VERSION "dbc-export 1 2026.26.6.5"

NS_ :

BS_:

BU_: APP BMS CC CMP CMPD CP DAS DI DIF DIR EPBL EPBR EVSE FC GTW HCML HCMR HVP ICR PCS PCS2 PLG PM PMF PMR PTC SCCM SCM SCS SDCR TAS UMC V2G VC VCBATT VCBATT0 VCBATT1 VCBATT2 VCFRONT VCFRONT1 VCFRONT2 VCLEFT VCRIGHT VCSEC

BO_ 611 VCRIGHT_logging10Hz: 8 VCRIGHT
 SG_ VCRIGHT_logging10HzIndex M : 0|3@1+ (1,0) [0|7] "" Vector__XXX
 SG_ VCRIGHT_hvacLHBleedTarget m0 : 3|8@1+ (0.4,0) [0|100] "%" Vector__XXX
 SG_ VCRIGHT_hvacRHBleedTarget m0 : 11|8@1+ (0.4,0) [0|100] "%" Vector__XXX
 SG_ VCRIGHT_hvacLHVaneTarget m0 : 19|8@1+ (0.4,0) [0|100] "%" Vector__XXX
 SG_ VCRIGHT_hvacRHVaneTarget m0 : 27|8@1+ (0.4,0) [0|100] "%" Vector__XXX
 SG_ VCRIGHT_hvacUpperModeTarget m0 : 35|10@1+ (0.1,0) [0|100] "%" Vector__XXX
 SG_ VCRIGHT_hvacLowerModeTarget m0 : 45|8@1+ (0.4,0) [0|100] "%" Vector__XXX
 SG_ VCRIGHT_hvacIntakeTarget m0 : 53|8@1+ (0.4,0) [0|100] "%" Vector__XXX
 SG_ VCRIGHT_hvacLHBleedPosition m1 : 3|8@1+ (0.4,0) [0|100] "%" Vector__XXX
 SG_ VCRIGHT_hvacRHBleedPosition m1 : 11|8@1+ (0.4,0) [0|100] "%" Vector__XXX
 SG_ VCRIGHT_hvacLHVanePosition m1 : 19|8@1+ (0.4,0) [0|100] "%" Vector__XXX
 SG_ VCRIGHT_hvacRHVanePosition m1 : 27|8@1+ (0.4,0) [0|100] "%" Vector__XXX
 SG_ VCRIGHT_hvacUpperModePosition m1 : 35|10@1+ (0.1,0) [0|100] "%" Vector__XXX
 SG_ VCRIGHT_hvacLowerModePosition m1 : 45|8@1+ (0.4,0) [0|100] "%" Vector__XXX
 SG_ VCRIGHT_hvacIntakePosition m1 : 53|8@1+ (0.4,0) [0|100] "%" Vector__XXX
 SG_ VCRIGHT_hvacLHBleedActuatorState m2 : 3|2@1+ (1,0) [0|3] "" Vector__XXX
 SG_ VCRIGHT_hvacRHBleedActuatorState m2 : 5|2@1+ (1,0) [0|3] "" Vector__XXX
 SG_ VCRIGHT_hvacLHVaneActuatorState m2 : 8|2@1+ (1,0) [0|3] "" Vector__XXX
 SG_ VCRIGHT_hvacRHVaneActuatorState m2 : 10|2@1+ (1,0) [0|3] "" Vector__XXX
 SG_ VCRIGHT_hvacUpperModeActState m2 : 12|2@1+ (1,0) [0|3] "" Vector__XXX
 SG_ VCRIGHT_hvacLowerModeActState m2 : 14|2@1+ (1,0) [0|3] "" Vector__XXX
 SG_ VCRIGHT_hvacIntakeActuatorState m2 : 16|2@1+ (1,0) [0|3] "" Vector__XXX
 SG_ VCRIGHT_hvacRearActuatorState m2 : 18|2@1+ (1,0) [0|3] "" Vector__XXX
 SG_ VCRIGHT_EvapPulldownBiasActive m2 : 20|1@1+ (1,0) [0|1] "" Vector__XXX
 SG_ VCRIGHT_tempDatLeftEst m2 : 21|9@1+ (0.5,-22) [-22|200] "degC" Vector__XXX
 SG_ VCRIGHT_tempDatRightEst m2 : 30|9@1+ (0.5,-22) [-22|200] "degC" Vector__XXX
 SG_ VCRIGHT_tempDuctLeftEst m2 : 40|8@1+ (0.5,-22) [-22|105] "degC" Vector__XXX
 SG_ VCRIGHT_tempDuctRightEst m2 : 48|8@1+ (0.5,-22) [-22|105] "degC" Vector__XXX
 SG_ VCRIGHT_ptcHeaterBadRodDetection m2 : 56|4@1+ (1,0) [0|15] "" Vector__XXX
 SG_ VCRIGHT_upperModeDrvActuatorStat m2 : 60|4@1+ (1,0) [0|15] "" Vector__XXX
 SG_ VCRIGHT_leftVerticalActuato_0001 m3 : 8|8@1+ (1,0) [0|255] "" Vector__XXX
 SG_ VCRIGHT_leftLateralActuatorStatu m3 : 16|8@1+ (1,0) [0|255] "" Vector__XXX
 SG_ VCRIGHT_rightVerticalActuat_0001 m3 : 24|8@1+ (1,0) [0|255] "" Vector__XXX
 SG_ VCRIGHT_rightLateralActuato_0001 m3 : 32|8@1+ (1,0) [0|255] "" Vector__XXX
 SG_ VCRIGHT_leftVerticalActuatorStat m3 : 40|4@1+ (1,0) [0|15] "" Vector__XXX
 SG_ VCRIGHT_leftLateralActuatorState m3 : 44|4@1+ (1,0) [0|15] "" Vector__XXX
 SG_ VCRIGHT_rightVerticalActuatorSta m3 : 48|4@1+ (1,0) [0|15] "" Vector__XXX
 SG_ VCRIGHT_rightLateralActuatorStat m3 : 52|4@1+ (1,0) [0|15] "" Vector__XXX
 SG_ VCRIGHT_windshieldRHExteriorSurf m3 : 56|8@1+ (1,0) [0|150] "%" Vector__XXX
 SG_ VCRIGHT_leftVerticalActuatorDuty m4 : 8|6@1- (4,0) [-100|100] "%" Vector__XXX
 SG_ VCRIGHT_leftLateralActuatorDuty m4 : 16|6@1- (4,0) [-100|100] "%" Vector__XXX
 SG_ VCRIGHT_rightVerticalActuatorDut m4 : 24|6@1- (4,0) [-100|100] "%" Vector__XXX
 SG_ VCRIGHT_rightLateralActuatorDuty m4 : 30|6@1- (4,0) [-100|100] "%" Vector__XXX
 SG_ VCRIGHT_frontLeftSeatTempTargetQ m4 : 36|6@1+ (0.75,20) [20|60] "degC" Vector__XXX
 SG_ VCRIGHT_frontRightSeatTempTarget m4 : 42|6@1+ (1,20) [20|60] "degC" Vector__XXX
 SG_ VCRIGHT_hvacRearPosition m4 : 48|8@1+ (0.4,0) [0|100] "%" Vector__XXX
 SG_ VCRIGHT_hvacRearTarget m4 : 56|8@1+ (0.4,0) [0|100] "%" Vector__XXX

BO_ 691 VCRIGHT_logging1Hz: 8 VCRIGHT
 SG_ VCRIGHT_logging1HzIndex M : 0|5@1+ (1,0) [0|31] "" Vector__XXX
 SG_ VCRIGHT_glareShieldHeaterState m0 : 5|3@1+ (1,0) [0|7] "" Vector__XXX
 SG_ VCRIGHT_tempIncarCabinProbe m0 : 8|8@1+ (0.5,-40) [-40|85] "degC" Vector__XXX
 SG_ VCRIGHT_cabinTempInteriorL2 m0 : 16|8@1+ (0.5,-40) [-40|80] "degC" Vector__XXX
 SG_ VCRIGHT_cabinTempInteriorSunnyL2 m0 : 24|8@1+ (0.6,-40) [-40|100] "degC" Vector__XXX
 SG_ VCRIGHT_tempIncarCabinMid m0 : 32|8@1+ (0.5,-40) [-40|85] "degC" Vector__XXX
 SG_ VCRIGHT_cabinTempInteriorL3 m0 : 40|8@1+ (0.5,-40) [-40|80] "degC" Vector__XXX
 SG_ VCRIGHT_cabinTempInteriorSunnyL3 m0 : 48|8@1+ (0.6,-40) [-40|100] "degC" Vector__XXX
 SG_ VCRIGHT_tempWetBulb m0 : 56|8@1+ (0.5,-40) [-40|80] "degC" Vector__XXX
 SG_ VCRIGHT_isRainingOrSnowing m1 : 5|1@1+ (1,0) [0|1] "" Vector__XXX
 SG_ VCRIGHT_cabinTempGlassRoof m1 : 8|8@1+ (0.5,-40) [-40|80] "degC" Vector__XXX
 SG_ VCRIGHT_cabinTempWindshield m1 : 16|8@1+ (0.5,-40) [-40|80] "degC" Vector__XXX
 SG_ VCRIGHT_cabinTempInterior m1 : 24|8@1+ (0.5,-40) [-40|80] "degC" Vector__XXX
 SG_ VCRIGHT_cabinTempInteriorSunny m1 : 32|8@1+ (0.6,-40) [-40|100] "degC" Vector__XXX
 SG_ VCRIGHT_cabinTempSideGlassLeft m1 : 40|8@1+ (0.5,-40) [-40|80] "degC" Vector__XXX
 SG_ VCRIGHT_cabinTempSideGlassRight m1 : 48|8@1+ (0.5,-40) [-40|80] "degC" Vector__XXX
 SG_ VCRIGHT_cabinTempBreathLevel m1 : 56|8@1+ (0.5,-40) [-40|80] "degC" Vector__XXX
 SG_ VCRIGHT_pcbaTemperature m2 : 5|11@1+ (0.125,-40) [-40|150] "degC" Vector__XXX
 SG_ VCRIGHT_wattsHeaterLeftTotal m2 : 16|10@1+ (5,0) [0|4000] "W" Vector__XXX
 SG_ VCRIGHT_wattsHeaterRightTotal m2 : 26|10@1+ (5,0) [0|4000] "W" Vector__XXX
 SG_ VCRIGHT_qdotLeftFFUnsat m2 : 36|9@1- (10,0) [-1500|1500] "W" Vector__XXX
 SG_ VCRIGHT_qdotRightFFUnsat m2 : 45|9@1- (10,0) [-1500|1500] "W" Vector__XXX
 SG_ VCRIGHT_nvhLevelDb m2 : 54|9@1+ (0.1,30) [30|80] "dB" Vector__XXX
 SG_ VCRIGHT_hvacSetTempActualLeft m3 : 8|8@1+ (0.1,15) [15|28] "degC" Vector__XXX
 SG_ VCRIGHT_hvacSetTempActualRight m3 : 16|8@1+ (0.1,15) [15|28] "degC" Vector__XXX
 SG_ VCRIGHT_hvacAutoTransitionReason m3 : 24|5@1+ (1,0) [0|31] "" Vector__XXX
 SG_ VCRIGHT_hvacMassflowTarget m3 : 29|8@1+ (1,0) [0|200] "g/s" Vector__XXX
 SG_ VCRIGHT_hvacQdotLimitedLeft m3 : 37|1@1+ (1,0) [0|1] "" Vector__XXX
 SG_ VCRIGHT_hvacQdotLimitedRight m3 : 38|1@1+ (1,0) [0|1] "" Vector__XXX
 SG_ VCRIGHT_LHPanelAirflowBlocked m3 : 39|1@1+ (1,0) [0|1] "" Vector__XXX
 SG_ VCRIGHT_RHPanelAirflowBlocked m3 : 40|1@1+ (1,0) [0|1] "" Vector__XXX
 SG_ VCRIGHT_floorAirflowBlocked m3 : 41|1@1+ (1,0) [0|1] "" Vector__XXX
 SG_ VCRIGHT_defrostAirflowBlocked m3 : 42|1@1+ (1,0) [0|1] "" Vector__XXX
 SG_ VCRIGHT_hvacFilterLifeDetectActi m3 : 43|1@1+ (1,0) [0|1] "" Vector__XXX
 SG_ VCRIGHT_hvacLHBleedOperationMode m3 : 44|1@1+ (1,0) [0|1] "" Vector__XXX
 SG_ VCRIGHT_hvacRHBleedOperationMode m3 : 45|1@1+ (1,0) [0|1] "" Vector__XXX
 SG_ VCRIGHT_hvacLHVaneOperationMode m3 : 46|1@1+ (1,0) [0|1] "" Vector__XXX
 SG_ VCRIGHT_hvacRHVaneOperationMode m3 : 47|1@1+ (1,0) [0|1] "" Vector__XXX
 SG_ VCRIGHT_hvacUpperModeOpMode m3 : 48|1@1+ (1,0) [0|1] "" Vector__XXX
 SG_ VCRIGHT_hvacLowerModeOpMode m3 : 49|1@1+ (1,0) [0|1] "" Vector__XXX
 SG_ VCRIGHT_hvacIntakeOperationMode m3 : 50|1@1+ (1,0) [0|1] "" Vector__XXX
 SG_ VCRIGHT_hvacRearOperationMode m3 : 51|1@1+ (1,0) [0|1] "" Vector__XXX
 SG_ VCRIGHT_isProbeFeedbackApplied m3 : 52|3@1+ (1,0) [0|7] "" Vector__XXX
 SG_ VCRIGHT_feedbackPullDownScalar m3 : 55|2@1+ (30,70) [70|130] "-" Vector__XXX
 SG_ VCRIGHT_feedForwardPullDownScala m3 : 57|6@1+ (1,70) [70|130] "-" Vector__XXX
 SG_ VCRIGHT_convectionTargetLeft m4 : 5|9@1+ (4,-1000) [-1000|1000] "W/m2" Vector__XXX
 SG_ VCRIGHT_convectionTargetRight m4 : 14|9@1+ (4,-1000) [-1000|1000] "W/m2" Vector__XXX
 SG_ VCRIGHT_convectionDeliveredLeft m4 : 23|9@1+ (4,-1000) [-1000|1000] "W/m2" Vector__XXX
 SG_ VCRIGHT_convectionDeliveredRight m4 : 32|9@1+ (4,-1000) [-1000|1000] "W/m2" Vector__XXX
 SG_ VCRIGHT_solarLoadRightOccupant m4 : 41|7@1+ (2,0) [0|252] "W/m2" Vector__XXX
 SG_ VCRIGHT_solarLoadLeftOccupant m4 : 48|7@1+ (2,0) [0|252] "W/m2" Vector__XXX
 SG_ VCRIGHT_ptcShutOutletMitigationA m4 : 55|1@1+ (1,0) [0|1] "" Vector__XXX
 SG_ VCRIGHT_solarLoadFromThsTemp m4 : 56|8@1+ (8,-1020) [-1020|1012] "W/m2" Vector__XXX
 SG_ VCRIGHT_hvacFoggingRiskLeve_0003 m5 : 5|6@1+ (1.6,0) [0|100] "%" Vector__XXX
 SG_ VCRIGHT_hvacFoggingRiskLeve_0004 m5 : 11|6@1+ (1.6,0) [0|100] "%" Vector__XXX
 SG_ VCRIGHT_hvacFoggingRiskLeve_0001 m5 : 17|6@1+ (1.6,0) [0|100] "%" Vector__XXX
 SG_ VCRIGHT_ptcHeaterTempDuctHigh m5 : 23|1@1+ (1,0) [0|1] "" Vector__XXX
 SG_ VCRIGHT_ptcHeaterTempDuctFault m5 : 24|1@1+ (1,0) [0|1] "" Vector__XXX
 SG_ VCRIGHT_ptcHeaterNoAirflow m5 : 25|1@1+ (1,0) [0|1] "" Vector__XXX
 SG_ VCRIGHT_ptcHeaterHvacActNotReady m5 : 26|1@1+ (1,0) [0|1] "" Vector__XXX
 SG_ VCRIGHT_ptcHeaterNoUiRequest m5 : 27|1@1+ (1,0) [0|1] "" Vector__XXX
 SG_ VCRIGHT_ptcHeaterNoHighVoltage m5 : 28|1@1+ (1,0) [0|1] "" Vector__XXX
 SG_ VCRIGHT_ptcHeaterLAirPathBlocked m5 : 29|1@1+ (1,0) [0|1] "" Vector__XXX
 SG_ VCRIGHT_ptcHeaterRAirPathBlocked m5 : 30|1@1+ (1,0) [0|1] "" Vector__XXX
 SG_ VCRIGHT_ptcHeaterReqAirpathBlock m5 : 31|1@1+ (1,0) [0|1] "" Vector__XXX
 SG_ VCRIGHT_hvacQdotFeedforward m5 : 32|16@1+ (1,-32767) [-32767|32767] "W" Vector__XXX
 SG_ VCRIGHT_cabinTempWshldDefog m5 : 48|8@1+ (0.5,-40) [-40|80] "degC" Vector__XXX
 SG_ VCRIGHT_cabinTempWshldDefogTop m5 : 56|8@1+ (0.5,-40) [-40|80] "degC" Vector__XXX
 SG_ VCRIGHT_hvacLHBleedVoltage m6 : 8|8@1+ (0.02,0) [0|5] "V" Vector__XXX
 SG_ VCRIGHT_hvacRHBleedVoltage m6 : 16|8@1+ (0.02,0) [0|5] "V" Vector__XXX
 SG_ VCRIGHT_hvacLHVaneVoltage m6 : 24|8@1+ (0.02,0) [0|5] "V" Vector__XXX
 SG_ VCRIGHT_hvacRHVaneVoltage m6 : 32|8@1+ (0.02,0) [0|5] "V" Vector__XXX
 SG_ VCRIGHT_hvacUpperModeVoltage m6 : 40|8@1+ (0.02,0) [0|5] "V" Vector__XXX
 SG_ VCRIGHT_hvacLowerModeVoltage m6 : 48|8@1+ (0.02,0) [0|5] "V" Vector__XXX
 SG_ VCRIGHT_hvacIntakeVoltage m6 : 56|8@1+ (0.02,0) [0|5] "V" Vector__XXX
 SG_ VCRIGHT_cabinTempBreathLevelFHea m7 : 5|8@1+ (0.5,-40) [-40|80] "degC" Vector__XXX
 SG_ VCRIGHT_cabinTempBreathLevelFCoo m7 : 13|8@1+ (0.5,-40) [-40|80] "degC" Vector__XXX
 SG_ VCRIGHT_hvacTorqueMassflowLinear m7 : 21|8@1+ (1,0) [0|250] "g/s" Vector__XXX
 SG_ VCRIGHT_hvacTorqueMassflowEstima m7 : 29|3@1+ (1,0) [0|7] "" Vector__XXX
 SG_ VCRIGHT_hvacFoggingRiskLevelCons m7 : 32|6@1+ (1.6,0) [0|100] "%" Vector__XXX
 SG_ VCRIGHT_hvacWindshieldRHConserva m7 : 38|6@1+ (2,0) [0|125] "%" Vector__XXX
 SG_ VCRIGHT_hvacFoggingRiskLevelFeed m7 : 44|7@1- (1.6,0) [-100|100] "%" Vector__XXX
 SG_ VCRIGHT_hvacFoggingRiskLevelInte m7 : 51|7@1- (1.6,0) [-100|100] "%" Vector__XXX
 SG_ VCRIGHT_hvacFoggingRiskLeve_0002 m7 : 58|6@1+ (1.6,0) [0|100] "%" Vector__XXX
 SG_ VCRIGHT_hvacCabOvrheatProtActive m8 : 5|1@1+ (1,0) [0|1] "" Vector__XXX
 SG_ VCRIGHT_hvacCabinPurgeAllowed m8 : 6|1@1+ (1,0) [0|1] "" Vector__XXX
 SG_ VCRIGHT_hvacCabOvrheatProtAllowe m8 : 7|1@1+ (1,0) [0|1] "" Vector__XXX
 SG_ VCRIGHT_AP_humidityModelBasedCab m8 : 8|10@1+ (0.04,0) [0|40] "g/kg" Vector__XXX
 SG_ VCRIGHT_cabinTempFanCurrent m8 : 18|6@1+ (0.001,-0.01) [-0.01|0.05] "A" Vector__XXX
 SG_ VCRIGHT_cabinTempFanOutput m8 : 24|1@1+ (1,0) [0|1] "" Vector__XXX
 SG_ VCRIGHT_cloudinessEstimatedPct m8 : 25|7@1+ (1,0) [0|100] "%" Vector__XXX
 SG_ VCRIGHT_solarLoadOnVehFiltered m8 : 32|8@1+ (4,0) [0|1016] "W/m2" Vector__XXX
 SG_ VCRIGHT_cabinTempProbeEstimate m8 : 40|8@1+ (0.5,-40) [-40|80] "degC" Vector__XXX
 SG_ VCRIGHT_cabinTempThs m8 : 48|8@1+ (0.5,-40) [-40|80] "degC" Vector__XXX
 SG_ VCRIGHT_cabinTempThsBracket m8 : 56|8@1+ (0.5,-40) [-40|80] "degC" Vector__XXX
 SG_ VCRIGHT_leftHeatOvertempProtect m9 : 5|1@1+ (1,0) [0|1] "" Vector__XXX
 SG_ VCRIGHT_rightHeatOvertempProtect m9 : 6|1@1+ (1,0) [0|1] "" Vector__XXX
 SG_ VCRIGHT_CO2ppm m9 : 7|10@1+ (5,0) [0|4000] "-" Vector__XXX
 SG_ VCRIGHT_timeLeftToCabinModelInit m9 : 17|7@1+ (1,0) [0|127] "" Vector__XXX
 SG_ VCRIGHT_hvacEstimateWindshieldRH m9 : 24|8@1+ (1,0) [0|150] "%" Vector__XXX
 SG_ VCRIGHT_hvacFoggingRiskLevel m9 : 32|7@1+ (1,0) [0|100] "%" Vector__XXX
 SG_ VCRIGHT_hvacCabinHumidityLevel m9 : 39|7@1+ (1,0) [0|100] "%" Vector__XXX
 SG_ VCRIGHT_hvacFlashFoggingDetected m9 : 47|1@1+ (1,0) [0|1] "" Vector__XXX
 SG_ VCRIGHT_solarSensitivityInfr m9 : 48|7@1+ (1,0) [0|100] "-" Vector__XXX
 SG_ VCRIGHT_solarSensitivityInfrCorr m9 : 55|7@1+ (1,0) [0|100] "-" Vector__XXX
 SG_ VCRIGHT_lumbarCurrent m10 : 5|4@1+ (0.2,0) [0|3] "A" Vector__XXX
 SG_ VCRIGHT_ocsCurrent m10 : 9|3@1+ (0.01,0) [0|0.07] "A" Vector__XXX
 SG_ VCRIGHT_rcmCurrent m10 : 12|5@1+ (0.1,0) [0|3.1] "A" Vector__XXX
 SG_ VCRIGHT_radioTunerCurrent m10 : 17|4@1+ (0.1,0) [0|1.5] "A" Vector__XXX
 SG_ VCRIGHT_rearOilPumpCurrent m10 : 21|5@1+ (0.5,0) [0|15.5] "A" Vector__XXX
 SG_ VCRIGHT_rearDefrostCurrent m10 : 26|5@1+ (2,0) [0|62] "A" Vector__XXX
 SG_ VCRIGHT_tailLightCurrent m10 : 31|4@1+ (0.1,0) [0|1.5] "A" Vector__XXX
 SG_ VCRIGHT_turnTailStopLightCurrent m10 : 35|4@1+ (0.1,0) [0|1.5] "A" Vector__XXX
 SG_ VCRIGHT_reverseFogLightsCurrent m10 : 39|4@1+ (0.1,0) [0|1.4] "A" Vector__XXX
 SG_ VCRIGHT_stopReverseTurnLightCurr m10 : 43|4@1+ (0.1,0) [0|1.5] "A" Vector__XXX
 SG_ VCRIGHT_sideMirrorCurrent m10 : 47|5@1+ (0.2,0) [0|6.2] "A" Vector__XXX
 SG_ VCRIGHT_sideMirrorHeaterCurrent m10 : 52|5@1+ (0.2,0) [0|6] "A" Vector__XXX
 SG_ VCRIGHT_frontSeatHeatCushionPwr m10 : 57|7@1+ (1,0) [0|127] "W" Vector__XXX
 SG_ VCRIGHT_trunkInteriorLEDCurrent m11 : 8|4@1+ (5,0) [0|70] "mA" Vector__XXX
 SG_ VCRIGHT_mapPocketLEDsCurrent m11 : 12|4@1+ (5,0) [0|70] "mA" Vector__XXX
 SG_ VCRIGHT_miscEFuseCurrent m11 : 16|5@1+ (0.05,0) [0|1.5] "A" Vector__XXX
 SG_ VCRIGHT_interiorHandleLEDCurrent m11 : 21|4@1+ (2,0) [0|30] "mA" Vector__XXX
 SG_ VCRIGHT_miscInteriorLightsCurren m11 : 25|3@1+ (5,0) [0|30] "mA" Vector__XXX
 SG_ VCRIGHT_frontPuddleLEDCurrent m11 : 28|3@1+ (0.05,0) [0|0.3] "A" Vector__XXX
 SG_ VCRIGHT_rearPuddleLEDCurrent m11 : 31|3@1+ (0.05,0) [0|0.3] "A" Vector__XXX
 SG_ VCRIGHT_liftgateShutfaceLEDCurre m11 : 34|3@1+ (5,0) [0|30] "mA" Vector__XXX
 SG_ VCRIGHT_3rSeatTOSCurrent m11 : 37|4@1+ (5,0) [0|70] "mA" Vector__XXX
 SG_ VCRIGHT_vbatFusedCurrent m11 : 41|4@1+ (0.1,0) [0|1.4] "A" Vector__XXX
 SG_ VCRIGHT_cabinTempGlassGridHeater m11 : 45|8@1+ (0.5,-40) [-40|80] "degC" Vector__XXX
 SG_ VCRIGHT_hvacAirflowReasonRight m11 : 53|5@1+ (1,0) [0|31] "" Vector__XXX
 SG_ VCRIGHT_hvacAirflowReasonLeft m11 : 58|5@1+ (1,0) [0|31] "" Vector__XXX
 SG_ VCRIGHT_hvacMassflowTargetLeft m12 : 5|8@1+ (1,0) [0|200] "g/s" Vector__XXX
 SG_ VCRIGHT_hvacMassflowTargetRight m12 : 13|8@1+ (1,0) [0|200] "g/s" Vector__XXX
 SG_ VCRIGHT_solarLoadLeftOccupantFil m12 : 21|7@1+ (2,0) [0|252] "W/m2" Vector__XXX
 SG_ VCRIGHT_solarLoadRightOccupantFi m12 : 28|7@1+ (2,0) [0|252] "W/m2" Vector__XXX
 SG_ VCRIGHT_windshieldRHCapped m12 : 35|8@1+ (1,0) [0|150] "%" Vector__XXX
 SG_ VCRIGHT_feedbackWarmUpScalar m12 : 43|2@1+ (16,84) [84|116] "-" Vector__XXX
 SG_ VCRIGHT_maxMassflowScalarWarmUp m12 : 45|5@1+ (1,74) [74|100] "-" Vector__XXX
 SG_ VCRIGHT_feedforwardWarmUpScalar m12 : 50|6@1+ (1,80) [80|120] "-" Vector__XXX
 SG_ VCRIGHT_frontSeatHeatBackrestPwr m12 : 56|7@1+ (1,0) [0|127] "W" Vector__XXX
 SG_ VCRIGHT_maxMassflowScalar m13 : 5|6@1+ (1,60) [60|100] "-" Vector__XXX
 SG_ VCRIGHT_massflowTargetAutoInManu m13 : 11|8@1+ (1,0) [0|250] "g/s" Vector__XXX
 SG_ VCRIGHT_airflowReasonAutoInManua m13 : 19|5@1+ (1,0) [0|31] "" Vector__XXX
 SG_ VCRIGHT_airflowReasonAutoIn_0001 m13 : 24|5@1+ (1,0) [0|31] "" Vector__XXX
 SG_ VCRIGHT_airflowReasonAutoIn_0002 m13 : 29|5@1+ (1,0) [0|31] "" Vector__XXX
 SG_ VCRIGHT_hvacTorqueMassflowQuadra m13 : 34|8@1+ (1,0) [0|250] "g/s" Vector__XXX
 SG_ VCRIGHT_vocSweatMassSeat m13 : 42|8@1+ (1,0) [0|254] "mg" Vector__XXX
 SG_ VCRIGHT_vocSweatConcentrationAir m13 : 50|8@1+ (0.1,0) [0|25.4] "mg/m3" Vector__XXX
 SG_ VCRIGHT_hvacBiLevelWhsldRhEst m13 : 58|6@1+ (2,20) [20|120] "%" Vector__XXX
 SG_ VCRIGHT_steeringWheelSurfaceTemp m14 : 5|10@1+ (0.1,-35) [-35|65] "degC" Vector__XXX
 SG_ VCRIGHT_steeringWheelSurfac_0001 m14 : 16|10@1+ (0.1,-35) [-35|65] "degC" Vector__XXX
 SG_ VCRIGHT_timeToComfortHeating m14 : 26|6@1+ (15,-15) [-15|930] "s" Vector__XXX
 SG_ VCRIGHT_timeToComfortCooling m14 : 32|6@1+ (15,-15) [-15|930] "s" Vector__XXX
 SG_ VCRIGHT_cabinWaterMassRaw m14 : 38|8@1+ (0.1,0) [0|25] "g/kg" Vector__XXX
 SG_ VCRIGHT_massflowSingleZoneSplit m14 : 46|7@1+ (1,0) [0|100] "-" Vector__XXX
 SG_ VCRIGHT_VOCPurgeState m14 : 53|3@1+ (1,0) [0|7] "" Vector__XXX
 SG_ VCRIGHT_cameraFoggingMonitorStat m14 : 56|3@1+ (1,0) [0|7] "" Vector__XXX
 SG_ VCRIGHT_windWeatherSource m14 : 59|2@1+ (1,0) [0|3] "" Vector__XXX
 SG_ VCRIGHT_humidityRatioWeatherSour m14 : 61|2@1+ (1,0) [0|3] "" Vector__XXX
 SG_ VCRIGHT_cabinOverheatProtectNotR m15 : 5|14@1+ (1,0) [0|16383] "" Vector__XXX
 SG_ VCRIGHT_hvacIntakeReason m15 : 19|5@1+ (1,0) [0|31] "" Vector__XXX
 SG_ VCRIGHT_hvacCabinPurgeActive m15 : 24|1@1+ (1,0) [0|1] "" Vector__XXX
 SG_ VCRIGHT_solarAzimuthCarRef m15 : 25|11@1- (0.5,0) [-511|511.5] "deg" Vector__XXX
 SG_ VCRIGHT_massflowPulldownBias m15 : 36|4@1+ (7,0) [0|100] "%" Vector__XXX
 SG_ VCRIGHT_evapPulldownBias m15 : 40|4@1+ (7,0) [0|100] "%" Vector__XXX
 SG_ VCRIGHT_modeledMassflowFresh m15 : 44|8@1+ (1,0) [0|255] "g/s" Vector__XXX
 SG_ VCRIGHT_modeledMassflowRecirc m15 : 52|8@1+ (1,0) [0|255] "g/s" Vector__XXX
 SG_ VCRIGHT_hvacLimpModeStatus m15 : 60|3@1+ (1,0) [0|7] "" Vector__XXX
 SG_ VCRIGHT_hvacEstimatedCameraWinds m16 : 5|8@1+ (1,0) [0|150] "%" Vector__XXX
 SG_ VCRIGHT_hvacRearVoltage m16 : 13|8@1+ (0.02,0) [0|5] "V" Vector__XXX
 SG_ VCRIGHT_cabinTempRoofL2 m16 : 21|8@1+ (0.5,-40) [-40|85] "degC" Vector__XXX
 SG_ VCRIGHT_cabinTempRoofL3 m16 : 29|8@1+ (0.5,-40) [-40|85] "degC" Vector__XXX
 SG_ VCRIGHT_odorRoutineState m16 : 37|3@1+ (1,0) [0|6] "" Vector__XXX
 SG_ VCRIGHT_rgbLedFrontCurrent m16 : 40|10@1+ (0.000488758552819,0) [0|0.499999999534] "A" Vector__XXX
 SG_ VCRIGHT_rgbLedRearCurrent m16 : 50|10@1+ (0.000488758552819,0) [0|0.499999999534] "A" Vector__XXX
 SG_ VCRIGHT_rgbLedFrontOutput m16 : 60|1@1+ (1,0) [0|1] "" Vector__XXX
 SG_ VCRIGHT_rgbLedRearOutput m16 : 61|1@1+ (1,0) [0|1] "" Vector__XXX
 SG_ VCRIGHT_cameraDefogState m16 : 62|2@1+ (1,0) [0|3] "" Vector__XXX

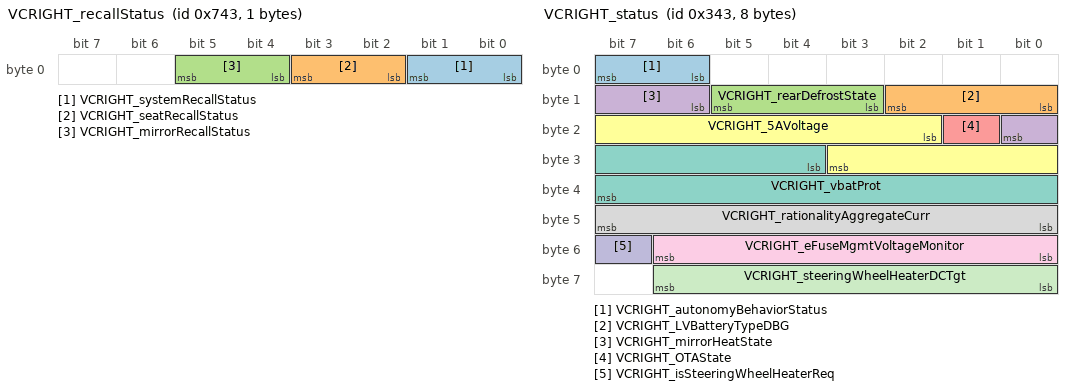
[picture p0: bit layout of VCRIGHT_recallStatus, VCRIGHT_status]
BO_ 1859 VCRIGHT_recallStatus: 1 VCRIGHT
 SG_ VCRIGHT_systemRecallStatus : 0|2@1+ (1,0) [1|3] "" Vector__XXX
 SG_ VCRIGHT_seatRecallStatus : 2|2@1+ (1,0) [1|3] "" Vector__XXX
 SG_ VCRIGHT_mirrorRecallStatus : 4|2@1+ (1,0) [1|3] "" Vector__XXX

BO_ 1251 VCRIGHT_seatStatus: 8 VCRIGHT
 SG_ VCRIGHT_seatStatusIndex M : 0|3@1+ (1,0) [0|7] "" Vector__XXX
 SG_ VC_AH_1RowRightSeatMovementHealt m0 : 5|3@1+ (1,0) [0|7] "" Vector__XXX
 SG_ VCRIGHT_frontSeatTrackPos m0 : 8|16@1- (1,0) [-32768|32767] "" Vector__XXX
 SG_ VCRIGHT_frontSeatTrackCurrent m0 : 24|12@1- (0.01,0) [-20.48|20.47] "A" Vector__XXX
 SG_ VCRIGHT_frontSeatTrackDuty m0 : 36|12@1- (0.1,0) [-204.8|204.7] "%" Vector__XXX
 SG_ VCRIGHT_frontSeatTrackState m0 : 48|3@1+ (1,0) [0|7] "" Vector__XXX
 SG_ VCRIGHT_frontSeatTrackCalibrated m0 : 51|1@1+ (1,0) [0|1] "" Vector__XXX
 SG_ VCRIGHT_frontSeatTrackLog m0 : 52|1@1+ (1,0) [0|1] "" Vector__XXX
 SG_ VCRIGHT_frontSeatTrackBridgeSt m0 : 53|2@1+ (1,0) [0|3] "" Vector__XXX
 SG_ VCRIGHT_frontSeatTrackPercentage m0 : 55|7@1+ (1,0) [0|100] "%" Vector__XXX
 SG_ VCRIGHT_frontSeatBackPos m1 : 8|16@1- (1,0) [-32768|32767] "" Vector__XXX
 SG_ VCRIGHT_frontSeatBackCurrent m1 : 24|12@1- (0.01,0) [-20.48|20.47] "A" Vector__XXX
 SG_ VCRIGHT_frontSeatBackDuty m1 : 36|12@1- (0.1,0) [-204.8|204.7] "%" Vector__XXX
 SG_ VCRIGHT_frontSeatBackState m1 : 48|3@1+ (1,0) [0|7] "" Vector__XXX
 SG_ VCRIGHT_frontSeatBackCalibrated m1 : 51|1@1+ (1,0) [0|1] "" Vector__XXX
 SG_ VCRIGHT_frontSeatBackLog m1 : 52|1@1+ (1,0) [0|1] "" Vector__XXX
 SG_ VCRIGHT_frontSeatBackBridgeSt m1 : 53|2@1+ (1,0) [0|3] "" Vector__XXX
 SG_ VCRIGHT_frontSeatBackPercentage m1 : 55|7@1+ (1,0) [0|100] "%" Vector__XXX
 SG_ VCRIGHT_frontSeatLiftPos m2 : 8|16@1- (1,0) [-32768|32767] "" Vector__XXX
 SG_ VCRIGHT_frontSeatLiftCurrent m2 : 24|12@1- (0.01,0) [-20.48|20.47] "A" Vector__XXX
 SG_ VCRIGHT_frontSeatLiftDuty m2 : 36|12@1- (0.1,0) [-204.8|204.7] "%" Vector__XXX
 SG_ VCRIGHT_frontSeatLiftState m2 : 48|3@1+ (1,0) [0|7] "" Vector__XXX
 SG_ VCRIGHT_frontSeatLiftCalibrated m2 : 51|1@1+ (1,0) [0|1] "" Vector__XXX
 SG_ VCRIGHT_frontSeatLiftLog m2 : 52|1@1+ (1,0) [0|1] "" Vector__XXX
 SG_ VCRIGHT_frontSeatLiftBridgeSt m2 : 53|2@1+ (1,0) [0|3] "" Vector__XXX
 SG_ VCRIGHT_frontSeatLiftPercentage m2 : 55|7@1+ (1,0) [0|100] "%" Vector__XXX
 SG_ VCRIGHT_frontSeatTiltPos m3 : 8|16@1- (1,0) [-32768|32767] "" Vector__XXX
 SG_ VCRIGHT_frontSeatTiltCurrent m3 : 24|12@1- (0.01,0) [-20.48|20.47] "A" Vector__XXX
 SG_ VCRIGHT_frontSeatTiltDuty m3 : 36|12@1- (0.1,0) [-204.8|204.7] "%" Vector__XXX
 SG_ VCRIGHT_frontSeatTiltState m3 : 48|3@1+ (1,0) [0|7] "" Vector__XXX
 SG_ VCRIGHT_frontSeatTiltCalibrated m3 : 51|1@1+ (1,0) [0|1] "" Vector__XXX
 SG_ VCRIGHT_frontSeatTiltLog m3 : 52|1@1+ (1,0) [0|1] "" Vector__XXX
 SG_ VCRIGHT_frontSeatTiltBridgeSt m3 : 53|2@1+ (1,0) [0|3] "" Vector__XXX
 SG_ VCRIGHT_frontSeatTiltPercentage m3 : 55|7@1+ (1,0) [0|100] "%" Vector__XXX
 SG_ VCRIGHT_lumbarAState m4 : 3|3@1+ (1,0) [0|7] "" Vector__XXX
 SG_ VCRIGHT_lumbarBState m4 : 6|3@1+ (1,0) [0|7] "" Vector__XXX
 SG_ VCRIGHT_lumbarAPressureHpa m4 : 9|12@1+ (1,0) [0|4095] "" Vector__XXX
 SG_ VCRIGHT_lumbarAPressureHpaFilt m4 : 21|10@1+ (1,0) [0|1023] "" Vector__XXX
 SG_ VCRIGHT_lumbarBPressureHpa m4 : 31|12@1+ (1,0) [0|4095] "" Vector__XXX
 SG_ VCRIGHT_lumbarBPressureHpaFilt m4 : 43|10@1+ (1,0) [0|1023] "" Vector__XXX
 SG_ VCRIGHT_lumbarActiveTooLongErr m4 : 53|1@1+ (1,0) [0|1] "" Vector__XXX
 SG_ VCRIGHT_lumbarMaxPErr m4 : 54|1@1+ (1,0) [0|1] "" Vector__XXX
 SG_ VCRIGHT_lumbarOvercurrentErr m4 : 55|1@1+ (1,0) [0|1] "" Vector__XXX
 SG_ VCRIGHT_lumbarMaxOperatingPErr m4 : 56|1@1+ (1,0) [0|1] "" Vector__XXX
 SG_ VCRIGHT_lumbarMinPErr m4 : 57|1@1+ (1,0) [0|1] "" Vector__XXX
 SG_ VCRIGHT_lumbarGeneralErr m4 : 58|1@1+ (1,0) [0|1] "" Vector__XXX
 SG_ VCRIGHT_lumbarDevMaxPumpPressA m4 : 59|1@1+ (1,0) [0|1] "" Vector__XXX
 SG_ VCRIGHT_lumbarDevMaxPumpPressB m4 : 60|1@1+ (1,0) [0|1] "" Vector__XXX
 SG_ VCRIGHT_frontSeatTrackPosReal m5 : 3|12@1- (1,0) [-2048|2047] "mm" Vector__XXX
 SG_ VCRIGHT_frontSeatBackPosReal m5 : 16|12@1- (0.1,0) [-204.8|204.7] "deg" Vector__XXX
 SG_ VCRIGHT_frontSeatLiftPosReal m5 : 28|12@1- (1,0) [-2048|2047] "mm" Vector__XXX
 SG_ VCRIGHT_frontSeatTiltPosReal m5 : 40|12@1- (0.1,0) [-204.8|204.7] "deg" Vector__XXX
 SG_ VCRIGHT_frontSeatThighSuppo_0001 m5 : 52|12@1- (1,0) [-2048|2047] "mm" Vector__XXX
 SG_ VCRIGHT_frontSeatTrackPosOffset m6 : 3|12@1- (1,0) [-2048|2047] "mm" Vector__XXX
 SG_ VCRIGHT_frontSeatBackPosOffset m6 : 16|12@1- (0.1,0) [-204.8|204.7] "deg" Vector__XXX
 SG_ VCRIGHT_frontSeatLiftPosOffset m6 : 28|12@1- (1,0) [-2048|2047] "mm" Vector__XXX
 SG_ VCRIGHT_frontSeatTiltPosOffset m6 : 40|12@1- (0.1,0) [-204.8|204.7] "deg" Vector__XXX
 SG_ VCRIGHT_frontSeatThighSupportPos m6 : 52|12@1- (1,0) [-2048|2047] "mm" Vector__XXX
 SG_ VCRIGHT_lumbarAPressurePercentag m7 : 3|7@1+ (1,0) [0|100] "%" Vector__XXX
 SG_ VCRIGHT_lumbarBPressurePercentag m7 : 10|7@1+ (1,0) [0|100] "%" Vector__XXX

BO_ 739 VCRIGHT_seatStatus2: 7 VCRIGHT
 SG_ VCRIGHT_seatStatus2Index M : 0|4@1+ (1,0) [0|15] "" Vector__XXX
 SG_ VCRIGHT_frontSeatHeatCurrent m0 : 4|12@1+ (0.01,0) [0|40.95] "A" Vector__XXX
 SG_ VCRIGHT_frontSeatHeatDuty m0 : 16|8@1+ (1,0) [0|255] "%" Vector__XXX
 SG_ VCRIGHT_frontSeatHeatTmp m0 : 24|12@1- (0.05,0) [-40|80] "degC" Vector__XXX
 SG_ VCRIGHT_frontSeatHeatTmpTarget m0 : 36|8@1- (0.5,0) [0|60] "degC" Vector__XXX
 SG_ VCRIGHT_frontSeatHeatInhibited m0 : 44|1@1+ (1,0) [0|1] "" Vector__XXX
 SG_ VCRIGHT_frontSeatHeatPowered m0 : 45|1@1+ (1,0) [0|1] "" Vector__XXX
 SG_ VC_AH_1RowRightSeatHeatVentHealt m0 : 54|2@1+ (1,0) [0|3] "" Vector__XXX
 SG_ VCRIGHT_rearLSeatHeatCurrent m1 : 4|12@1+ (0.01,0) [0|40.95] "A" Vector__XXX
 SG_ VCRIGHT_rearLSeatHeatDuty m1 : 16|8@1+ (1,0) [0|255] "%" Vector__XXX
 SG_ VCRIGHT_rearLSeatHeatTmp m1 : 24|12@1- (0.05,0) [-40|80] "degC" Vector__XXX
 SG_ VCRIGHT_rearLSeatHeatTmpTarget m1 : 36|8@1- (0.5,0) [0|60] "degC" Vector__XXX
 SG_ VCRIGHT_rearLSeatHeatInhibited m1 : 44|1@1+ (1,0) [0|1] "" Vector__XXX
 SG_ VCRIGHT_rearLSeatHeatPowered m1 : 45|1@1+ (1,0) [0|1] "" Vector__XXX
 SG_ VCRIGHT_rearCSeatHeatCurrent m2 : 4|12@1+ (0.01,0) [0|40.95] "A" Vector__XXX
 SG_ VCRIGHT_rearCSeatHeatDuty m2 : 16|8@1+ (1,0) [0|255] "%" Vector__XXX
 SG_ VCRIGHT_rearCSeatHeatTmp m2 : 24|12@1- (0.05,0) [-40|80] "degC" Vector__XXX
 SG_ VCRIGHT_rearCSeatHeatTmpTarget m2 : 36|8@1- (0.5,0) [0|60] "degC" Vector__XXX
 SG_ VCRIGHT_rearCSeatHeatInhibited m2 : 44|1@1+ (1,0) [0|1] "" Vector__XXX
 SG_ VCRIGHT_rearCSeatHeatPowered m2 : 45|1@1+ (1,0) [0|1] "" Vector__XXX
 SG_ VCRIGHT_rearRSeatHeatCurrent m3 : 4|12@1+ (0.01,0) [0|40.95] "A" Vector__XXX
 SG_ VCRIGHT_rearRSeatHeatDuty m3 : 16|8@1+ (1,0) [0|255] "%" Vector__XXX
 SG_ VCRIGHT_rearRSeatHeatTmp m3 : 24|12@1- (0.05,0) [-40|80] "degC" Vector__XXX
 SG_ VCRIGHT_rearRSeatHeatTmpTarget m3 : 36|8@1- (0.5,0) [0|60] "degC" Vector__XXX
 SG_ VCRIGHT_rearRSeatHeatInhibited m3 : 44|1@1+ (1,0) [0|1] "" Vector__XXX
 SG_ VCRIGHT_rearRSeatHeatPowered m3 : 45|1@1+ (1,0) [0|1] "" Vector__XXX
 SG_ VCRIGHT_2RowSeatReclineState m11 : 4|4@1+ (1,0) [0|14] "" Vector__XXX
 SG_ VCRIGHT_2RowSeatReclineDuty m11 : 8|8@1- (1,0) [-100|100] "%" Vector__XXX
 SG_ VCRIGHT_2RowSeatReclineCurrent m11 : 16|12@1- (0.05,0) [-100|100] "A" Vector__XXX
 SG_ VCRIGHT_2RowSeatReclineCalibrate m11 : 28|1@1+ (1,0) [0|1] "" Vector__XXX
 SG_ VCRIGHT_2RowSeatReclinePositionR m11 : 29|12@1- (1,0) [-2048|2047] "" Vector__XXX
 SG_ VCRIGHT_2RowSeatReclineAngle m11 : 41|12@1- (0.1,0) [-204.8|204.7] "deg" Vector__XXX
 SG_ VCRIGHT_2RowSeatReclineAbsPosSwi m11 : 53|2@1+ (1,0) [1|3] "" Vector__XXX
 SG_ VCRIGHT_2RowSeatReclinePositionS m12 : 4|3@1+ (1,0) [0|7] "" Vector__XXX
 SG_ VCRIGHT_2RowSeatReclineAdjustmen m12 : 7|1@1+ (1,0) [0|1] "" Vector__XXX
 SG_ VCRIGHT_2RowSeatReclineFoldAllow m12 : 8|1@1+ (1,0) [0|1] "" Vector__XXX
 SG_ VCRIGHT_2RowSeatReclineUnfoldAll m12 : 9|1@1+ (1,0) [0|1] "" Vector__XXX
 SG_ VCRIGHT_2RowSeatReclineNextToggl m12 : 10|2@1+ (1,0) [0|3] "" Vector__XXX
 SG_ VCRIGHT_2RowSeatReclineChoreoBlo m12 : 12|1@1+ (1,0) [0|1] "" Vector__XXX
 SG_ VCRIGHT_2RowSeat1RClashAvoidance m12 : 13|3@1+ (1,0) [0|7] "" Vector__XXX
 SG_ VCRIGHT_2RowSeat1RClashAvoi_0001 m12 : 16|2@1+ (1,0) [0|3] "" Vector__XXX
 SG_ VCRIGHT_2RowSeatReclineAbsP_0001 m12 : 18|12@1- (0.1,0) [-204.8|204.7] "deg" Vector__XXX
 SG_ VC_AH_2RowRightSeatMovementHealt m12 : 53|3@1+ (1,0) [0|7] "" Vector__XXX
 SG_ VCRIGHT_3RowSeatReclineState m14 : 4|4@1+ (1,0) [0|14] "" Vector__XXX
 SG_ VCRIGHT_3RowSeatReclineDuty m14 : 8|8@1- (1,0) [-100|100] "%" Vector__XXX
 SG_ VCRIGHT_3RowSeatReclineCurrent m14 : 16|12@1- (0.05,0) [-100|100] "A" Vector__XXX
 SG_ VCRIGHT_3RowSeatReclineCalibrate m14 : 28|1@1+ (1,0) [0|1] "" Vector__XXX
 SG_ VCRIGHT_3RowSeatReclinePositionR m14 : 29|12@1- (1,0) [-2048|2047] "" Vector__XXX
 SG_ VCRIGHT_3RowSeatReclineAngle m14 : 41|12@1- (0.1,0) [-204.8|204.7] "deg" Vector__XXX
 SG_ VCRIGHT_3RowSeatReclineNextToggl m14 : 53|2@1+ (1,0) [0|3] "" Vector__XXX
 SG_ VCRIGHT_3RRightSeatHeatCurrent m15 : 5|12@1+ (0.01,0) [0|40.95] "A" Vector__XXX
 SG_ VCRIGHT_3RRightSeatHeatDuty m15 : 17|8@1- (1,0) [-100|100] "%" Vector__XXX
 SG_ VCRIGHT_3RRightSeatHeatTmp m15 : 25|12@1- (0.05,0) [-40|80] "degC" Vector__XXX
 SG_ VCRIGHT_3RRightSeatHeatTmpTarget m15 : 37|8@1- (0.5,0) [0|60] "degC" Vector__XXX
 SG_ VCRIGHT_3RRightSeatHeatInhibited m15 : 45|1@1+ (1,0) [0|1] "" Vector__XXX
 SG_ VCRIGHT_3RowSeatReclinePositionS m15 : 46|3@1+ (1,0) [0|7] "" Vector__XXX
 SG_ VCRIGHT_3RowSeatReclineAdjustmen m15 : 49|1@1+ (1,0) [0|1] "" Vector__XXX
 SG_ VCRIGHT_3RowSeatReclineFoldAllow m15 : 50|1@1+ (1,0) [0|1] "" Vector__XXX
 SG_ VCRIGHT_3RowSeatReclineUnfoldAll m15 : 51|1@1+ (1,0) [0|1] "" Vector__XXX
 SG_ VCRIGHT_3RowSeatReclineChoreoBlo m15 : 52|1@1+ (1,0) [0|1] "" Vector__XXX
 SG_ VCRIGHT_3RowSeatReclineAbsPosSwi m15 : 53|2@1+ (1,0) [1|3] "" Vector__XXX

BO_ 835 VCRIGHT_status: 8 VCRIGHT
 SG_ VCRIGHT_autonomyBehaviorStatus : 6|2@1+ (1,0) [0|3] "" Vector__XXX
 SG_ VCRIGHT_LVBatteryTypeDBG : 8|3@1+ (1,0) [0|7] "" Vector__XXX
 SG_ VCRIGHT_rearDefrostState : 11|3@1+ (1,0) [1|7] "" Vector__XXX
 SG_ VCRIGHT_mirrorHeatState : 14|3@1+ (1,0) [1|7] "" Vector__XXX
 SG_ VCRIGHT_OTAState : 17|1@1+ (1,0) [0|1] "" Vector__XXX
 SG_ VCRIGHT_5AVoltage : 18|10@1+ (0.005443676,0) [0|5.568880548] "V" Vector__XXX
 SG_ VCRIGHT_vbatProt : 28|12@1+ (0.005443676,0) [0|22.29185322] "V" Vector__XXX
 SG_ VCRIGHT_rationalityAggregateCurr : 40|8@1+ (0.5,0) [0|127.5] "A" Vector__XXX
 SG_ VCRIGHT_eFuseMgmtVoltageMonitor : 48|7@1+ (0.125,0) [0|15.875] "V" Vector__XXX
 SG_ VCRIGHT_isSteeringWheelHeaterReq : 55|1@1+ (1,0) [0|1] "" Vector__XXX
 SG_ VCRIGHT_steeringWheelHeaterDCTgt : 56|7@1+ (0.01,0) [0|1] "-" Vector__XXX

BO_ 963 VCRIGHT_switchStatus: 8 VCRIGHT
 SG_ VCRIGHT_switchStatusIndex M : 0|1@1+ (1,0) [0|1] "" Vector__XXX
 SG_ VCRIGHT_frontBuckleSwitch m0 : 40|2@1+ (1,0) [0|3] "" Vector__XXX
 SG_ VCRIGHT_rearCenterBuckleSwitch m0 : 44|2@1+ (1,0) [0|3] "" Vector__XXX
 SG_ VCRIGHT_rearRightBuckleSwitch m0 : 46|2@1+ (1,0) [0|3] "" Vector__XXX
 SG_ VCRIGHT_trunkExtReleasePressedPe m1 : 1|1@1+ (1,0) [0|1] "" Vector__XXX
 SG_ VCRIGHT_frontSeatTrackBack m1 : 2|2@1+ (1,0) [1|3] "" Vector__XXX
 SG_ VCRIGHT_frontSeatTrackForward m1 : 4|2@1+ (1,0) [1|3] "" Vector__XXX
 SG_ VCRIGHT_frontSeatTiltDown m1 : 6|2@1+ (1,0) [1|3] "" Vector__XXX
 SG_ VCRIGHT_frontSeatTiltUp m1 : 8|2@1+ (1,0) [1|3] "" Vector__XXX
 SG_ VCRIGHT_frontSeatLiftDown m1 : 10|2@1+ (1,0) [1|3] "" Vector__XXX
 SG_ VCRIGHT_frontSeatLiftUp m1 : 12|2@1+ (1,0) [1|3] "" Vector__XXX
 SG_ VCRIGHT_frontSeatBackrestBack m1 : 14|2@1+ (1,0) [1|3] "" Vector__XXX
 SG_ VCRIGHT_frontSeatBackrestForward m1 : 16|2@1+ (1,0) [1|3] "" Vector__XXX
 SG_ VCRIGHT_frontSeatLumbarDown m1 : 18|2@1+ (1,0) [1|3] "" Vector__XXX
 SG_ VCRIGHT_frontSeatLumbarUp m1 : 20|2@1+ (1,0) [1|3] "" Vector__XXX
 SG_ VCRIGHT_frontSeatLumbarIn m1 : 22|2@1+ (1,0) [1|3] "" Vector__XXX
 SG_ VCRIGHT_frontSeatLumbarOut m1 : 24|2@1+ (1,0) [1|3] "" Vector__XXX
 SG_ VCRIGHT_2RowSeatReclineSwitch m1 : 26|1@1+ (1,0) [0|1] "" Vector__XXX
 SG_ VCRIGHT_2RowSeatBackrestFoldSwit m1 : 27|1@1+ (1,0) [0|1] "" Vector__XXX
 SG_ VCRIGHT_frontSeatThighSupportExt m1 : 30|2@1+ (1,0) [1|3] "" Vector__XXX
 SG_ VCRIGHT_frontHandlePWM m1 : 32|7@1+ (1,0) [0|100] "%" Vector__XXX
 SG_ VCRIGHT_hvacHeatingAllowedLeft m1 : 39|1@1+ (1,0) [0|1] "" Vector__XXX
 SG_ VCRIGHT_rearHandlePWM m1 : 40|7@1+ (1,0) [0|100] "%" Vector__XXX
 SG_ VCRIGHT_gloveboxLightCurrent m1 : 47|5@1+ (2,0) [0|62] "mA" Vector__XXX
 SG_ VCRIGHT_frontSeatALR m1 : 52|2@1+ (1,0) [1|3] "" Vector__XXX
 SG_ VCRIGHT_frontSeatResistiveOccupa m1 : 54|2@1+ (1,0) [1|3] "" Vector__XXX
 SG_ VCRIGHT_2RowSeatReclineSwitchpac m1 : 56|3@1+ (1,0) [0|7] "" Vector__XXX
 SG_ VCRIGHT_hvacHeatingAllowedRight m1 : 59|1@1+ (1,0) [0|1] "" Vector__XXX
 SG_ VCRIGHT_frontSeatThighSupportRet m1 : 60|2@1+ (1,0) [1|3] "" Vector__XXX

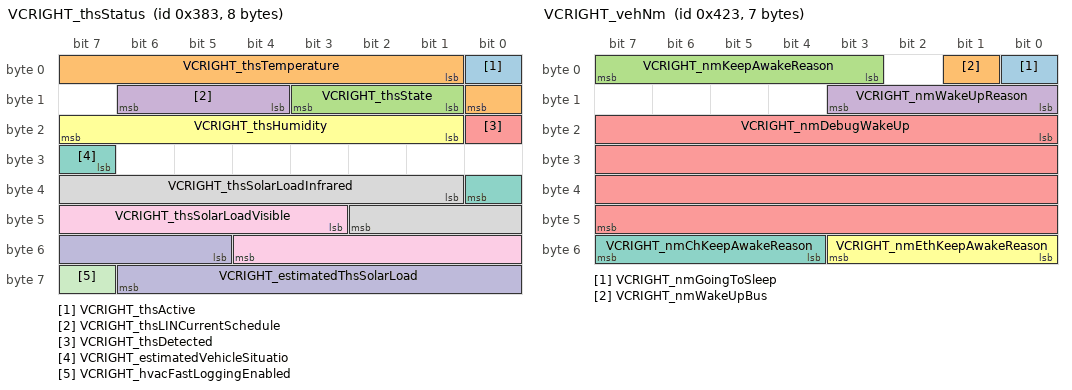
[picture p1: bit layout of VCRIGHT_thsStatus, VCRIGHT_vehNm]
BO_ 899 VCRIGHT_thsStatus: 8 VCRIGHT
 SG_ VCRIGHT_thsActive : 0|1@1+ (1,0) [0|1] "" Vector__XXX
 SG_ VCRIGHT_thsTemperature : 1|8@1+ (1,-40) [-40|150] "degC" Vector__XXX
 SG_ VCRIGHT_thsState : 9|3@1+ (1,0) [0|7] "" Vector__XXX
 SG_ VCRIGHT_thsLINCurrentSchedule : 12|3@1+ (1,0) [0|7] "" Vector__XXX
 SG_ VCRIGHT_thsDetected : 16|1@1+ (1,0) [0|1] "" Vector__XXX
 SG_ VCRIGHT_thsHumidity : 17|7@1+ (1,0) [0|100] "%" Vector__XXX
 SG_ VCRIGHT_estimatedVehicleSituatio : 31|2@1+ (1,0) [0|3] "" Vector__XXX
 SG_ VCRIGHT_thsSolarLoadInfrared : 33|10@1+ (2,0) [0|2044] "W/m2" Vector__XXX
 SG_ VCRIGHT_thsSolarLoadVisible : 43|10@1+ (2,0) [0|2044] "W/m2" Vector__XXX
 SG_ VCRIGHT_estimatedThsSolarLoad : 53|10@1+ (1,0) [0|1022] "W/m2" Vector__XXX
 SG_ VCRIGHT_hvacFastLoggingEnabled : 63|1@1+ (1,0) [0|1] "" Vector__XXX

BO_ 1545 VCRIGHT_udsResponse: 8 VCRIGHT
 SG_ VCRIGHT_udsResponseData_H : 7|32@0+ (1,0) [0|4294967295] "" Vector__XXX
 SG_ VCRIGHT_udsResponseData_L : 39|32@0+ (1,0) [0|4294967295] "" Vector__XXX

BO_ 1059 VCRIGHT_vehNm: 7 VCRIGHT
 SG_ VCRIGHT_nmGoingToSleep : 0|1@1+ (1,0) [0|1] "" Vector__XXX
 SG_ VCRIGHT_nmWakeUpBus : 1|1@1+ (1,0) [0|1] "" Vector__XXX
 SG_ VCRIGHT_nmKeepAwakeReason : 3|5@1+ (1,0) [1|31] "" Vector__XXX
 SG_ VCRIGHT_nmWakeUpReason : 8|4@1+ (1,0) [0|15] "" Vector__XXX
 SG_ VCRIGHT_nmDebugWakeUp : 16|32@1+ (1,0) [0|4294967295] "" Vector__XXX
 SG_ VCRIGHT_nmEthKeepAwakeReason : 48|4@1+ (1,0) [1|15] "" Vector__XXX
 SG_ VCRIGHT_nmChKeepAwakeReason : 52|4@1+ (1,0) [1|15] "" Vector__XXX

BO_ 707 VCRIGHT_windowStatus: 8 VCRIGHT
 SG_ VCRIGHT_windowStatusIndex M : 0|1@1+ (1,0) [0|1] "" Vector__XXX
 SG_ VCRIGHT_windowStateRF m0 : 1|4@1+ (1,0) [0|15] "" Vector__XXX
 SG_ VCRIGHT_windowTrimClearMoveReque m0 : 5|2@1+ (1,0) [0|3] "" Vector__XXX
 SG_ VCRIGHT_windowDutyRF m0 : 8|6@1- (5,0) [-100|100] "%" Vector__XXX
 SG_ VCRIGHT_windowTrimClearActiveReq m0 : 14|2@1+ (1,0) [1|3] "" Vector__XXX
 SG_ VCRIGHT_windowCurrentRF m0 : 16|6@1- (0.5,0) [-15|15] "A" Vector__XXX
 SG_ VCRIGHT_windowPositionRF m0 : 22|9@1- (1.25,265) [-50|580] "mm" Vector__XXX
 SG_ VCRIGHT_windowCalibratedRF m0 : 32|1@1+ (1,0) [0|1] "" Vector__XXX
 SG_ VCRIGHT_windowStateRR m0 : 33|4@1+ (1,0) [0|15] "" Vector__XXX
 SG_ VCRIGHT_windowDutyRR m0 : 40|6@1- (5,0) [-100|100] "%" Vector__XXX
 SG_ VCRIGHT_windowCurrentRR m0 : 48|6@1- (0.5,0) [-15|15] "A" Vector__XXX
 SG_ VCRIGHT_windowPositionRR m0 : 54|9@1- (1.25,265) [-50|580] "mm" Vector__XXX
 SG_ VCRIGHT_windowCalibratedRR m0 : 63|1@1+ (1,0) [0|1] "" Vector__XXX
 SG_ VCRIGHT_windowThermalTCRF m1 : 1|8@1+ (1,0) [0|255] "s" Vector__XXX
 SG_ VCRIGHT_windowThermalModeRF m1 : 9|2@1+ (1,0) [1|3] "" Vector__XXX
 SG_ VCRIGHT_windowStopReasonRF m1 : 11|3@1+ (1,0) [0|7] "" Vector__XXX
 SG_ VCRIGHT_windowStopReqReasonRF m1 : 14|4@1+ (1,0) [0|15] "" Vector__XXX
 SG_ VCRIGHT_windowThermalTCRR m1 : 18|8@1+ (1,0) [0|255] "s" Vector__XXX
 SG_ VCRIGHT_windowThermalModeRR m1 : 26|2@1+ (1,0) [1|3] "" Vector__XXX
 SG_ VCRIGHT_windowStopReasonRR m1 : 28|3@1+ (1,0) [0|7] "" Vector__XXX
 SG_ VCRIGHT_windowStopReqReasonRR m1 : 31|4@1+ (1,0) [0|15] "" Vector__XXX
 SG_ VCRIGHT_windowControlStateRF m1 : 35|2@1+ (1,0) [0|3] "" Vector__XXX
 SG_ VCRIGHT_windowCtrlUnavailableRF m1 : 38|3@1+ (1,0) [0|7] "" Vector__XXX
 SG_ VCRIGHT_windowControlStateRR m1 : 42|2@1+ (1,0) [0|3] "" Vector__XXX
 SG_ VCRIGHT_windowCtrlUnavailableRR m1 : 45|3@1+ (1,0) [0|7] "" Vector__XXX
 SG_ VCRIGHT_windowPositionStateRF m1 : 49|3@1+ (1,0) [0|7] "" Vector__XXX
 SG_ VCRIGHT_windowPositionStateRR m1 : 52|3@1+ (1,0) [0|7] "" Vector__XXX
 SG_ VCRIGHT_windowVehGearStateRF m1 : 56|2@1+ (1,0) [1|3] "" Vector__XXX
 SG_ VCRIGHT_windowVehGearStateRR m1 : 58|2@1+ (1,0) [1|3] "" Vector__XXX
 SG_ VCRIGHT_windowSpeedTableStatusRF m1 : 60|2@1+ (1,0) [1|3] "" Vector__XXX
 SG_ VCRIGHT_windowSpeedTableStatusRR m1 : 62|2@1+ (1,0) [1|3] "" Vector__XXX

BO_ 969 VCSEC_BLEEndpointInfo: 8 VCSEC
 SG_ VCSEC_BLEEndpointInfoIndex M : 0|8@1+ (1,0) [0|255] "" Vector__XXX
 SG_ VCSEC_BLECENTERComponentID m1 : 8|16@1+ (1,0) [0|65535] "" Vector__XXX
 SG_ VCSEC_BLECENTERPcbaID m1 : 24|8@1+ (1,0) [0|255] "" Vector__XXX
 SG_ VCSEC_BLECENTERAssemblyID m1 : 32|8@1+ (1,0) [0|255] "" Vector__XXX
 SG_ VCSEC_BLECENTERUsageID m1 : 40|16@1+ (1,0) [0|65535] "" Vector__XXX
 SG_ VCSEC_BLECENTERCrc m2 : 8|32@1+ (1,0) [0|4294967295] "" Vector__XXX
 SG_ VCSEC_BLELEFTAppGitHashByte m3 : 8|56@1+ (1,0) [0|7.20575940379e+16] "" Vector__XXX
 SG_ VCSEC_BLELEFTComponentID m4 : 8|16@1+ (1,0) [0|65535] "" Vector__XXX
 SG_ VCSEC_BLELEFTPcbaID m4 : 24|8@1+ (1,0) [0|255] "" Vector__XXX
 SG_ VCSEC_BLELEFTAssemblyID m4 : 32|8@1+ (1,0) [0|255] "" Vector__XXX
 SG_ VCSEC_BLELEFTUsageID m4 : 40|16@1+ (1,0) [0|65535] "" Vector__XXX
 SG_ VCSEC_BLELEFTCrc m5 : 8|32@1+ (1,0) [0|4294967295] "" Vector__XXX
 SG_ VCSEC_BLERIGHTAppGitHashByte m6 : 8|56@1+ (1,0) [0|7.20575940379e+16] "" Vector__XXX
 SG_ VCSEC_BLERIGHTComponentID m7 : 8|16@1+ (1,0) [0|65535] "" Vector__XXX
 SG_ VCSEC_BLERIGHTPcbaID m7 : 24|8@1+ (1,0) [0|255] "" Vector__XXX
 SG_ VCSEC_BLERIGHTAssemblyID m7 : 32|8@1+ (1,0) [0|255] "" Vector__XXX
 SG_ VCSEC_BLERIGHTUsageID m7 : 40|16@1+ (1,0) [0|65535] "" Vector__XXX
 SG_ VCSEC_BLERIGHTCrc m8 : 8|32@1+ (1,0) [0|4294967295] "" Vector__XXX
 SG_ VCSEC_BLEREARAppGitHashByte m9 : 8|56@1+ (1,0) [0|7.20575940379e+16] "" Vector__XXX
 SG_ VCSEC_BLEREARComponentID m10 : 8|16@1+ (1,0) [0|65535] "" Vector__XXX
 SG_ VCSEC_BLEREARPcbaID m10 : 24|8@1+ (1,0) [0|255] "" Vector__XXX
 SG_ VCSEC_BLEREARAssemblyID m10 : 32|8@1+ (1,0) [0|255] "" Vector__XXX
 SG_ VCSEC_BLEREARUsageID m10 : 40|16@1+ (1,0) [0|65535] "" Vector__XXX
 SG_ VCSEC_BLEREARCrc m11 : 8|32@1+ (1,0) [0|4294967295] "" Vector__XXX
 SG_ VCSEC_UWBRightCrc m12 : 8|32@1+ (1,0) [0|4294967295] "" Vector__XXX
 SG_ VCSEC_UWBRightRadioConfigState m12 : 40|4@1+ (1,0) [0|15] "" Vector__XXX
 SG_ VCSEC_UWBRightUpdateStatus m12 : 44|3@1+ (1,0) [0|6] "" Vector__XXX
 SG_ VCSEC_UWBRightRetryLimitReached m12 : 47|1@1+ (1,0) [0|1] "" Vector__XXX
 SG_ VCSEC_UWBRightDspVersion m12 : 48|16@1+ (1,0) [0|65535] "" Vector__XXX
 SG_ VCSEC_UWBRightComponentID m13 : 8|8@1+ (1,0) [0|255] "" Vector__XXX
 SG_ VCSEC_UWBRightPcbaID m13 : 16|8@1+ (1,0) [0|255] "" Vector__XXX
 SG_ VCSEC_UWBRightAssemblyID m13 : 24|8@1+ (1,0) [0|255] "" Vector__XXX
 SG_ VCSEC_UWBRightUsageID m13 : 32|16@1+ (1,0) [0|65535] "" Vector__XXX
 SG_ VCSEC_UWBRearRightCrc m15 : 8|32@1+ (1,0) [0|4294967295] "" Vector__XXX
 SG_ VCSEC_UWBRearRightRadioConfigSta m15 : 40|4@1+ (1,0) [0|15] "" Vector__XXX
 SG_ VCSEC_UWBRearRightUpdateStatus m15 : 44|3@1+ (1,0) [0|6] "" Vector__XXX
 SG_ VCSEC_UWBRearRightRetryLimitReac m15 : 47|1@1+ (1,0) [0|1] "" Vector__XXX
 SG_ VCSEC_UWBRearRightDspVersion m15 : 48|16@1+ (1,0) [0|65535] "" Vector__XXX
 SG_ VCSEC_UWBRearRightComponentID m16 : 8|8@1+ (1,0) [0|255] "" Vector__XXX
 SG_ VCSEC_UWBRearRightPcbaID m16 : 16|8@1+ (1,0) [0|255] "" Vector__XXX
 SG_ VCSEC_UWBRearRightAssemblyID m16 : 24|8@1+ (1,0) [0|255] "" Vector__XXX
 SG_ VCSEC_UWBRearRightUsageID m16 : 32|16@1+ (1,0) [0|65535] "" Vector__XXX
 SG_ VCSEC_UWBRearLeftCrc m18 : 8|32@1+ (1,0) [0|4294967295] "" Vector__XXX
 SG_ VCSEC_UWBRearLeftRadioConfigStat m18 : 40|4@1+ (1,0) [0|15] "" Vector__XXX
 SG_ VCSEC_UWBRearLeftUpdateStatus m18 : 44|3@1+ (1,0) [0|6] "" Vector__XXX
 SG_ VCSEC_UWBRearLeftRetryLimitReach m18 : 47|1@1+ (1,0) [0|1] "" Vector__XXX
 SG_ VCSEC_UWBRearLeftDspVersion m18 : 48|16@1+ (1,0) [0|65535] "" Vector__XXX
 SG_ VCSEC_UWBRearLeftComponentID m19 : 8|8@1+ (1,0) [0|255] "" Vector__XXX
 SG_ VCSEC_UWBRearLeftPcbaID m19 : 16|8@1+ (1,0) [0|255] "" Vector__XXX
 SG_ VCSEC_UWBRearLeftAssemblyID m19 : 24|8@1+ (1,0) [0|255] "" Vector__XXX
 SG_ VCSEC_UWBRearLeftUsageID m19 : 32|16@1+ (1,0) [0|65535] "" Vector__XXX
 SG_ VCSEC_UWBRearCrc m21 : 8|32@1+ (1,0) [0|4294967295] "" Vector__XXX
 SG_ VCSEC_UWBRearRadioConfigState m21 : 40|4@1+ (1,0) [0|15] "" Vector__XXX
 SG_ VCSEC_UWBRearUpdateStatus m21 : 44|3@1+ (1,0) [0|6] "" Vector__XXX
 SG_ VCSEC_UWBRearRetryLimitReached m21 : 47|1@1+ (1,0) [0|1] "" Vector__XXX
 SG_ VCSEC_UWBRearDspVersion m21 : 48|16@1+ (1,0) [0|65535] "" Vector__XXX
 SG_ VCSEC_UWBRearComponentID m22 : 8|8@1+ (1,0) [0|255] "" Vector__XXX
 SG_ VCSEC_UWBRearPcbaID m22 : 16|8@1+ (1,0) [0|255] "" Vector__XXX
 SG_ VCSEC_UWBRearAssemblyID m22 : 24|8@1+ (1,0) [0|255] "" Vector__XXX
 SG_ VCSEC_UWBRearUsageID m22 : 32|16@1+ (1,0) [0|65535] "" Vector__XXX
 SG_ VCSEC_UWBLeftCrc m24 : 8|32@1+ (1,0) [0|4294967295] "" Vector__XXX
 SG_ VCSEC_UWBLeftRadioConfigState m24 : 40|4@1+ (1,0) [0|15] "" Vector__XXX
 SG_ VCSEC_UWBLeftUpdateStatus m24 : 44|3@1+ (1,0) [0|6] "" Vector__XXX
 SG_ VCSEC_UWBLeftRetryLimitReached m24 : 47|1@1+ (1,0) [0|1] "" Vector__XXX
 SG_ VCSEC_UWBLeftDspVersion m24 : 48|16@1+ (1,0) [0|65535] "" Vector__XXX
 SG_ VCSEC_UWBLeftComponentID m25 : 8|8@1+ (1,0) [0|255] "" Vector__XXX
 SG_ VCSEC_UWBLeftPcbaID m25 : 16|8@1+ (1,0) [0|255] "" Vector__XXX
 SG_ VCSEC_UWBLeftAssemblyID m25 : 24|8@1+ (1,0) [0|255] "" Vector__XXX
 SG_ VCSEC_UWBLeftUsageID m25 : 32|16@1+ (1,0) [0|65535] "" Vector__XXX
 SG_ VCSEC_UWBCenterCrc m27 : 8|32@1+ (1,0) [0|4294967295] "" Vector__XXX
 SG_ VCSEC_UWBCenterRadioConfigState m27 : 40|4@1+ (1,0) [0|15] "" Vector__XXX
 SG_ VCSEC_UWBCenterUpdateStatus m27 : 44|3@1+ (1,0) [0|6] "" Vector__XXX
 SG_ VCSEC_UWBCenterRetryLimitReached m27 : 47|1@1+ (1,0) [0|1] "" Vector__XXX
 SG_ VCSEC_UWBCenterDspVersion m27 : 48|16@1+ (1,0) [0|65535] "" Vector__XXX
 SG_ VCSEC_UWBCenterComponentID m28 : 8|8@1+ (1,0) [0|255] "" Vector__XXX
 SG_ VCSEC_UWBCenterPcbaID m28 : 16|8@1+ (1,0) [0|255] "" Vector__XXX
 SG_ VCSEC_UWBCenterAssemblyID m28 : 24|8@1+ (1,0) [0|255] "" Vector__XXX
 SG_ VCSEC_UWBCenterUsageID m28 : 32|16@1+ (1,0) [0|65535] "" Vector__XXX
 SG_ VCSEC_BLERIGHTREARCrc m30 : 8|32@1+ (1,0) [0|4294967295] "" Vector__XXX
 SG_ VCSEC_BLERIGHTREARComponentID m31 : 8|16@1+ (1,0) [0|65535] "" Vector__XXX
 SG_ VCSEC_BLERIGHTREARPcbaID m31 : 24|8@1+ (1,0) [0|255] "" Vector__XXX
 SG_ VCSEC_BLERIGHTREARAssemblyID m31 : 32|8@1+ (1,0) [0|255] "" Vector__XXX
 SG_ VCSEC_BLERIGHTREARUsageID m31 : 40|16@1+ (1,0) [0|65535] "" Vector__XXX
 SG_ VCSEC_BLENFCCRADLECrc m33 : 8|32@1+ (1,0) [0|4294967295] "" Vector__XXX
 SG_ VCSEC_BLENFCCRADLEComponentID m34 : 8|16@1+ (1,0) [0|65535] "" Vector__XXX
 SG_ VCSEC_BLENFCCRADLEPcbaID m34 : 24|8@1+ (1,0) [0|255] "" Vector__XXX
 SG_ VCSEC_BLENFCCRADLEAssemblyID m34 : 32|8@1+ (1,0) [0|255] "" Vector__XXX
 SG_ VCSEC_BLENFCCRADLEUsageID m34 : 40|16@1+ (1,0) [0|65535] "" Vector__XXX
 SG_ VCSEC_BLELEFTREARCrc m36 : 8|32@1+ (1,0) [0|4294967295] "" Vector__XXX
 SG_ VCSEC_BLELEFTREARComponentID m37 : 8|16@1+ (1,0) [0|65535] "" Vector__XXX
 SG_ VCSEC_BLELEFTREARPcbaID m37 : 24|8@1+ (1,0) [0|255] "" Vector__XXX
 SG_ VCSEC_BLELEFTREARAssemblyID m37 : 32|8@1+ (1,0) [0|255] "" Vector__XXX
 SG_ VCSEC_BLELEFTREARUsageID m37 : 40|16@1+ (1,0) [0|65535] "" Vector__XXX

BO_ 607 VCSEC_ChildSeatStatus: 8 VCSEC
 SG_ VCSEC_childSeat0_connectionState : 0|3@1+ (1,0) [0|7] "" Vector__XXX
 SG_ VCSEC_childSeat0_taskDisconnecti : 3|2@1+ (1,0) [0|3] "" Vector__XXX
 SG_ VCSEC_childSeat0_state : 5|4@1+ (1,0) [0|15] "" Vector__XXX
 SG_ VCSEC_childSeat0_taskErrorCode : 9|3@1+ (1,0) [0|7] "" Vector__XXX
 SG_ VCSEC_childSeat0_RSSI : 12|8@1- (1,0) [-128|126] "" Vector__XXX
 SG_ VCSEC_childSeat0_ISOFixStatus : 20|2@1+ (1,0) [0|3] "" Vector__XXX
 SG_ VCSEC_childSeat0_buckleStatus : 22|2@1+ (1,0) [0|3] "" Vector__XXX
 SG_ VCSEC_childSeat0_occupancyStatus : 24|2@1+ (1,0) [0|3] "" Vector__XXX
 SG_ VCSEC_childSeat1_connectionState : 26|3@1+ (1,0) [0|7] "" Vector__XXX
 SG_ VCSEC_childSeat1_taskDisconnecti : 29|2@1+ (1,0) [0|3] "" Vector__XXX
 SG_ VCSEC_childSeat1_state : 31|4@1+ (1,0) [0|15] "" Vector__XXX
 SG_ VCSEC_childSeat1_taskErrorCode : 35|3@1+ (1,0) [0|7] "" Vector__XXX
 SG_ VCSEC_childSeat1_RSSI : 38|8@1- (1,0) [-128|126] "" Vector__XXX
 SG_ VCSEC_childSeat1_ISOFixStatus : 46|2@1+ (1,0) [0|3] "" Vector__XXX
 SG_ VCSEC_childSeat1_buckleStatus : 48|2@1+ (1,0) [0|3] "" Vector__XXX
 SG_ VCSEC_childSeat1_occupancyStatus : 50|2@1+ (1,0) [0|3] "" Vector__XXX
 SG_ VCSEC_childPresenceDetectionWarn : 52|1@1+ (1,0) [0|1] "" Vector__XXX
 SG_ VCSEC_childSeatScanStatus : 53|2@1+ (1,0) [0|3] "" Vector__XXX
 SG_ VCSEC_childPresenceDetectionStat : 55|4@1+ (1,0) [0|15] "" Vector__XXX
 SG_ VCSEC_childPresenceDetectionSupp : 59|2@1+ (1,0) [0|3] "" Vector__XXX
 SG_ VCSEC_childPresenceDetectionNoti : 61|1@1+ (1,0) [0|1] "" Vector__XXX

BO_TX_BU_ 611 : VCRIGHT;
BO_TX_BU_ 691 : VCRIGHT;
BO_TX_BU_ 1859 : VCRIGHT;
BO_TX_BU_ 1251 : VCRIGHT;
BO_TX_BU_ 739 : VCRIGHT;
BO_TX_BU_ 835 : VCRIGHT;
BO_TX_BU_ 963 : VCRIGHT;
BO_TX_BU_ 899 : VCRIGHT;
BO_TX_BU_ 1545 : VCRIGHT;
BO_TX_BU_ 1059 : VCRIGHT;
BO_TX_BU_ 707 : VCRIGHT;
BO_TX_BU_ 969 : VCSEC;
BO_TX_BU_ 607 : VCSEC;
CM_ BO_ 611 "Right body controller message: logging10 hz; frame length observed on a vehicle bus";
CM_ SG_ 611 VCRIGHT_logging10HzIndex "Right body controller: logging10 hz index";
CM_ SG_ 611 VCRIGHT_hvacLHBleedTarget "Right body controller: hvac LH bleed target";
CM_ SG_ 611 VCRIGHT_hvacRHBleedTarget "Right body controller: hvac RH bleed target";
CM_ SG_ 611 VCRIGHT_hvacLHVaneTarget "Right body controller: hvac LH vane target";
CM_ SG_ 611 VCRIGHT_hvacRHVaneTarget "Right body controller: hvac RH vane target";
CM_ SG_ 611 VCRIGHT_hvacUpperModeTarget "Right body controller: hvac upper mode target";
CM_ SG_ 611 VCRIGHT_hvacLowerModeTarget "Right body controller: hvac lower mode target";
CM_ SG_ 611 VCRIGHT_hvacIntakeTarget "Right body controller: hvac intake target";
CM_ SG_ 611 VCRIGHT_hvacLHBleedPosition "Right body controller: hvac LH bleed position";
CM_ SG_ 611 VCRIGHT_hvacRHBleedPosition "Right body controller: hvac RH bleed position";
CM_ SG_ 611 VCRIGHT_hvacLHVanePosition "Right body controller: hvac LH vane position";
CM_ SG_ 611 VCRIGHT_hvacRHVanePosition "Right body controller: hvac RH vane position";
CM_ SG_ 611 VCRIGHT_hvacUpperModePosition "Right body controller: hvac upper mode position";
CM_ SG_ 611 VCRIGHT_hvacLowerModePosition "Right body controller: hvac lower mode position";
CM_ SG_ 611 VCRIGHT_hvacIntakePosition "Right body controller: hvac intake position";
CM_ SG_ 611 VCRIGHT_hvacLHBleedActuatorState "Right body controller: hvac LH bleed actuator state";
CM_ SG_ 611 VCRIGHT_hvacRHBleedActuatorState "Right body controller: hvac RH bleed actuator state";
CM_ SG_ 611 VCRIGHT_hvacLHVaneActuatorState "Right body controller: hvac LH vane actuator state";
CM_ SG_ 611 VCRIGHT_hvacRHVaneActuatorState "Right body controller: hvac RH vane actuator state";
CM_ SG_ 611 VCRIGHT_hvacUpperModeActState "Right body controller: hvac upper mode act state";
CM_ SG_ 611 VCRIGHT_hvacLowerModeActState "Right body controller: hvac lower mode act state";
CM_ SG_ 611 VCRIGHT_hvacIntakeActuatorState "Right body controller: hvac intake actuator state";
CM_ SG_ 611 VCRIGHT_hvacRearActuatorState "Right body controller: hvac rear actuator state";
CM_ SG_ 611 VCRIGHT_EvapPulldownBiasActive "Indicates if an evap pulldown smell mitigation is active";
CM_ SG_ 611 VCRIGHT_tempDatLeftEst "Right body controller: temp dat left est; raw 255 = signal not available (SNA)";
CM_ SG_ 611 VCRIGHT_tempDatRightEst "Right body controller: temp dat right est; raw 255 = signal not available (SNA)";
CM_ SG_ 611 VCRIGHT_tempDuctLeftEst "Right body controller: temp duct left est; raw 255 = signal not available (SNA)";
CM_ SG_ 611 VCRIGHT_tempDuctRightEst "Right body controller: temp duct right est; raw 255 = signal not available (SNA)";
CM_ SG_ 611 VCRIGHT_ptcHeaterBadRodDetection "Right body controller: ptc heater bad rod detection state";
CM_ SG_ 611 VCRIGHT_upperModeDrvActuatorStat "Reports the HVAC actuator state";
CM_ SG_ 611 VCRIGHT_leftVerticalActuato_0001 "Right body controller: left vertical actuator status";
CM_ SG_ 611 VCRIGHT_leftLateralActuatorStatu "Right body controller: left lateral actuator status";
CM_ SG_ 611 VCRIGHT_rightVerticalActuat_0001 "Right body controller: right vertical actuator status";
CM_ SG_ 611 VCRIGHT_rightLateralActuato_0001 "Right body controller: right lateral actuator status";
CM_ SG_ 611 VCRIGHT_leftVerticalActuatorStat "Reports the HVAC actuator state";
CM_ SG_ 611 VCRIGHT_leftLateralActuatorState "Reports the HVAC actuator state";
CM_ SG_ 611 VCRIGHT_rightVerticalActuatorSta "Reports the HVAC actuator state";
CM_ SG_ 611 VCRIGHT_rightLateralActuatorStat "Reports the HVAC actuator state";
CM_ SG_ 611 VCRIGHT_windshieldRHExteriorSurf "Right body controller: windshield RH exterior surface; raw 255 = signal not available (SNA)";
CM_ SG_ 611 VCRIGHT_leftVerticalActuatorDuty "Reports the HVAC motor duty cycle";
CM_ SG_ 611 VCRIGHT_leftLateralActuatorDuty "Reports the HVAC motor duty cycle";
CM_ SG_ 611 VCRIGHT_rightVerticalActuatorDut "Reports the HVAC motor duty cycle";
CM_ SG_ 611 VCRIGHT_rightLateralActuatorDuty "Reports the HVAC motor duty cycle";
CM_ SG_ 611 VCRIGHT_frontLeftSeatTempTargetQ "Reports the front left seat heating target temperature.";
CM_ SG_ 611 VCRIGHT_frontRightSeatTempTarget "Reports the front right seat heating target temperature.";
CM_ SG_ 611 VCRIGHT_hvacRearPosition "Right body controller: hvac rear position";
CM_ SG_ 611 VCRIGHT_hvacRearTarget "Right body controller: hvac rear target";
CM_ BO_ 691 "Right body controller message: logging1 hz; frame length observed on a vehicle bus";
CM_ SG_ 691 VCRIGHT_logging1HzIndex "Right body controller: logging1 hz index";
CM_ SG_ 691 VCRIGHT_glareShieldHeaterState "State of the glare shield heater";
CM_ SG_ 691 VCRIGHT_tempIncarCabinProbe "Right body controller: temp incar cabin probe; raw 255 = signal not available (SNA)";
CM_ SG_ 691 VCRIGHT_cabinTempInteriorL2 "Right body controller: cabin temp interior L2; raw 255 = signal not available (SNA)";
CM_ SG_ 691 VCRIGHT_cabinTempInteriorSunnyL2 "Right body controller: cabin temp interior sunny L2; raw 255 = signal not available (SNA)";
CM_ SG_ 691 VCRIGHT_tempIncarCabinMid "Right body controller: temp incar cabin mid; raw 250 = signal not available (SNA)";
CM_ SG_ 691 VCRIGHT_cabinTempInteriorL3 "Right body controller: cabin temp interior L3; raw 255 = signal not available (SNA)";
CM_ SG_ 691 VCRIGHT_cabinTempInteriorSunnyL3 "Right body controller: cabin temp interior sunny L3; raw 255 = signal not available (SNA)";
CM_ SG_ 691 VCRIGHT_tempWetBulb "Estimate the rain temp; raw 255 = signal not available (SNA)";
CM_ SG_ 691 VCRIGHT_isRainingOrSnowing "Right body controller: is raining or snowing";
CM_ SG_ 691 VCRIGHT_cabinTempGlassRoof "Modeled cabin temperature near the glass roof; raw 255 = signal not available (SNA)";
CM_ SG_ 691 VCRIGHT_cabinTempWindshield "Windshield temperature estimate; raw 255 = signal not available (SNA)";
CM_ SG_ 691 VCRIGHT_cabinTempInterior "Modeled interior cabin temperature; raw 255 = signal not available (SNA)";
CM_ SG_ 691 VCRIGHT_cabinTempInteriorSunny "Modeled interior surface temperature exposed to direct sunlight; raw 255 = signal not available (SNA)";
CM_ SG_ 691 VCRIGHT_cabinTempSideGlassLeft "Modeled glass temperature left; raw 255 = signal not available (SNA)";
CM_ SG_ 691 VCRIGHT_cabinTempSideGlassRight "Modeled glass temperature right; raw 255 = signal not available (SNA)";
CM_ SG_ 691 VCRIGHT_cabinTempBreathLevel "Modeled cabin temperature near occupant breathing level; raw 255 = signal not available (SNA)";
CM_ SG_ 691 VCRIGHT_pcbaTemperature "Right body controller: pcba temperature";
CM_ SG_ 691 VCRIGHT_wattsHeaterLeftTotal "Right body controller: watts heater left total";
CM_ SG_ 691 VCRIGHT_wattsHeaterRightTotal "Right body controller: watts heater right total";
CM_ SG_ 691 VCRIGHT_qdotLeftFFUnsat "Right body controller: qdot left FF unsat";
CM_ SG_ 691 VCRIGHT_qdotRightFFUnsat "Right body controller: qdot right FF unsat";
CM_ SG_ 691 VCRIGHT_nvhLevelDb "Right body controller: nvh level db";
CM_ SG_ 691 VCRIGHT_hvacSetTempActualLeft "HVAC internal left temperature set point";
CM_ SG_ 691 VCRIGHT_hvacSetTempActualRight "HVAC internal right temperature set point";
CM_ SG_ 691 VCRIGHT_hvacAutoTransitionReason "Reason for airflow mode change when system is operating in auto";
CM_ SG_ 691 VCRIGHT_hvacMassflowTarget "Right body controller: hvac massflow target";
CM_ SG_ 691 VCRIGHT_hvacQdotLimitedLeft "Right body controller: hvac qdot limited left";
CM_ SG_ 691 VCRIGHT_hvacQdotLimitedRight "Right body controller: hvac qdot limited right";
CM_ SG_ 691 VCRIGHT_LHPanelAirflowBlocked "Right body controller: LH panel airflow blocked";
CM_ SG_ 691 VCRIGHT_RHPanelAirflowBlocked "Right body controller: RH panel airflow blocked";
CM_ SG_ 691 VCRIGHT_floorAirflowBlocked "Right body controller: floor airflow blocked";
CM_ SG_ 691 VCRIGHT_defrostAirflowBlocked "Right body controller: defrost airflow blocked";
CM_ SG_ 691 VCRIGHT_hvacFilterLifeDetectActi "Indicates when filter life detection is active";
CM_ SG_ 691 VCRIGHT_hvacLHBleedOperationMode "Right body controller: hvac LH bleed operation mode";
CM_ SG_ 691 VCRIGHT_hvacRHBleedOperationMode "Right body controller: hvac RH bleed operation mode";
CM_ SG_ 691 VCRIGHT_hvacLHVaneOperationMode "Right body controller: hvac LH vane operation mode";
CM_ SG_ 691 VCRIGHT_hvacRHVaneOperationMode "Right body controller: hvac RH vane operation mode";
CM_ SG_ 691 VCRIGHT_hvacUpperModeOpMode "Right body controller: hvac upper mode op mode";
CM_ SG_ 691 VCRIGHT_hvacLowerModeOpMode "Right body controller: hvac lower mode op mode";
CM_ SG_ 691 VCRIGHT_hvacIntakeOperationMode "Right body controller: hvac intake operation mode";
CM_ SG_ 691 VCRIGHT_hvacRearOperationMode "Right body controller: hvac rear operation mode";
CM_ SG_ 691 VCRIGHT_isProbeFeedbackApplied "Right body controller: is probe feedback applied";
CM_ SG_ 691 VCRIGHT_feedbackPullDownScalar "Right body controller: feedback pull down scalar";
CM_ SG_ 691 VCRIGHT_feedForwardPullDownScala "Right body controller: feed forward pull down scalar";
CM_ SG_ 691 VCRIGHT_convectionTargetLeft "Right body controller: convection target left; raw 511 = signal not available (SNA)";
CM_ SG_ 691 VCRIGHT_convectionTargetRight "Right body controller: convection target right; raw 511 = signal not available (SNA)";
CM_ SG_ 691 VCRIGHT_convectionDeliveredLeft "Right body controller: convection delivered left; raw 511 = signal not available (SNA)";
CM_ SG_ 691 VCRIGHT_convectionDeliveredRight "Right body controller: convection delivered right; raw 511 = signal not available (SNA)";
CM_ SG_ 691 VCRIGHT_solarLoadRightOccupant "Right body controller: solar load right occupant; raw 127 = signal not available (SNA)";
CM_ SG_ 691 VCRIGHT_solarLoadLeftOccupant "Right body controller: solar load left occupant; raw 127 = signal not available (SNA)";
CM_ SG_ 691 VCRIGHT_ptcShutOutletMitigationA "Right body controller: ptc shut outlet mitigation active";
CM_ SG_ 691 VCRIGHT_solarLoadFromThsTemp "Right body controller: solar load from ths temp; raw 255 = signal not available (SNA)";
CM_ SG_ 691 VCRIGHT_hvacFoggingRiskLeve_0003 "Fogging risk feedforward with conservative estimate";
CM_ SG_ 691 VCRIGHT_hvacFoggingRiskLeve_0004 "Fogging risk feedforward with conservative target";
CM_ SG_ 691 VCRIGHT_hvacFoggingRiskLeve_0001 "Fogging risk with conservative target";
CM_ SG_ 691 VCRIGHT_ptcHeaterTempDuctHigh "Right body controller: ptc heater temp duct high";
CM_ SG_ 691 VCRIGHT_ptcHeaterTempDuctFault "Right body controller: ptc heater temp duct fault";
CM_ SG_ 691 VCRIGHT_ptcHeaterNoAirflow "Right body controller: ptc heater no airflow";
CM_ SG_ 691 VCRIGHT_ptcHeaterHvacActNotReady "Right body controller: ptc heater hvac act not ready";
CM_ SG_ 691 VCRIGHT_ptcHeaterNoUiRequest "Right body controller: ptc heater no ui request";
CM_ SG_ 691 VCRIGHT_ptcHeaterNoHighVoltage "Right body controller: ptc heater no high voltage";
CM_ SG_ 691 VCRIGHT_ptcHeaterLAirPathBlocked "Right body controller: ptc heater l air path blocked";
CM_ SG_ 691 VCRIGHT_ptcHeaterRAirPathBlocked "Right body controller: ptc heater r air path blocked";
CM_ SG_ 691 VCRIGHT_ptcHeaterReqAirpathBlock "Right body controller: ptc heater req airpath blocked";
CM_ SG_ 691 VCRIGHT_hvacQdotFeedforward "Right body controller: hvac qdot feedforward";
CM_ SG_ 691 VCRIGHT_cabinTempWshldDefog "Windshield temperature estimate used for defogging; raw 255 = signal not available (SNA)";
CM_ SG_ 691 VCRIGHT_cabinTempWshldDefogTop "Right body controller: cabin temp wshld defog top; raw 255 = signal not available (SNA)";
CM_ SG_ 691 VCRIGHT_hvacLHBleedVoltage "Right body controller: hvac LH bleed voltage";
CM_ SG_ 691 VCRIGHT_hvacRHBleedVoltage "Right body controller: hvac RH bleed voltage";
CM_ SG_ 691 VCRIGHT_hvacLHVaneVoltage "Right body controller: hvac LH vane voltage";
CM_ SG_ 691 VCRIGHT_hvacRHVaneVoltage "Right body controller: hvac RH vane voltage";
CM_ SG_ 691 VCRIGHT_hvacUpperModeVoltage "Right body controller: hvac upper mode voltage";
CM_ SG_ 691 VCRIGHT_hvacLowerModeVoltage "Right body controller: hvac lower mode voltage";
CM_ SG_ 691 VCRIGHT_hvacIntakeVoltage "Right body controller: hvac intake voltage";
CM_ SG_ 691 VCRIGHT_cabinTempBreathLevelFHea "Right body controller: cabin temp breath level f heating; raw 255 = signal not available (SNA)";
CM_ SG_ 691 VCRIGHT_cabinTempBreathLevelFCoo "Right body controller: cabin temp breath level f cooling; raw 255 = signal not available (SNA)";
CM_ SG_ 691 VCRIGHT_hvacTorqueMassflowLinear "Right body controller: hvac torque massflow linear fit";
CM_ SG_ 691 VCRIGHT_hvacTorqueMassflowEstima "Right body controller: hvac torque massflow estimate status";
CM_ SG_ 691 VCRIGHT_hvacFoggingRiskLevelCons "Fogging risk with conservative estimate";
CM_ SG_ 691 VCRIGHT_hvacWindshieldRHConserva "Windshield RH conservative estimate";
CM_ SG_ 691 VCRIGHT_hvacFoggingRiskLevelFeed "Fogging risk feedback";
CM_ SG_ 691 VCRIGHT_hvacFoggingRiskLevelInte "Fogging risk feedback integral";
CM_ SG_ 691 VCRIGHT_hvacFoggingRiskLeve_0002 "Fogging risk feedforward";
CM_ SG_ 691 VCRIGHT_hvacCabOvrheatProtActive "Status of cabin overheat protection";
CM_ SG_ 691 VCRIGHT_hvacCabinPurgeAllowed "Right body controller: hvac cabin purge allowed";
CM_ SG_ 691 VCRIGHT_hvacCabOvrheatProtAllowe "Cabin overheat protection is allowed to run";
CM_ SG_ 691 VCRIGHT_AP_humidityModelBasedCab "Right body controller: AP humidity model based cabin water mass; raw 1023 = signal not available (SNA)";
CM_ SG_ 691 VCRIGHT_cabinTempFanCurrent "Right body controller: cabin temp fan current";
CM_ SG_ 691 VCRIGHT_cabinTempFanOutput "Right body controller: cabin temp fan output";
CM_ SG_ 691 VCRIGHT_cloudinessEstimatedPct "Right body controller: cloudiness estimated pct";
CM_ SG_ 691 VCRIGHT_solarLoadOnVehFiltered "Right body controller: solar load on veh filtered; raw 255 = signal not available (SNA)";
CM_ SG_ 691 VCRIGHT_cabinTempProbeEstimate "Right body controller: cabin temp probe estimate; raw 255 = signal not available (SNA)";
CM_ SG_ 691 VCRIGHT_cabinTempThs "Estimated temperature from Tesla HVAC Sensor; raw 255 = signal not available (SNA)";
CM_ SG_ 691 VCRIGHT_cabinTempThsBracket "Right body controller: cabin temp ths bracket; raw 255 = signal not available (SNA)";
CM_ SG_ 691 VCRIGHT_leftHeatOvertempProtect "Right body controller: left heat overtemp protect";
CM_ SG_ 691 VCRIGHT_rightHeatOvertempProtect "Right body controller: right heat overtemp protect";
CM_ SG_ 691 VCRIGHT_CO2ppm "Right body controller: co2ppm; raw 1023 = signal not available (SNA)";
CM_ SG_ 691 VCRIGHT_timeLeftToCabinModelInit "Right body controller: time left to cabin model init";
CM_ SG_ 691 VCRIGHT_hvacEstimateWindshieldRH "Estimated windshield relative humidity";
CM_ SG_ 691 VCRIGHT_hvacFoggingRiskLevel "Control signal of the windshield fogging risk controller";
CM_ SG_ 691 VCRIGHT_hvacCabinHumidityLevel "Control signal of the cabin humidity controller";
CM_ SG_ 691 VCRIGHT_hvacFlashFoggingDetected "Windshield flash fogging risk detected";
CM_ SG_ 691 VCRIGHT_solarSensitivityInfr "Right body controller: solar sensitivity infr";
CM_ SG_ 691 VCRIGHT_solarSensitivityInfrCorr "Right body controller: solar sensitivity infr corr";
CM_ SG_ 691 VCRIGHT_lumbarCurrent "Electrical current of the lumbar ECU";
CM_ SG_ 691 VCRIGHT_ocsCurrent "Electrical current of the OCS ECU";
CM_ SG_ 691 VCRIGHT_rcmCurrent "Electrical current of the RCM ECU";
CM_ SG_ 691 VCRIGHT_radioTunerCurrent "Electrical current of the Radio Tuner";
CM_ SG_ 691 VCRIGHT_rearOilPumpCurrent "Right body controller: rear oil pump current";
CM_ SG_ 691 VCRIGHT_rearDefrostCurrent "Right body controller: rear defrost current";
CM_ SG_ 691 VCRIGHT_tailLightCurrent "Electrical current of the tail and license plate lights";
CM_ SG_ 691 VCRIGHT_turnTailStopLightCurrent "Reports the electrical current of the right rear turn indicator, right rear tail light, or right rear brake light";
CM_ SG_ 691 VCRIGHT_reverseFogLightsCurrent "Electrical current of the trunk fog light; raw 15 = signal not available (SNA)";
CM_ SG_ 691 VCRIGHT_stopReverseTurnLightCurr "Reports the electrical current of the right rear brake light, right rear reverse light, or right rear turn indicator";
CM_ SG_ 691 VCRIGHT_sideMirrorCurrent "Electrical current of side mirror tilt and fold";
CM_ SG_ 691 VCRIGHT_sideMirrorHeaterCurrent "Electrical current of the mirror heater; raw 31 = signal not available (SNA)";
CM_ SG_ 691 VCRIGHT_frontSeatHeatCushionPwr "Right body controller: front seat heat cushion pwr";
CM_ SG_ 691 VCRIGHT_trunkInteriorLEDCurrent "Electrical current of the trunk interior light; raw 15 = signal not available (SNA)";
CM_ SG_ 691 VCRIGHT_mapPocketLEDsCurrent "Electrical current of the map pocket lights; raw 15 = signal not available (SNA)";
CM_ SG_ 691 VCRIGHT_miscEFuseCurrent "Right body controller: misc e fuse current; raw 31 = signal not available (SNA)";
CM_ SG_ 691 VCRIGHT_interiorHandleLEDCurrent "Electrical current of the interior handle LED";
CM_ SG_ 691 VCRIGHT_miscInteriorLightsCurren "Electrical current of the misc interior lights; raw 7 = signal not available (SNA)";
CM_ SG_ 691 VCRIGHT_frontPuddleLEDCurrent "Electrical current of the front puddle LED; raw 7 = signal not available (SNA)";
CM_ SG_ 691 VCRIGHT_rearPuddleLEDCurrent "Electrical current of the rear puddle LED; raw 7 = signal not available (SNA)";
CM_ SG_ 691 VCRIGHT_liftgateShutfaceLEDCurre "Electrical current of the liftgate shutface LED; raw 7 = signal not available (SNA)";
CM_ SG_ 691 VCRIGHT_3rSeatTOSCurrent "Electrical current of the 3R TOS; raw 15 = signal not available (SNA)";
CM_ SG_ 691 VCRIGHT_vbatFusedCurrent "Right body controller: vbat fused current; raw 15 = signal not available (SNA)";
CM_ SG_ 691 VCRIGHT_cabinTempGlassGridHeater "Right body controller: cabin temp glass grid heater; raw 255 = signal not available (SNA)";
CM_ SG_ 691 VCRIGHT_hvacAirflowReasonRight "Right body controller: hvac airflow reason right";
CM_ SG_ 691 VCRIGHT_hvacAirflowReasonLeft "Right body controller: hvac airflow reason left";
CM_ SG_ 691 VCRIGHT_hvacMassflowTargetLeft "Right body controller: hvac massflow target left";
CM_ SG_ 691 VCRIGHT_hvacMassflowTargetRight "Right body controller: hvac massflow target right";
CM_ SG_ 691 VCRIGHT_solarLoadLeftOccupantFil "Right body controller: solar load left occupant filt; raw 127 = signal not available (SNA)";
CM_ SG_ 691 VCRIGHT_solarLoadRightOccupantFi "Right body controller: solar load right occupant filt; raw 127 = signal not available (SNA)";
CM_ SG_ 691 VCRIGHT_windshieldRHCapped "Estimated windshield relative humidity";
CM_ SG_ 691 VCRIGHT_feedbackWarmUpScalar "Right body controller: feedback warm up scalar";
CM_ SG_ 691 VCRIGHT_maxMassflowScalarWarmUp "Right body controller: max massflow scalar warm up";
CM_ SG_ 691 VCRIGHT_feedforwardWarmUpScalar "Right body controller: feedforward warm up scalar";
CM_ SG_ 691 VCRIGHT_frontSeatHeatBackrestPwr "Right body controller: front seat heat backrest pwr";
CM_ SG_ 691 VCRIGHT_maxMassflowScalar "Right body controller: max massflow scalar";
CM_ SG_ 691 VCRIGHT_massflowTargetAutoInManu "Right body controller: massflow target auto in manual mode";
CM_ SG_ 691 VCRIGHT_airflowReasonAutoInManua "Right body controller: airflow reason auto in manual mode";
CM_ SG_ 691 VCRIGHT_airflowReasonAutoIn_0001 "Right body controller: airflow reason auto in manual mode left";
CM_ SG_ 691 VCRIGHT_airflowReasonAutoIn_0002 "Right body controller: airflow reason auto in manual mode right";
CM_ SG_ 691 VCRIGHT_hvacTorqueMassflowQuadra "Right body controller: hvac torque massflow quadratic fit";
CM_ SG_ 691 VCRIGHT_vocSweatMassSeat "Right body controller: voc sweat mass seat; raw 255 = signal not available (SNA)";
CM_ SG_ 691 VCRIGHT_vocSweatConcentrationAir "Right body controller: voc sweat concentration air; raw 255 = signal not available (SNA)";
CM_ SG_ 691 VCRIGHT_hvacBiLevelWhsldRhEst "Right body controller: hvac bi level whsld rh est";
CM_ SG_ 691 VCRIGHT_steeringWheelSurfaceTemp "Right body controller: steering wheel surface temp est; raw 1023 = signal not available (SNA)";
CM_ SG_ 691 VCRIGHT_steeringWheelSurfac_0001 "Right body controller: steering wheel surface temp tgt; raw 1023 = signal not available (SNA)";
CM_ SG_ 691 VCRIGHT_timeToComfortHeating "Right body controller: time to comfort heating";
CM_ SG_ 691 VCRIGHT_timeToComfortCooling "Right body controller: time to comfort cooling";
CM_ SG_ 691 VCRIGHT_cabinWaterMassRaw "Right body controller: cabin water mass raw; raw 255 = signal not available (SNA)";
CM_ SG_ 691 VCRIGHT_massflowSingleZoneSplit "Right body controller: massflow single zone split";
CM_ SG_ 691 VCRIGHT_VOCPurgeState "Right body controller: VOC purge state";
CM_ SG_ 691 VCRIGHT_cameraFoggingMonitorStat "Right body controller: camera fogging monitor state";
CM_ SG_ 691 VCRIGHT_windWeatherSource "Right body controller: wind weather source";
CM_ SG_ 691 VCRIGHT_humidityRatioWeatherSour "Right body controller: humidity ratio weather source";
CM_ SG_ 691 VCRIGHT_cabinOverheatProtectNotR "Reports all reasons cabin overheat protection is not running.";
CM_ SG_ 691 VCRIGHT_hvacIntakeReason "Reason for current intake door position";
CM_ SG_ 691 VCRIGHT_hvacCabinPurgeActive "Indicates if cabin purge is active";
CM_ SG_ 691 VCRIGHT_solarAzimuthCarRef "Right body controller: solar azimuth car ref; raw 1025 = signal not available (SNA)";
CM_ SG_ 691 VCRIGHT_massflowPulldownBias "Right body controller: massflow pulldown bias";
CM_ SG_ 691 VCRIGHT_evapPulldownBias "Right body controller: evap pulldown bias";
CM_ SG_ 691 VCRIGHT_modeledMassflowFresh "Right body controller: modeled massflow fresh";
CM_ SG_ 691 VCRIGHT_modeledMassflowRecirc "Right body controller: modeled massflow recirc";
CM_ SG_ 691 VCRIGHT_hvacLimpModeStatus "Reports the cabin model limp mode status.";
CM_ SG_ 691 VCRIGHT_hvacEstimatedCameraWinds "Right body controller: hvac estimated camera windshield RH; raw 255 = signal not available (SNA)";
CM_ SG_ 691 VCRIGHT_hvacRearVoltage "Right body controller: hvac rear voltage";
CM_ SG_ 691 VCRIGHT_cabinTempRoofL2 "Right body controller: cabin temp roof L2; raw 255 = signal not available (SNA)";
CM_ SG_ 691 VCRIGHT_cabinTempRoofL3 "Right body controller: cabin temp roof L3; raw 255 = signal not available (SNA)";
CM_ SG_ 691 VCRIGHT_odorRoutineState "Right body controller: odor routine state; raw 7 = signal not available (SNA)";
CM_ SG_ 691 VCRIGHT_rgbLedFrontCurrent "Current drawn by the front door RGB LED";
CM_ SG_ 691 VCRIGHT_rgbLedRearCurrent "Current drawn by the rear door RGB LED";
CM_ SG_ 691 VCRIGHT_rgbLedFrontOutput "The power state of the front door RGB LED";
CM_ SG_ 691 VCRIGHT_rgbLedRearOutput "The power state of the rear door RGB LED";
CM_ SG_ 691 VCRIGHT_cameraDefogState "State of the camera defog feature";
CM_ BO_ 1859 "Right body controller message: recall status; frame length observed on a vehicle bus";
CM_ SG_ 1859 VCRIGHT_systemRecallStatus "Recall state of superset of body controls ECUs; raw 0 = signal not available (SNA)";
CM_ SG_ 1859 VCRIGHT_seatRecallStatus "Right body controller: seat recall status; raw 0 = signal not available (SNA)";
CM_ SG_ 1859 VCRIGHT_mirrorRecallStatus "Recall status for the right side view mirror; raw 0 = signal not available (SNA)";
CM_ BO_ 1251 "Right body controller message: seat status; frame length observed on a vehicle bus";
CM_ SG_ 1251 VCRIGHT_seatStatusIndex "Right body controller: seat status index";
CM_ SG_ 1251 VC_AH_1RowRightSeatMovementHealt "Right body controller: AH 1 row right seat movement health";
CM_ SG_ 1251 VCRIGHT_frontSeatTrackPos "Motor encoder value representing front left seat track position";
CM_ SG_ 1251 VCRIGHT_frontSeatTrackCurrent "Current drawn by front left seat track motor";
CM_ SG_ 1251 VCRIGHT_frontSeatTrackDuty "Front left seat track motor duty cycle";
CM_ SG_ 1251 VCRIGHT_frontSeatTrackState "State of front right seat track motor";
CM_ SG_ 1251 VCRIGHT_frontSeatTrackCalibrated "Right body controller: front seat track calibrated";
CM_ SG_ 1251 VCRIGHT_frontSeatTrackLog "Right body controller: front seat track log";
CM_ SG_ 1251 VCRIGHT_frontSeatTrackBridgeSt "Bridge state";
CM_ SG_ 1251 VCRIGHT_frontSeatTrackPercentage "Communicates position of front seat track as percentage of its total range";
CM_ SG_ 1251 VCRIGHT_frontSeatBackPos "Motor encoder value representing front right seat backrest position";
CM_ SG_ 1251 VCRIGHT_frontSeatBackCurrent "Current drawn by front right seat backrest motor";
CM_ SG_ 1251 VCRIGHT_frontSeatBackDuty "Front right seat backrest motor duty cycle";
CM_ SG_ 1251 VCRIGHT_frontSeatBackState "Active state of front right seat backrest";
CM_ SG_ 1251 VCRIGHT_frontSeatBackCalibrated "Right body controller: front seat back calibrated";
CM_ SG_ 1251 VCRIGHT_frontSeatBackLog "Right body controller: front seat back log";
CM_ SG_ 1251 VCRIGHT_frontSeatBackBridgeSt "Bridge state";
CM_ SG_ 1251 VCRIGHT_frontSeatBackPercentage "Communicates position of front seat backrest recline as percentage of its total range";
CM_ SG_ 1251 VCRIGHT_frontSeatLiftPos "Motor encoder value representing front left seat lift position";
CM_ SG_ 1251 VCRIGHT_frontSeatLiftCurrent "Current drawn by front left seat lift motor";
CM_ SG_ 1251 VCRIGHT_frontSeatLiftDuty "Front left seat lift motor duty cycle";
CM_ SG_ 1251 VCRIGHT_frontSeatLiftState "Status of front left seat motor";
CM_ SG_ 1251 VCRIGHT_frontSeatLiftCalibrated "Right body controller: front seat lift calibrated";
CM_ SG_ 1251 VCRIGHT_frontSeatLiftLog "Right body controller: front seat lift log";
CM_ SG_ 1251 VCRIGHT_frontSeatLiftBridgeSt "Bridge state";
CM_ SG_ 1251 VCRIGHT_frontSeatLiftPercentage "Communicates position of front seat lift as percentage of its total range";
CM_ SG_ 1251 VCRIGHT_frontSeatTiltPos "Motor encoder value representing front left seat tilt position";
CM_ SG_ 1251 VCRIGHT_frontSeatTiltCurrent "Current drawn by front left seat tilt motor";
CM_ SG_ 1251 VCRIGHT_frontSeatTiltDuty "Front left seat tilt motor duty cycle";
CM_ SG_ 1251 VCRIGHT_frontSeatTiltState "State of front right seat tilt motor";
CM_ SG_ 1251 VCRIGHT_frontSeatTiltCalibrated "Right body controller: front seat tilt calibrated";
CM_ SG_ 1251 VCRIGHT_frontSeatTiltLog "Right body controller: front seat tilt log";
CM_ SG_ 1251 VCRIGHT_frontSeatTiltBridgeSt "Bridge state";
CM_ SG_ 1251 VCRIGHT_frontSeatTiltPercentage "Communicates position of front seat tilt as percentage of its total range";
CM_ SG_ 1251 VCRIGHT_lumbarAState "State of front right seat lumbar bladder A";
CM_ SG_ 1251 VCRIGHT_lumbarBState "State of front right lumbar bladder B";
CM_ SG_ 1251 VCRIGHT_lumbarAPressureHpa "Right body controller: lumbar a pressure hpa";
CM_ SG_ 1251 VCRIGHT_lumbarAPressureHpaFilt "logs filtered pressure of right seat lumbar bladder A";
CM_ SG_ 1251 VCRIGHT_lumbarBPressureHpa "Right body controller: lumbar b pressure hpa";
CM_ SG_ 1251 VCRIGHT_lumbarBPressureHpaFilt "logs filtered pressure of right seat lumbar bladder B";
CM_ SG_ 1251 VCRIGHT_lumbarActiveTooLongErr "Error reported by lumbar ECU: Valve activated too long";
CM_ SG_ 1251 VCRIGHT_lumbarMaxPErr "Error reported by lumbar ECU: max bladder pressure reached";
CM_ SG_ 1251 VCRIGHT_lumbarOvercurrentErr "Error reported by lumbar ECU: pump overcurrent";
CM_ SG_ 1251 VCRIGHT_lumbarMaxOperatingPErr "Error reported by lumbar ECU: max bladder operating pressure reached";
CM_ SG_ 1251 VCRIGHT_lumbarMinPErr "Error reported by lumbar ECU: min bladder pressure reached";
CM_ SG_ 1251 VCRIGHT_lumbarGeneralErr "Error reported by lumbar ECU: general error";
CM_ SG_ 1251 VCRIGHT_lumbarDevMaxPumpPressA "System has reached Tesla specified maximum pressure for lumbar bladder A";
CM_ SG_ 1251 VCRIGHT_lumbarDevMaxPumpPressB "System has reached Tesla specified maximum pressure for lumbar bladder B";
CM_ SG_ 1251 VCRIGHT_frontSeatTrackPosReal "Front right seat track position in millimeters";
CM_ SG_ 1251 VCRIGHT_frontSeatBackPosReal "Front right seat backrest position in degrees";
CM_ SG_ 1251 VCRIGHT_frontSeatLiftPosReal "Front right seat lift position in millimeters";
CM_ SG_ 1251 VCRIGHT_frontSeatTiltPosReal "Front right seat tilt position in degrees";
CM_ SG_ 1251 VCRIGHT_frontSeatThighSuppo_0001 "Position of front seat thigh support in a physical unit";
CM_ SG_ 1251 VCRIGHT_frontSeatTrackPosOffset "Communicates post calibration position offset of front right seat track in a physical unit";
CM_ SG_ 1251 VCRIGHT_frontSeatBackPosOffset "Communicates post calibration position offset of front right seat backrest in a physical unit";
CM_ SG_ 1251 VCRIGHT_frontSeatLiftPosOffset "Communicates post calibration position offset of front right seat lift in a physical unit";
CM_ SG_ 1251 VCRIGHT_frontSeatTiltPosOffset "Communicates post calibration position offset of front right seat tilt in a physical unit";
CM_ SG_ 1251 VCRIGHT_frontSeatThighSupportPos "Post calibration position offset of front seat thigh support in a physical unit";
CM_ SG_ 1251 VCRIGHT_lumbarAPressurePercentag "Percentage of lumbar bladder A pressure relative to maximum pressure";
CM_ SG_ 1251 VCRIGHT_lumbarBPressurePercentag "Percentage of lumbar bladder B pressure relative to maximum pressure";
CM_ BO_ 739 "Right body controller message: seat status2; frame length observed on a vehicle bus";
CM_ SG_ 739 VCRIGHT_seatStatus2Index "Right body controller: seat status2 index";
CM_ SG_ 739 VCRIGHT_frontSeatHeatCurrent "Right body controller: front seat heat current; raw 12 = signal not available (SNA)";
CM_ SG_ 739 VCRIGHT_frontSeatHeatDuty "Right body controller: front seat heat duty";
CM_ SG_ 739 VCRIGHT_frontSeatHeatTmp "Right body controller: front seat heat tmp";
CM_ SG_ 739 VCRIGHT_frontSeatHeatTmpTarget "Target temperature for front right seat heater";
CM_ SG_ 739 VCRIGHT_frontSeatHeatInhibited "Front right seat heater duty cycle";
CM_ SG_ 739 VCRIGHT_frontSeatHeatPowered "Right body controller: front seat heat powered";
CM_ SG_ 739 VC_AH_1RowRightSeatHeatVentHealt "Right body controller: AH 1 row right seat heat vent health";
CM_ SG_ 739 VCRIGHT_rearLSeatHeatCurrent "Current drawn by rear center seat heater";
CM_ SG_ 739 VCRIGHT_rearLSeatHeatDuty "Right body controller: rear l seat heat duty";
CM_ SG_ 739 VCRIGHT_rearLSeatHeatTmp "Right body controller: rear l seat heat tmp";
CM_ SG_ 739 VCRIGHT_rearLSeatHeatTmpTarget "Right body controller: rear l seat heat tmp target";
CM_ SG_ 739 VCRIGHT_rearLSeatHeatInhibited "Right body controller: rear l seat heat inhibited";
CM_ SG_ 739 VCRIGHT_rearLSeatHeatPowered "Right body controller: rear l seat heat powered";
CM_ SG_ 739 VCRIGHT_rearCSeatHeatCurrent "Right body controller: rear c seat heat current";
CM_ SG_ 739 VCRIGHT_rearCSeatHeatDuty "Right body controller: rear c seat heat duty";
CM_ SG_ 739 VCRIGHT_rearCSeatHeatTmp "Right body controller: rear c seat heat tmp";
CM_ SG_ 739 VCRIGHT_rearCSeatHeatTmpTarget "Right body controller: rear c seat heat tmp target";
CM_ SG_ 739 VCRIGHT_rearCSeatHeatInhibited "Right body controller: rear c seat heat inhibited";
CM_ SG_ 739 VCRIGHT_rearCSeatHeatPowered "Right body controller: rear c seat heat powered";
CM_ SG_ 739 VCRIGHT_rearRSeatHeatCurrent "Right body controller: rear r seat heat current";
CM_ SG_ 739 VCRIGHT_rearRSeatHeatDuty "Right body controller: rear r seat heat duty";
CM_ SG_ 739 VCRIGHT_rearRSeatHeatTmp "Right body controller: rear r seat heat tmp";
CM_ SG_ 739 VCRIGHT_rearRSeatHeatTmpTarget "Right body controller: rear r seat heat tmp target";
CM_ SG_ 739 VCRIGHT_rearRSeatHeatInhibited "Right body controller: rear r seat heat inhibited";
CM_ SG_ 739 VCRIGHT_rearRSeatHeatPowered "Right body controller: rear r seat heat powered";
CM_ SG_ 739 VCRIGHT_2RowSeatReclineState "Reports the active state of the 2nd row seat recliner; raw 15 = signal not available (SNA)";
CM_ SG_ 739 VCRIGHT_2RowSeatReclineDuty "Reports the 2nd row seat recliner motor duty cycle";
CM_ SG_ 739 VCRIGHT_2RowSeatReclineCurrent "Reports the 2nd row seat recliner motor current";
CM_ SG_ 739 VCRIGHT_2RowSeatReclineCalibrate "Reports calibration status of the 2nd row seat recliner";
CM_ SG_ 739 VCRIGHT_2RowSeatReclinePositionR "Reports the 2nd row seat recliner raw encoder count";
CM_ SG_ 739 VCRIGHT_2RowSeatReclineAngle "Reports the position of the 2nd row seat recliner in degrees";
CM_ SG_ 739 VCRIGHT_2RowSeatReclineAbsPosSwi "Reports the status of 2nd row seat recline absolute position (comfort zone) switch; raw 0 = signal not available (SNA)";
CM_ SG_ 739 VCRIGHT_2RowSeatReclinePositionS "Reports the active position state of the 2nd row seat recliner; raw 4 = signal not available (SNA)";
CM_ SG_ 739 VCRIGHT_2RowSeatReclineAdjustmen "Indicates whether adjustment requests are currently permitted for the rear seat recliner";
CM_ SG_ 739 VCRIGHT_2RowSeatReclineFoldAllow "Indicates whether auto-fold requests are currently permitted for the rear seat recliner";
CM_ SG_ 739 VCRIGHT_2RowSeatReclineUnfoldAll "Indicates whether auto-unfold requests are currently permitted for the rear seat recliner";
CM_ SG_ 739 VCRIGHT_2RowSeatReclineNextToggl "Right body controller: 2 row seat recline next toggle direction; raw 2 = signal not available (SNA)";
CM_ SG_ 739 VCRIGHT_2RowSeatReclineChoreoBlo "Right body controller: 2 row seat recline choreo blocked by occupancy";
CM_ SG_ 739 VCRIGHT_2RowSeat1RClashAvoidance "Right body controller: 2 row seat1 r clash avoidance blocked reason";
CM_ SG_ 739 VCRIGHT_2RowSeat1RClashAvoi_0001 "Right body controller: 2 row seat1 r clash avoidance state";
CM_ SG_ 739 VCRIGHT_2RowSeatReclineAbsP_0001 "Right body controller: 2 row seat recline abs pos switch trans point";
CM_ SG_ 739 VC_AH_2RowRightSeatMovementHealt "Right body controller: AH 2 row right seat movement health";
CM_ SG_ 739 VCRIGHT_3RowSeatReclineState "Reports active state of the rear seat recliner; raw 15 = signal not available (SNA)";
CM_ SG_ 739 VCRIGHT_3RowSeatReclineDuty "Reports the third row seat recliner motor duty cycle";
CM_ SG_ 739 VCRIGHT_3RowSeatReclineCurrent "Reports the third row seat recliner motor current";
CM_ SG_ 739 VCRIGHT_3RowSeatReclineCalibrate "Reports calibration status of the third row seat recliner";
CM_ SG_ 739 VCRIGHT_3RowSeatReclinePositionR "Reports the third row seat recliner raw encoder count";
CM_ SG_ 739 VCRIGHT_3RowSeatReclineAngle "Reports position of the 3rd row seat recliner in degrees";
CM_ SG_ 739 VCRIGHT_3RowSeatReclineNextToggl "Right body controller: 3 row seat recline next toggle direction; raw 2 = signal not available (SNA)";
CM_ SG_ 739 VCRIGHT_3RRightSeatHeatCurrent "Current drawn by 3rd row right seat heater";
CM_ SG_ 739 VCRIGHT_3RRightSeatHeatDuty "3rd row right seat heater duty cycle";
CM_ SG_ 739 VCRIGHT_3RRightSeatHeatTmp "Temperature of 3rd row right seat heater as reported by NTC";
CM_ SG_ 739 VCRIGHT_3RRightSeatHeatTmpTarget "Target temperature for 3rd row right seat heater";
CM_ SG_ 739 VCRIGHT_3RRightSeatHeatInhibited "Status describing whether 3rd row right seat heat is inhibited";
CM_ SG_ 739 VCRIGHT_3RowSeatReclinePositionS "Reports active position state of the rear seat recliner; raw 4 = signal not available (SNA)";
CM_ SG_ 739 VCRIGHT_3RowSeatReclineAdjustmen "Indicates whether adjustment requests are currently permitted for the rear seat recliner";
CM_ SG_ 739 VCRIGHT_3RowSeatReclineFoldAllow "Indicates whether auto-fold requests are currently permitted for the rear seat recliner";
CM_ SG_ 739 VCRIGHT_3RowSeatReclineUnfoldAll "Indicates whether auto-unfold requests are currently permitted for the rear seat recliner";
CM_ SG_ 739 VCRIGHT_3RowSeatReclineChoreoBlo "Right body controller: 3 row seat recline choreo blocked by occupancy";
CM_ SG_ 739 VCRIGHT_3RowSeatReclineAbsPosSwi "Reports status of 2R seat recline absolute position (comfort zone) switch; raw 0 = signal not available (SNA)";
CM_ BO_ 835 "Right body controller message: status; frame length observed on a vehicle bus";
CM_ SG_ 835 VCRIGHT_autonomyBehaviorStatus "Right body controller: autonomy behavior status";
CM_ SG_ 835 VCRIGHT_LVBatteryTypeDBG "Right body controller: LV battery type DBG";
CM_ SG_ 835 VCRIGHT_rearDefrostState "Right body controller: rear defrost state; raw 0 = signal not available (SNA)";
CM_ SG_ 835 VCRIGHT_mirrorHeatState "Right body controller: mirror heat state; raw 0 = signal not available (SNA)";
CM_ SG_ 835 VCRIGHT_OTAState "Right body controller: OTA state";
CM_ SG_ 835 VCRIGHT_5AVoltage "Right body controller: 5 a voltage";
CM_ SG_ 835 VCRIGHT_vbatProt "Input voltage monitor to controller";
CM_ SG_ 835 VCRIGHT_rationalityAggregateCurr "Right body controller: rationality aggregate current";
CM_ SG_ 835 VCRIGHT_eFuseMgmtVoltageMonitor "Right body controller: e fuse mgmt voltage monitor";
CM_ SG_ 835 VCRIGHT_isSteeringWheelHeaterReq "Right body controller: is steering wheel heater req";
CM_ SG_ 835 VCRIGHT_steeringWheelHeaterDCTgt "Right body controller: steering wheel heater DC tgt; raw 127 = signal not available (SNA)";
CM_ BO_ 963 "Right body controller message: switch status; frame length observed on a vehicle bus";
CM_ SG_ 963 VCRIGHT_switchStatusIndex "Right body controller: switch status index";
CM_ SG_ 963 VCRIGHT_frontBuckleSwitch "Right body controller: front buckle switch";
CM_ SG_ 963 VCRIGHT_rearCenterBuckleSwitch "Right body controller: rear center buckle switch";
CM_ SG_ 963 VCRIGHT_rearRightBuckleSwitch "Right body controller: rear right buckle switch";
CM_ SG_ 963 VCRIGHT_trunkExtReleasePressedPe "Right body controller: trunk ext release pressed persist";
CM_ SG_ 963 VCRIGHT_frontSeatTrackBack "Right body controller: front seat track back; raw 0 = signal not available (SNA)";
CM_ SG_ 963 VCRIGHT_frontSeatTrackForward "Right body controller: front seat track forward; raw 0 = signal not available (SNA)";
CM_ SG_ 963 VCRIGHT_frontSeatTiltDown "Right body controller: front seat tilt down; raw 0 = signal not available (SNA)";
CM_ SG_ 963 VCRIGHT_frontSeatTiltUp "Right body controller: front seat tilt up; raw 0 = signal not available (SNA)";
CM_ SG_ 963 VCRIGHT_frontSeatLiftDown "Right body controller: front seat lift down; raw 0 = signal not available (SNA)";
CM_ SG_ 963 VCRIGHT_frontSeatLiftUp "Right body controller: front seat lift up; raw 0 = signal not available (SNA)";
CM_ SG_ 963 VCRIGHT_frontSeatBackrestBack "Right body controller: front seat backrest back; raw 0 = signal not available (SNA)";
CM_ SG_ 963 VCRIGHT_frontSeatBackrestForward "Right body controller: front seat backrest forward; raw 0 = signal not available (SNA)";
CM_ SG_ 963 VCRIGHT_frontSeatLumbarDown "Right body controller: front seat lumbar down; raw 0 = signal not available (SNA)";
CM_ SG_ 963 VCRIGHT_frontSeatLumbarUp "Right body controller: front seat lumbar up; raw 0 = signal not available (SNA)";
CM_ SG_ 963 VCRIGHT_frontSeatLumbarIn "Right body controller: front seat lumbar in; raw 0 = signal not available (SNA)";
CM_ SG_ 963 VCRIGHT_frontSeatLumbarOut "Right body controller: front seat lumbar out; raw 0 = signal not available (SNA)";
CM_ SG_ 963 VCRIGHT_2RowSeatReclineSwitch "Second row seat recline switch";
CM_ SG_ 963 VCRIGHT_2RowSeatBackrestFoldSwit "Second row seat backrest fold switch";
CM_ SG_ 963 VCRIGHT_frontSeatThighSupportExt "Status of the switch used to extend front seat thigh support; raw 0 = signal not available (SNA)";
CM_ SG_ 963 VCRIGHT_frontHandlePWM "Right body controller: front handle PWM";
CM_ SG_ 963 VCRIGHT_hvacHeatingAllowedLeft "Right body controller: hvac heating allowed left";
CM_ SG_ 963 VCRIGHT_rearHandlePWM "Right body controller: rear handle PWM";
CM_ SG_ 963 VCRIGHT_gloveboxLightCurrent "Current through the glovebox LED";
CM_ SG_ 963 VCRIGHT_frontSeatALR "Front right seat automatic locking retractor switch; raw 0 = signal not available (SNA)";
CM_ SG_ 963 VCRIGHT_frontSeatResistiveOccupa "Front right seat occupancy status; raw 0 = signal not available (SNA)";
CM_ SG_ 963 VCRIGHT_2RowSeatReclineSwitchpac "State of the right second row powered recline adjustment switchpack";
CM_ SG_ 963 VCRIGHT_hvacHeatingAllowedRight "Right body controller: hvac heating allowed right";
CM_ SG_ 963 VCRIGHT_frontSeatThighSupportRet "Status of the switch used to retract front seat thigh support; raw 0 = signal not available (SNA)";
CM_ BO_ 899 "Right body controller message: ths status; frame length observed on a vehicle bus";
CM_ SG_ 899 VCRIGHT_thsActive "Right body controller: ths active";
CM_ SG_ 899 VCRIGHT_thsTemperature "Tesla HVAC sensor temperature; raw 255 = signal not available (SNA)";
CM_ SG_ 899 VCRIGHT_thsState "Right body controller: ths state";
CM_ SG_ 899 VCRIGHT_thsLINCurrentSchedule "Right body controller: ths LIN current schedule";
CM_ SG_ 899 VCRIGHT_thsDetected "Tesla HVAC sensor connection is detected";
CM_ SG_ 899 VCRIGHT_thsHumidity "Tesla HVAC sensor humidity; raw 127 = signal not available (SNA)";
CM_ SG_ 899 VCRIGHT_estimatedVehicleSituatio "Right body controller: estimated vehicle situation";
CM_ SG_ 899 VCRIGHT_thsSolarLoadInfrared "Solar power hitting the vehicle in the infrared spectrum; raw 1023 = signal not available (SNA)";
CM_ SG_ 899 VCRIGHT_thsSolarLoadVisible "Solar power hitting the vehicle in the visible spectrum; raw 1023 = signal not available (SNA)";
CM_ SG_ 899 VCRIGHT_estimatedThsSolarLoad "Right body controller: estimated ths solar load; raw 1023 = signal not available (SNA)";
CM_ SG_ 899 VCRIGHT_hvacFastLoggingEnabled "Right body controller: hvac fast logging enabled";
CM_ BO_ 1545 "Right body controller message: uds response; frame length from the layout, not yet observed on a vehicle bus";
CM_ SG_ 1545 VCRIGHT_udsResponseData_H "Right body controller: uds response data h";
CM_ SG_ 1545 VCRIGHT_udsResponseData_L "Right body controller: uds response data l";
CM_ BO_ 1059 "Right body controller message: veh nm; frame length observed on a vehicle bus";
CM_ SG_ 1059 VCRIGHT_nmGoingToSleep "Right body controller: nm going to sleep";
CM_ SG_ 1059 VCRIGHT_nmWakeUpBus "Right body controller: nm wake up bus";
CM_ SG_ 1059 VCRIGHT_nmKeepAwakeReason "Reason controller is preventing the vehicle from sleeping; raw 0 = signal not available (SNA)";
CM_ SG_ 1059 VCRIGHT_nmWakeUpReason "Right body controller: nm wake up reason";
CM_ SG_ 1059 VCRIGHT_nmDebugWakeUp "Right body controller: nm debug wake up";
CM_ SG_ 1059 VCRIGHT_nmEthKeepAwakeReason "Right body controller: nm eth keep awake reason; raw 0 = signal not available (SNA)";
CM_ SG_ 1059 VCRIGHT_nmChKeepAwakeReason "Right body controller: nm ch keep awake reason; raw 0 = signal not available (SNA)";
CM_ BO_ 707 "Right body controller message: window status; frame length observed on a vehicle bus";
CM_ SG_ 707 VCRIGHT_windowStatusIndex "Right body controller: window status index";
CM_ SG_ 707 VCRIGHT_windowStateRF "Status of right front window motor";
CM_ SG_ 707 VCRIGHT_windowTrimClearMoveReque "Reports a request for whether windows should enter or exit trim clear mode. Signal is only valid if Vehicle Controller Left (VCLEFT) is on driver side.";
CM_ SG_ 707 VCRIGHT_windowDutyRF "Right body controller: window duty RF";
CM_ SG_ 707 VCRIGHT_windowTrimClearActiveReq "Reports whether window trim clear is active. Signal is only valid if Vehicle Controller Left (VCLEFT) is on driver side; raw 0 = signal not available (SNA)";
CM_ SG_ 707 VCRIGHT_windowCurrentRF "Current drawn by left front window regulator";
CM_ SG_ 707 VCRIGHT_windowPositionRF "Right body controller: window position RF; raw 1 = signal not available (SNA)";
CM_ SG_ 707 VCRIGHT_windowCalibratedRF "Calibration status of right front window motor";
CM_ SG_ 707 VCRIGHT_windowStateRR "Status of right rear window motor";
CM_ SG_ 707 VCRIGHT_windowDutyRR "Right body controller: window duty RR";
CM_ SG_ 707 VCRIGHT_windowCurrentRR "Current drawn by left rear window regulator";
CM_ SG_ 707 VCRIGHT_windowPositionRR "Right body controller: window position RR";
CM_ SG_ 707 VCRIGHT_windowCalibratedRR "Calibration status of right rear window motor";
CM_ SG_ 707 VCRIGHT_windowThermalTCRF "Right body controller: window thermal TCRF";
CM_ SG_ 707 VCRIGHT_windowThermalModeRF "Right body controller: window thermal mode RF; raw 0 = signal not available (SNA)";
CM_ SG_ 707 VCRIGHT_windowStopReasonRF "Reason for right front window stopping motion";
CM_ SG_ 707 VCRIGHT_windowStopReqReasonRF "Reason for right front window stopping motion";
CM_ SG_ 707 VCRIGHT_windowThermalTCRR "Right body controller: window thermal TCRR";
CM_ SG_ 707 VCRIGHT_windowThermalModeRR "Right body controller: window thermal mode RR; raw 0 = signal not available (SNA)";
CM_ SG_ 707 VCRIGHT_windowStopReasonRR "Reason for right rear window stopping motion";
CM_ SG_ 707 VCRIGHT_windowStopReqReasonRR "Reason for right rear window stopping motion";
CM_ SG_ 707 VCRIGHT_windowControlStateRF "Window control state";
CM_ SG_ 707 VCRIGHT_windowCtrlUnavailableRF "Window control unavailable reason";
CM_ SG_ 707 VCRIGHT_windowControlStateRR "Window control state";
CM_ SG_ 707 VCRIGHT_windowCtrlUnavailableRR "Window control unavailable reason";
CM_ SG_ 707 VCRIGHT_windowPositionStateRF "Reports the window position state";
CM_ SG_ 707 VCRIGHT_windowPositionStateRR "Window position state";
CM_ SG_ 707 VCRIGHT_windowVehGearStateRF "Window's interpretation of vehicle gear state; raw 0 = signal not available (SNA)";
CM_ SG_ 707 VCRIGHT_windowVehGearStateRR "Window's interpretation of vehicle gear state; raw 0 = signal not available (SNA)";
CM_ SG_ 707 VCRIGHT_windowSpeedTableStatusRF "Speed table build status of right front window; raw 0 = signal not available (SNA)";
CM_ SG_ 707 VCRIGHT_windowSpeedTableStatusRR "Speed table build status of right rear window; raw 0 = signal not available (SNA)";
CM_ BO_ 969 "Vehicle security controller message: BLE endpoint info; frame length from the layout, not yet observed on a vehicle bus";
CM_ SG_ 969 VCSEC_BLEEndpointInfoIndex "Vehicle security controller: BLE endpoint info index";
CM_ SG_ 969 VCSEC_BLECENTERComponentID "Vehicle security controller: BLECENTER component ID";
CM_ SG_ 969 VCSEC_BLECENTERPcbaID "Vehicle security controller: BLECENTER pcba ID";
CM_ SG_ 969 VCSEC_BLECENTERAssemblyID "Vehicle security controller: BLECENTER assembly ID";
CM_ SG_ 969 VCSEC_BLECENTERUsageID "Vehicle security controller: BLECENTER usage ID";
CM_ SG_ 969 VCSEC_BLECENTERCrc "Vehicle security controller: BLECENTER crc";
CM_ SG_ 969 VCSEC_BLELEFTAppGitHashByte "Vehicle security controller: BLELEFT app git hash byte";
CM_ SG_ 969 VCSEC_BLELEFTComponentID "Vehicle security controller: BLELEFT component ID";
CM_ SG_ 969 VCSEC_BLELEFTPcbaID "Vehicle security controller: BLELEFT pcba ID";
CM_ SG_ 969 VCSEC_BLELEFTAssemblyID "Vehicle security controller: BLELEFT assembly ID";
CM_ SG_ 969 VCSEC_BLELEFTUsageID "Vehicle security controller: BLELEFT usage ID";
CM_ SG_ 969 VCSEC_BLELEFTCrc "Vehicle security controller: BLELEFT crc";
CM_ SG_ 969 VCSEC_BLERIGHTAppGitHashByte "Vehicle security controller: BLERIGHT app git hash byte";
CM_ SG_ 969 VCSEC_BLERIGHTComponentID "Vehicle security controller: BLERIGHT component ID";
CM_ SG_ 969 VCSEC_BLERIGHTPcbaID "Vehicle security controller: BLERIGHT pcba ID";
CM_ SG_ 969 VCSEC_BLERIGHTAssemblyID "Vehicle security controller: BLERIGHT assembly ID";
CM_ SG_ 969 VCSEC_BLERIGHTUsageID "Vehicle security controller: BLERIGHT usage ID";
CM_ SG_ 969 VCSEC_BLERIGHTCrc "Vehicle security controller: BLERIGHT crc";
CM_ SG_ 969 VCSEC_BLEREARAppGitHashByte "Vehicle security controller: BLEREAR app git hash byte";
CM_ SG_ 969 VCSEC_BLEREARComponentID "Vehicle security controller: BLEREAR component ID";
CM_ SG_ 969 VCSEC_BLEREARPcbaID "Vehicle security controller: BLEREAR pcba ID";
CM_ SG_ 969 VCSEC_BLEREARAssemblyID "Vehicle security controller: BLEREAR assembly ID";
CM_ SG_ 969 VCSEC_BLEREARUsageID "Vehicle security controller: BLEREAR usage ID";
CM_ SG_ 969 VCSEC_BLEREARCrc "Vehicle security controller: BLEREAR crc";
CM_ SG_ 969 VCSEC_UWBRightCrc "Vehicle security controller: UWB right crc";
CM_ SG_ 969 VCSEC_UWBRightRadioConfigState "Vehicle security controller: UWB right radio config state";
CM_ SG_ 969 VCSEC_UWBRightUpdateStatus "Vehicle security controller: UWB right update status; raw 7 = signal not available (SNA)";
CM_ SG_ 969 VCSEC_UWBRightRetryLimitReached "Vehicle security controller: UWB right retry limit reached";
CM_ SG_ 969 VCSEC_UWBRightDspVersion "Vehicle security controller: UWB right dsp version";
CM_ SG_ 969 VCSEC_UWBRightComponentID "Vehicle security controller: UWB right component ID";
CM_ SG_ 969 VCSEC_UWBRightPcbaID "Vehicle security controller: UWB right pcba ID";
CM_ SG_ 969 VCSEC_UWBRightAssemblyID "Vehicle security controller: UWB right assembly ID";
CM_ SG_ 969 VCSEC_UWBRightUsageID "Vehicle security controller: UWB right usage ID";
CM_ SG_ 969 VCSEC_UWBRearRightCrc "Vehicle security controller: UWB rear right crc";
CM_ SG_ 969 VCSEC_UWBRearRightRadioConfigSta "Vehicle security controller: UWB rear right radio config state";
CM_ SG_ 969 VCSEC_UWBRearRightUpdateStatus "Vehicle security controller: UWB rear right update status; raw 7 = signal not available (SNA)";
CM_ SG_ 969 VCSEC_UWBRearRightRetryLimitReac "Vehicle security controller: UWB rear right retry limit reached";
CM_ SG_ 969 VCSEC_UWBRearRightDspVersion "Vehicle security controller: UWB rear right dsp version";
CM_ SG_ 969 VCSEC_UWBRearRightComponentID "Vehicle security controller: UWB rear right component ID";
CM_ SG_ 969 VCSEC_UWBRearRightPcbaID "Vehicle security controller: UWB rear right pcba ID";
CM_ SG_ 969 VCSEC_UWBRearRightAssemblyID "Vehicle security controller: UWB rear right assembly ID";
CM_ SG_ 969 VCSEC_UWBRearRightUsageID "Vehicle security controller: UWB rear right usage ID";
CM_ SG_ 969 VCSEC_UWBRearLeftCrc "Vehicle security controller: UWB rear left crc";
CM_ SG_ 969 VCSEC_UWBRearLeftRadioConfigStat "Vehicle security controller: UWB rear left radio config state";
CM_ SG_ 969 VCSEC_UWBRearLeftUpdateStatus "Vehicle security controller: UWB rear left update status; raw 7 = signal not available (SNA)";
CM_ SG_ 969 VCSEC_UWBRearLeftRetryLimitReach "Vehicle security controller: UWB rear left retry limit reached";
CM_ SG_ 969 VCSEC_UWBRearLeftDspVersion "Vehicle security controller: UWB rear left dsp version";
CM_ SG_ 969 VCSEC_UWBRearLeftComponentID "Vehicle security controller: UWB rear left component ID";
CM_ SG_ 969 VCSEC_UWBRearLeftPcbaID "Vehicle security controller: UWB rear left pcba ID";
CM_ SG_ 969 VCSEC_UWBRearLeftAssemblyID "Vehicle security controller: UWB rear left assembly ID";
CM_ SG_ 969 VCSEC_UWBRearLeftUsageID "Vehicle security controller: UWB rear left usage ID";
CM_ SG_ 969 VCSEC_UWBRearCrc "Vehicle security controller: UWB rear crc";
CM_ SG_ 969 VCSEC_UWBRearRadioConfigState "Vehicle security controller: UWB rear radio config state";
CM_ SG_ 969 VCSEC_UWBRearUpdateStatus "Vehicle security controller: UWB rear update status; raw 7 = signal not available (SNA)";
CM_ SG_ 969 VCSEC_UWBRearRetryLimitReached "Vehicle security controller: UWB rear retry limit reached";
CM_ SG_ 969 VCSEC_UWBRearDspVersion "Vehicle security controller: UWB rear dsp version";
CM_ SG_ 969 VCSEC_UWBRearComponentID "Vehicle security controller: UWB rear component ID";
CM_ SG_ 969 VCSEC_UWBRearPcbaID "Vehicle security controller: UWB rear pcba ID";
CM_ SG_ 969 VCSEC_UWBRearAssemblyID "Vehicle security controller: UWB rear assembly ID";
CM_ SG_ 969 VCSEC_UWBRearUsageID "Vehicle security controller: UWB rear usage ID";
CM_ SG_ 969 VCSEC_UWBLeftCrc "Vehicle security controller: UWB left crc";
CM_ SG_ 969 VCSEC_UWBLeftRadioConfigState "Vehicle security controller: UWB left radio config state";
CM_ SG_ 969 VCSEC_UWBLeftUpdateStatus "Vehicle security controller: UWB left update status; raw 7 = signal not available (SNA)";
CM_ SG_ 969 VCSEC_UWBLeftRetryLimitReached "Vehicle security controller: UWB left retry limit reached";
CM_ SG_ 969 VCSEC_UWBLeftDspVersion "Vehicle security controller: UWB left dsp version";
CM_ SG_ 969 VCSEC_UWBLeftComponentID "Vehicle security controller: UWB left component ID";
CM_ SG_ 969 VCSEC_UWBLeftPcbaID "Vehicle security controller: UWB left pcba ID";
CM_ SG_ 969 VCSEC_UWBLeftAssemblyID "Vehicle security controller: UWB left assembly ID";
CM_ SG_ 969 VCSEC_UWBLeftUsageID "Vehicle security controller: UWB left usage ID";
CM_ SG_ 969 VCSEC_UWBCenterCrc "Vehicle security controller: UWB center crc";
CM_ SG_ 969 VCSEC_UWBCenterRadioConfigState "Vehicle security controller: UWB center radio config state";
CM_ SG_ 969 VCSEC_UWBCenterUpdateStatus "Vehicle security controller: UWB center update status; raw 7 = signal not available (SNA)";
CM_ SG_ 969 VCSEC_UWBCenterRetryLimitReached "Vehicle security controller: UWB center retry limit reached";
CM_ SG_ 969 VCSEC_UWBCenterDspVersion "Vehicle security controller: UWB center dsp version";
CM_ SG_ 969 VCSEC_UWBCenterComponentID "Vehicle security controller: UWB center component ID";
CM_ SG_ 969 VCSEC_UWBCenterPcbaID "Vehicle security controller: UWB center pcba ID";
CM_ SG_ 969 VCSEC_UWBCenterAssemblyID "Vehicle security controller: UWB center assembly ID";
CM_ SG_ 969 VCSEC_UWBCenterUsageID "Vehicle security controller: UWB center usage ID";
CM_ SG_ 969 VCSEC_BLERIGHTREARCrc "Vehicle security controller: BLERIGHTREAR crc";
CM_ SG_ 969 VCSEC_BLERIGHTREARComponentID "Vehicle security controller: BLERIGHTREAR component ID";
CM_ SG_ 969 VCSEC_BLERIGHTREARPcbaID "Vehicle security controller: BLERIGHTREAR pcba ID";
CM_ SG_ 969 VCSEC_BLERIGHTREARAssemblyID "Vehicle security controller: BLERIGHTREAR assembly ID";
CM_ SG_ 969 VCSEC_BLERIGHTREARUsageID "Vehicle security controller: BLERIGHTREAR usage ID";
CM_ SG_ 969 VCSEC_BLENFCCRADLECrc "Vehicle security controller: BLENFCCRADLE crc";
CM_ SG_ 969 VCSEC_BLENFCCRADLEComponentID "Vehicle security controller: BLENFCCRADLE component ID";
CM_ SG_ 969 VCSEC_BLENFCCRADLEPcbaID "Vehicle security controller: BLENFCCRADLE pcba ID";
CM_ SG_ 969 VCSEC_BLENFCCRADLEAssemblyID "Vehicle security controller: BLENFCCRADLE assembly ID";
CM_ SG_ 969 VCSEC_BLENFCCRADLEUsageID "Vehicle security controller: BLENFCCRADLE usage ID";
CM_ SG_ 969 VCSEC_BLELEFTREARCrc "Vehicle security controller: BLELEFTREAR crc";
CM_ SG_ 969 VCSEC_BLELEFTREARComponentID "Vehicle security controller: BLELEFTREAR component ID";
CM_ SG_ 969 VCSEC_BLELEFTREARPcbaID "Vehicle security controller: BLELEFTREAR pcba ID";
CM_ SG_ 969 VCSEC_BLELEFTREARAssemblyID "Vehicle security controller: BLELEFTREAR assembly ID";
CM_ SG_ 969 VCSEC_BLELEFTREARUsageID "Vehicle security controller: BLELEFTREAR usage ID";
CM_ BO_ 607 "Vehicle security controller message: child seat status; frame length from the layout, not yet observed on a vehicle bus";
CM_ SG_ 607 VCSEC_childSeat0_connectionState "Vehicle security controller: child seat0 connection state";
CM_ SG_ 607 VCSEC_childSeat0_taskDisconnecti "Vehicle security controller: child seat0 task disconnection reason";
CM_ SG_ 607 VCSEC_childSeat0_state "Vehicle security controller: child seat0 state";
CM_ SG_ 607 VCSEC_childSeat0_taskErrorCode "Vehicle security controller: child seat0 task error code";
CM_ SG_ 607 VCSEC_childSeat0_RSSI "Vehicle security controller: child seat0 RSSI; raw 127 = signal not available (SNA)";
CM_ SG_ 607 VCSEC_childSeat0_ISOFixStatus "Vehicle security controller: child seat0 ISO fix status";
CM_ SG_ 607 VCSEC_childSeat0_buckleStatus "Vehicle security controller: child seat0 buckle status";
CM_ SG_ 607 VCSEC_childSeat0_occupancyStatus "Vehicle security controller: child seat0 occupancy status";
CM_ SG_ 607 VCSEC_childSeat1_connectionState "Vehicle security controller: child seat1 connection state";
CM_ SG_ 607 VCSEC_childSeat1_taskDisconnecti "Vehicle security controller: child seat1 task disconnection reason";
CM_ SG_ 607 VCSEC_childSeat1_state "Vehicle security controller: child seat1 state";
CM_ SG_ 607 VCSEC_childSeat1_taskErrorCode "Vehicle security controller: child seat1 task error code";
CM_ SG_ 607 VCSEC_childSeat1_RSSI "Vehicle security controller: child seat1 RSSI; raw 127 = signal not available (SNA)";
CM_ SG_ 607 VCSEC_childSeat1_ISOFixStatus "Vehicle security controller: child seat1 ISO fix status";
CM_ SG_ 607 VCSEC_childSeat1_buckleStatus "Vehicle security controller: child seat1 buckle status";
CM_ SG_ 607 VCSEC_childSeat1_occupancyStatus "Vehicle security controller: child seat1 occupancy status";
CM_ SG_ 607 VCSEC_childPresenceDetectionWarn "Vehicle security controller: child presence detection warning active";
CM_ SG_ 607 VCSEC_childSeatScanStatus "Vehicle security controller: child seat scan status";
CM_ SG_ 607 VCSEC_childPresenceDetectionStat "Vehicle security controller: child presence detection state";
CM_ SG_ 607 VCSEC_childPresenceDetectionSupp "Vehicle security controller: child presence detection support type";
CM_ SG_ 607 VCSEC_childPresenceDetectionNoti "Vehicle security controller: child presence detection notification enabled";
BA_DEF_ BO_ "GenMsgCycleTime" INT 0 3600000;
BA_DEF_ BO_ "GenMsgSendType" ENUM "Cyclic","NotUsed","NotUsed","NotUsed","NotUsed","NotUsed","NotUsed","IfActive","NoMsgSendType","NotUsed";
BA_DEF_ BO_ "VFrameFormat" ENUM "StandardCAN","ExtendedCAN","reserved","J1939PG","reserved","reserved","reserved","reserved","reserved","reserved","reserved","reserved","reserved","reserved","StandardCAN_FD","ExtendedCAN_FD";
BA_DEF_ BO_ "CANFD_BRS" ENUM "0","1";
BA_DEF_ SG_ "GenSigSNA" STRING;
BA_DEF_ SG_ "SystemSignalLongSymbol" STRING;
BA_DEF_ SG_ "Confidence" ENUM "validated","plausible","layout-only","contradicted";
BA_DEF_DEF_ "GenMsgCycleTime" 0;
BA_DEF_DEF_ "GenMsgSendType" "NoMsgSendType";
BA_DEF_DEF_ "VFrameFormat" "StandardCAN";
BA_DEF_DEF_ "CANFD_BRS" "1";
BA_DEF_DEF_ "GenSigSNA" "";
BA_DEF_DEF_ "SystemSignalLongSymbol" "";
BA_DEF_DEF_ "Confidence" "layout-only";
BA_ "GenMsgCycleTime" BO_ 611 20;
BA_ "GenMsgSendType" BO_ 611 0;
BA_ "GenMsgCycleTime" BO_ 691 60;
BA_ "GenMsgSendType" BO_ 691 0;
BA_ "GenMsgCycleTime" BO_ 1859 1000;
BA_ "GenMsgSendType" BO_ 1859 0;
BA_ "GenMsgCycleTime" BO_ 1251 100;
BA_ "GenMsgSendType" BO_ 1251 0;
BA_ "GenMsgCycleTime" BO_ 739 200;
BA_ "GenMsgSendType" BO_ 739 0;
BA_ "GenMsgCycleTime" BO_ 835 100;
BA_ "GenMsgSendType" BO_ 835 0;
BA_ "GenMsgCycleTime" BO_ 963 100;
BA_ "GenMsgSendType" BO_ 963 0;
BA_ "GenMsgCycleTime" BO_ 899 100;
BA_ "GenMsgSendType" BO_ 899 0;
BA_ "GenMsgCycleTime" BO_ 1059 100;
BA_ "GenMsgSendType" BO_ 1059 0;
BA_ "GenMsgCycleTime" BO_ 707 100;
BA_ "GenMsgSendType" BO_ 707 0;
BA_ "GenMsgCycleTime" BO_ 969 1000;
BA_ "GenMsgSendType" BO_ 969 0;
BA_ "GenMsgCycleTime" BO_ 607 500;
BA_ "GenMsgSendType" BO_ 607 0;
BA_ "Confidence" SG_ 611 VCRIGHT_logging10HzIndex 1;
BA_ "Confidence" SG_ 611 VCRIGHT_hvacLHBleedTarget 0;
BA_ "Confidence" SG_ 611 VCRIGHT_hvacRHBleedTarget 0;
BA_ "Confidence" SG_ 611 VCRIGHT_hvacLHVaneTarget 0;
BA_ "Confidence" SG_ 611 VCRIGHT_hvacRHVaneTarget 0;
BA_ "Confidence" SG_ 611 VCRIGHT_hvacUpperModeTarget 0;
BA_ "Confidence" SG_ 611 VCRIGHT_hvacLowerModeTarget 0;
BA_ "Confidence" SG_ 611 VCRIGHT_hvacIntakeTarget 0;
BA_ "Confidence" SG_ 611 VCRIGHT_hvacLHBleedPosition 0;
BA_ "Confidence" SG_ 611 VCRIGHT_hvacRHBleedPosition 0;
BA_ "Confidence" SG_ 611 VCRIGHT_hvacLHVanePosition 0;
BA_ "Confidence" SG_ 611 VCRIGHT_hvacRHVanePosition 0;
BA_ "Confidence" SG_ 611 VCRIGHT_hvacUpperModePosition 0;
BA_ "Confidence" SG_ 611 VCRIGHT_hvacLowerModePosition 0;
BA_ "Confidence" SG_ 611 VCRIGHT_hvacIntakePosition 0;
BA_ "Confidence" SG_ 611 VCRIGHT_hvacLHBleedActuatorState 0;
BA_ "Confidence" SG_ 611 VCRIGHT_hvacRHBleedActuatorState 0;
BA_ "Confidence" SG_ 611 VCRIGHT_hvacLHVaneActuatorState 0;
BA_ "Confidence" SG_ 611 VCRIGHT_hvacRHVaneActuatorState 0;
BA_ "Confidence" SG_ 611 VCRIGHT_hvacUpperModeActState 0;
BA_ "Confidence" SG_ 611 VCRIGHT_hvacLowerModeActState 0;
BA_ "Confidence" SG_ 611 VCRIGHT_hvacIntakeActuatorState 0;
BA_ "Confidence" SG_ 611 VCRIGHT_hvacRearActuatorState 0;
BA_ "Confidence" SG_ 611 VCRIGHT_EvapPulldownBiasActive 0;
BA_ "Confidence" SG_ 611 VCRIGHT_tempDatLeftEst 0;
BA_ "GenSigSNA" SG_ 611 VCRIGHT_tempDatLeftEst "255";
BA_ "Confidence" SG_ 611 VCRIGHT_tempDatRightEst 0;
BA_ "GenSigSNA" SG_ 611 VCRIGHT_tempDatRightEst "255";
BA_ "Confidence" SG_ 611 VCRIGHT_tempDuctLeftEst 0;
BA_ "GenSigSNA" SG_ 611 VCRIGHT_tempDuctLeftEst "255";
BA_ "Confidence" SG_ 611 VCRIGHT_tempDuctRightEst 0;
BA_ "GenSigSNA" SG_ 611 VCRIGHT_tempDuctRightEst "255";
BA_ "Confidence" SG_ 611 VCRIGHT_ptcHeaterBadRodDetection 0;
BA_ "SystemSignalLongSymbol" SG_ 611 VCRIGHT_ptcHeaterBadRodDetection "VCRIGHT_ptcHeaterBadRodDetectionState";
BA_ "Confidence" SG_ 611 VCRIGHT_upperModeDrvActuatorStat 0;
BA_ "SystemSignalLongSymbol" SG_ 611 VCRIGHT_upperModeDrvActuatorStat "VCRIGHT_upperModeDrvActuatorState";
BA_ "Confidence" SG_ 611 VCRIGHT_leftVerticalActuato_0001 0;
BA_ "SystemSignalLongSymbol" SG_ 611 VCRIGHT_leftVerticalActuato_0001 "VCRIGHT_leftVerticalActuatorStatus";
BA_ "Confidence" SG_ 611 VCRIGHT_leftLateralActuatorStatu 0;
BA_ "SystemSignalLongSymbol" SG_ 611 VCRIGHT_leftLateralActuatorStatu "VCRIGHT_leftLateralActuatorStatus";
BA_ "Confidence" SG_ 611 VCRIGHT_rightVerticalActuat_0001 0;
BA_ "SystemSignalLongSymbol" SG_ 611 VCRIGHT_rightVerticalActuat_0001 "VCRIGHT_rightVerticalActuatorStatus";
BA_ "Confidence" SG_ 611 VCRIGHT_rightLateralActuato_0001 0;
BA_ "SystemSignalLongSymbol" SG_ 611 VCRIGHT_rightLateralActuato_0001 "VCRIGHT_rightLateralActuatorStatus";
BA_ "Confidence" SG_ 611 VCRIGHT_leftVerticalActuatorStat 0;
BA_ "SystemSignalLongSymbol" SG_ 611 VCRIGHT_leftVerticalActuatorStat "VCRIGHT_leftVerticalActuatorState";
BA_ "Confidence" SG_ 611 VCRIGHT_leftLateralActuatorState 0;
BA_ "Confidence" SG_ 611 VCRIGHT_rightVerticalActuatorSta 0;
BA_ "SystemSignalLongSymbol" SG_ 611 VCRIGHT_rightVerticalActuatorSta "VCRIGHT_rightVerticalActuatorState";
BA_ "Confidence" SG_ 611 VCRIGHT_rightLateralActuatorStat 0;
BA_ "SystemSignalLongSymbol" SG_ 611 VCRIGHT_rightLateralActuatorStat "VCRIGHT_rightLateralActuatorState";
BA_ "Confidence" SG_ 611 VCRIGHT_windshieldRHExteriorSurf 0;
BA_ "GenSigSNA" SG_ 611 VCRIGHT_windshieldRHExteriorSurf "255";
BA_ "SystemSignalLongSymbol" SG_ 611 VCRIGHT_windshieldRHExteriorSurf "VCRIGHT_windshieldRHExteriorSurface";
BA_ "Confidence" SG_ 611 VCRIGHT_leftVerticalActuatorDuty 0;
BA_ "Confidence" SG_ 611 VCRIGHT_leftLateralActuatorDuty 0;
BA_ "Confidence" SG_ 611 VCRIGHT_rightVerticalActuatorDut 0;
BA_ "SystemSignalLongSymbol" SG_ 611 VCRIGHT_rightVerticalActuatorDut "VCRIGHT_rightVerticalActuatorDuty";
BA_ "Confidence" SG_ 611 VCRIGHT_rightLateralActuatorDuty 0;
BA_ "Confidence" SG_ 611 VCRIGHT_frontLeftSeatTempTargetQ 0;
BA_ "SystemSignalLongSymbol" SG_ 611 VCRIGHT_frontLeftSeatTempTargetQ "VCRIGHT_frontLeftSeatTempTargetQuasiSS";
BA_ "Confidence" SG_ 611 VCRIGHT_frontRightSeatTempTarget 0;
BA_ "SystemSignalLongSymbol" SG_ 611 VCRIGHT_frontRightSeatTempTarget "VCRIGHT_frontRightSeatTempTargetQuasiSS";
BA_ "Confidence" SG_ 611 VCRIGHT_hvacRearPosition 0;
BA_ "Confidence" SG_ 611 VCRIGHT_hvacRearTarget 0;
BA_ "Confidence" SG_ 691 VCRIGHT_logging1HzIndex 1;
BA_ "Confidence" SG_ 691 VCRIGHT_glareShieldHeaterState 0;
BA_ "Confidence" SG_ 691 VCRIGHT_tempIncarCabinProbe 0;
BA_ "GenSigSNA" SG_ 691 VCRIGHT_tempIncarCabinProbe "255";
BA_ "Confidence" SG_ 691 VCRIGHT_cabinTempInteriorL2 0;
BA_ "GenSigSNA" SG_ 691 VCRIGHT_cabinTempInteriorL2 "255";
BA_ "Confidence" SG_ 691 VCRIGHT_cabinTempInteriorSunnyL2 0;
BA_ "GenSigSNA" SG_ 691 VCRIGHT_cabinTempInteriorSunnyL2 "255";
BA_ "Confidence" SG_ 691 VCRIGHT_tempIncarCabinMid 0;
BA_ "GenSigSNA" SG_ 691 VCRIGHT_tempIncarCabinMid "250";
BA_ "Confidence" SG_ 691 VCRIGHT_cabinTempInteriorL3 0;
BA_ "GenSigSNA" SG_ 691 VCRIGHT_cabinTempInteriorL3 "255";
BA_ "Confidence" SG_ 691 VCRIGHT_cabinTempInteriorSunnyL3 0;
BA_ "GenSigSNA" SG_ 691 VCRIGHT_cabinTempInteriorSunnyL3 "255";
BA_ "Confidence" SG_ 691 VCRIGHT_tempWetBulb 0;
BA_ "GenSigSNA" SG_ 691 VCRIGHT_tempWetBulb "255";
BA_ "Confidence" SG_ 691 VCRIGHT_isRainingOrSnowing 0;
BA_ "Confidence" SG_ 691 VCRIGHT_cabinTempGlassRoof 0;
BA_ "GenSigSNA" SG_ 691 VCRIGHT_cabinTempGlassRoof "255";
BA_ "Confidence" SG_ 691 VCRIGHT_cabinTempWindshield 0;
BA_ "GenSigSNA" SG_ 691 VCRIGHT_cabinTempWindshield "255";
BA_ "Confidence" SG_ 691 VCRIGHT_cabinTempInterior 0;
BA_ "GenSigSNA" SG_ 691 VCRIGHT_cabinTempInterior "255";
BA_ "Confidence" SG_ 691 VCRIGHT_cabinTempInteriorSunny 0;
BA_ "GenSigSNA" SG_ 691 VCRIGHT_cabinTempInteriorSunny "255";
BA_ "Confidence" SG_ 691 VCRIGHT_cabinTempSideGlassLeft 0;
BA_ "GenSigSNA" SG_ 691 VCRIGHT_cabinTempSideGlassLeft "255";
BA_ "Confidence" SG_ 691 VCRIGHT_cabinTempSideGlassRight 0;
BA_ "GenSigSNA" SG_ 691 VCRIGHT_cabinTempSideGlassRight "255";
BA_ "Confidence" SG_ 691 VCRIGHT_cabinTempBreathLevel 0;
BA_ "GenSigSNA" SG_ 691 VCRIGHT_cabinTempBreathLevel "255";
BA_ "Confidence" SG_ 691 VCRIGHT_pcbaTemperature 0;
BA_ "Confidence" SG_ 691 VCRIGHT_wattsHeaterLeftTotal 0;
BA_ "Confidence" SG_ 691 VCRIGHT_wattsHeaterRightTotal 0;
BA_ "Confidence" SG_ 691 VCRIGHT_qdotLeftFFUnsat 0;
BA_ "Confidence" SG_ 691 VCRIGHT_qdotRightFFUnsat 0;
BA_ "Confidence" SG_ 691 VCRIGHT_nvhLevelDb 0;
BA_ "Confidence" SG_ 691 VCRIGHT_hvacSetTempActualLeft 0;
BA_ "Confidence" SG_ 691 VCRIGHT_hvacSetTempActualRight 0;
BA_ "Confidence" SG_ 691 VCRIGHT_hvacAutoTransitionReason 0;
BA_ "Confidence" SG_ 691 VCRIGHT_hvacMassflowTarget 0;
BA_ "Confidence" SG_ 691 VCRIGHT_hvacQdotLimitedLeft 0;
BA_ "Confidence" SG_ 691 VCRIGHT_hvacQdotLimitedRight 0;
BA_ "Confidence" SG_ 691 VCRIGHT_LHPanelAirflowBlocked 0;
BA_ "Confidence" SG_ 691 VCRIGHT_RHPanelAirflowBlocked 0;
BA_ "Confidence" SG_ 691 VCRIGHT_floorAirflowBlocked 0;
BA_ "Confidence" SG_ 691 VCRIGHT_defrostAirflowBlocked 0;
BA_ "Confidence" SG_ 691 VCRIGHT_hvacFilterLifeDetectActi 0;
BA_ "SystemSignalLongSymbol" SG_ 691 VCRIGHT_hvacFilterLifeDetectActi "VCRIGHT_hvacFilterLifeDetectActive";
BA_ "Confidence" SG_ 691 VCRIGHT_hvacLHBleedOperationMode 0;
BA_ "Confidence" SG_ 691 VCRIGHT_hvacRHBleedOperationMode 0;
BA_ "Confidence" SG_ 691 VCRIGHT_hvacLHVaneOperationMode 0;
BA_ "Confidence" SG_ 691 VCRIGHT_hvacRHVaneOperationMode 0;
BA_ "Confidence" SG_ 691 VCRIGHT_hvacUpperModeOpMode 0;
BA_ "Confidence" SG_ 691 VCRIGHT_hvacLowerModeOpMode 0;
BA_ "Confidence" SG_ 691 VCRIGHT_hvacIntakeOperationMode 0;
BA_ "Confidence" SG_ 691 VCRIGHT_hvacRearOperationMode 0;
BA_ "Confidence" SG_ 691 VCRIGHT_isProbeFeedbackApplied 0;
BA_ "Confidence" SG_ 691 VCRIGHT_feedbackPullDownScalar 0;
BA_ "Confidence" SG_ 691 VCRIGHT_feedForwardPullDownScala 0;
BA_ "SystemSignalLongSymbol" SG_ 691 VCRIGHT_feedForwardPullDownScala "VCRIGHT_feedForwardPullDownScalar";
BA_ "Confidence" SG_ 691 VCRIGHT_convectionTargetLeft 0;
BA_ "GenSigSNA" SG_ 691 VCRIGHT_convectionTargetLeft "511";
BA_ "Confidence" SG_ 691 VCRIGHT_convectionTargetRight 0;
BA_ "GenSigSNA" SG_ 691 VCRIGHT_convectionTargetRight "511";
BA_ "Confidence" SG_ 691 VCRIGHT_convectionDeliveredLeft 0;
BA_ "GenSigSNA" SG_ 691 VCRIGHT_convectionDeliveredLeft "511";
BA_ "Confidence" SG_ 691 VCRIGHT_convectionDeliveredRight 0;
BA_ "GenSigSNA" SG_ 691 VCRIGHT_convectionDeliveredRight "511";
BA_ "Confidence" SG_ 691 VCRIGHT_solarLoadRightOccupant 0;
BA_ "GenSigSNA" SG_ 691 VCRIGHT_solarLoadRightOccupant "127";
BA_ "Confidence" SG_ 691 VCRIGHT_solarLoadLeftOccupant 0;
BA_ "GenSigSNA" SG_ 691 VCRIGHT_solarLoadLeftOccupant "127";
BA_ "Confidence" SG_ 691 VCRIGHT_ptcShutOutletMitigationA 0;
BA_ "SystemSignalLongSymbol" SG_ 691 VCRIGHT_ptcShutOutletMitigationA "VCRIGHT_ptcShutOutletMitigationActive";
BA_ "Confidence" SG_ 691 VCRIGHT_solarLoadFromThsTemp 0;
BA_ "GenSigSNA" SG_ 691 VCRIGHT_solarLoadFromThsTemp "255";
BA_ "Confidence" SG_ 691 VCRIGHT_hvacFoggingRiskLeve_0003 0;
BA_ "SystemSignalLongSymbol" SG_ 691 VCRIGHT_hvacFoggingRiskLeve_0003 "VCRIGHT_hvacFoggingRiskLevelFeedforwardConservativeEst";
BA_ "Confidence" SG_ 691 VCRIGHT_hvacFoggingRiskLeve_0004 0;
BA_ "SystemSignalLongSymbol" SG_ 691 VCRIGHT_hvacFoggingRiskLeve_0004 "VCRIGHT_hvacFoggingRiskLevelFeedforwardConservativeTar";
BA_ "Confidence" SG_ 691 VCRIGHT_hvacFoggingRiskLeve_0001 0;
BA_ "SystemSignalLongSymbol" SG_ 691 VCRIGHT_hvacFoggingRiskLeve_0001 "VCRIGHT_hvacFoggingRiskLevelConservativeTar";
BA_ "Confidence" SG_ 691 VCRIGHT_ptcHeaterTempDuctHigh 0;
BA_ "Confidence" SG_ 691 VCRIGHT_ptcHeaterTempDuctFault 0;
BA_ "Confidence" SG_ 691 VCRIGHT_ptcHeaterNoAirflow 0;
BA_ "Confidence" SG_ 691 VCRIGHT_ptcHeaterHvacActNotReady 0;
BA_ "Confidence" SG_ 691 VCRIGHT_ptcHeaterNoUiRequest 0;
BA_ "Confidence" SG_ 691 VCRIGHT_ptcHeaterNoHighVoltage 0;
BA_ "Confidence" SG_ 691 VCRIGHT_ptcHeaterLAirPathBlocked 0;
BA_ "Confidence" SG_ 691 VCRIGHT_ptcHeaterRAirPathBlocked 0;
BA_ "Confidence" SG_ 691 VCRIGHT_ptcHeaterReqAirpathBlock 0;
BA_ "SystemSignalLongSymbol" SG_ 691 VCRIGHT_ptcHeaterReqAirpathBlock "VCRIGHT_ptcHeaterReqAirpathBlocked";
BA_ "Confidence" SG_ 691 VCRIGHT_hvacQdotFeedforward 0;
BA_ "Confidence" SG_ 691 VCRIGHT_cabinTempWshldDefog 0;
BA_ "GenSigSNA" SG_ 691 VCRIGHT_cabinTempWshldDefog "255";
BA_ "Confidence" SG_ 691 VCRIGHT_cabinTempWshldDefogTop 0;
BA_ "GenSigSNA" SG_ 691 VCRIGHT_cabinTempWshldDefogTop "255";
BA_ "Confidence" SG_ 691 VCRIGHT_hvacLHBleedVoltage 0;
BA_ "Confidence" SG_ 691 VCRIGHT_hvacRHBleedVoltage 0;
BA_ "Confidence" SG_ 691 VCRIGHT_hvacLHVaneVoltage 0;
BA_ "Confidence" SG_ 691 VCRIGHT_hvacRHVaneVoltage 0;
BA_ "Confidence" SG_ 691 VCRIGHT_hvacUpperModeVoltage 0;
BA_ "Confidence" SG_ 691 VCRIGHT_hvacLowerModeVoltage 0;
BA_ "Confidence" SG_ 691 VCRIGHT_hvacIntakeVoltage 0;
BA_ "Confidence" SG_ 691 VCRIGHT_cabinTempBreathLevelFHea 0;
BA_ "GenSigSNA" SG_ 691 VCRIGHT_cabinTempBreathLevelFHea "255";
BA_ "SystemSignalLongSymbol" SG_ 691 VCRIGHT_cabinTempBreathLevelFHea "VCRIGHT_cabinTempBreathLevelFHeating";
BA_ "Confidence" SG_ 691 VCRIGHT_cabinTempBreathLevelFCoo 0;
BA_ "GenSigSNA" SG_ 691 VCRIGHT_cabinTempBreathLevelFCoo "255";
BA_ "SystemSignalLongSymbol" SG_ 691 VCRIGHT_cabinTempBreathLevelFCoo "VCRIGHT_cabinTempBreathLevelFCooling";
BA_ "Confidence" SG_ 691 VCRIGHT_hvacTorqueMassflowLinear 0;
BA_ "SystemSignalLongSymbol" SG_ 691 VCRIGHT_hvacTorqueMassflowLinear "VCRIGHT_hvacTorqueMassflowLinearFit";
BA_ "Confidence" SG_ 691 VCRIGHT_hvacTorqueMassflowEstima 0;
BA_ "SystemSignalLongSymbol" SG_ 691 VCRIGHT_hvacTorqueMassflowEstima "VCRIGHT_hvacTorqueMassflowEstimateStatus";
BA_ "Confidence" SG_ 691 VCRIGHT_hvacFoggingRiskLevelCons 0;
BA_ "SystemSignalLongSymbol" SG_ 691 VCRIGHT_hvacFoggingRiskLevelCons "VCRIGHT_hvacFoggingRiskLevelConservativeEst";
BA_ "Confidence" SG_ 691 VCRIGHT_hvacWindshieldRHConserva 0;
BA_ "SystemSignalLongSymbol" SG_ 691 VCRIGHT_hvacWindshieldRHConserva "VCRIGHT_hvacWindshieldRHConservativeEst";
BA_ "Confidence" SG_ 691 VCRIGHT_hvacFoggingRiskLevelFeed 0;
BA_ "SystemSignalLongSymbol" SG_ 691 VCRIGHT_hvacFoggingRiskLevelFeed "VCRIGHT_hvacFoggingRiskLevelFeedback";
BA_ "Confidence" SG_ 691 VCRIGHT_hvacFoggingRiskLevelInte 0;
BA_ "SystemSignalLongSymbol" SG_ 691 VCRIGHT_hvacFoggingRiskLevelInte "VCRIGHT_hvacFoggingRiskLevelIntegral";
BA_ "Confidence" SG_ 691 VCRIGHT_hvacFoggingRiskLeve_0002 0;
BA_ "SystemSignalLongSymbol" SG_ 691 VCRIGHT_hvacFoggingRiskLeve_0002 "VCRIGHT_hvacFoggingRiskLevelFeedforward";
BA_ "Confidence" SG_ 691 VCRIGHT_hvacCabOvrheatProtActive 0;
BA_ "Confidence" SG_ 691 VCRIGHT_hvacCabinPurgeAllowed 0;
BA_ "Confidence" SG_ 691 VCRIGHT_hvacCabOvrheatProtAllowe 0;
BA_ "SystemSignalLongSymbol" SG_ 691 VCRIGHT_hvacCabOvrheatProtAllowe "VCRIGHT_hvacCabOvrheatProtAllowed";
BA_ "Confidence" SG_ 691 VCRIGHT_AP_humidityModelBasedCab 0;
BA_ "GenSigSNA" SG_ 691 VCRIGHT_AP_humidityModelBasedCab "1023";
BA_ "SystemSignalLongSymbol" SG_ 691 VCRIGHT_AP_humidityModelBasedCab "VCRIGHT_AP_humidityModelBasedCabinWaterMass";
BA_ "Confidence" SG_ 691 VCRIGHT_cabinTempFanCurrent 0;
BA_ "Confidence" SG_ 691 VCRIGHT_cabinTempFanOutput 0;
BA_ "Confidence" SG_ 691 VCRIGHT_cloudinessEstimatedPct 0;
BA_ "Confidence" SG_ 691 VCRIGHT_solarLoadOnVehFiltered 0;
BA_ "GenSigSNA" SG_ 691 VCRIGHT_solarLoadOnVehFiltered "255";
BA_ "Confidence" SG_ 691 VCRIGHT_cabinTempProbeEstimate 0;
BA_ "GenSigSNA" SG_ 691 VCRIGHT_cabinTempProbeEstimate "255";
BA_ "Confidence" SG_ 691 VCRIGHT_cabinTempThs 0;
BA_ "GenSigSNA" SG_ 691 VCRIGHT_cabinTempThs "255";
BA_ "Confidence" SG_ 691 VCRIGHT_cabinTempThsBracket 0;
BA_ "GenSigSNA" SG_ 691 VCRIGHT_cabinTempThsBracket "255";
BA_ "Confidence" SG_ 691 VCRIGHT_leftHeatOvertempProtect 0;
BA_ "Confidence" SG_ 691 VCRIGHT_rightHeatOvertempProtect 0;
BA_ "Confidence" SG_ 691 VCRIGHT_CO2ppm 0;
BA_ "GenSigSNA" SG_ 691 VCRIGHT_CO2ppm "1023";
BA_ "Confidence" SG_ 691 VCRIGHT_timeLeftToCabinModelInit 0;
BA_ "Confidence" SG_ 691 VCRIGHT_hvacEstimateWindshieldRH 0;
BA_ "Confidence" SG_ 691 VCRIGHT_hvacFoggingRiskLevel 0;
BA_ "Confidence" SG_ 691 VCRIGHT_hvacCabinHumidityLevel 0;
BA_ "Confidence" SG_ 691 VCRIGHT_hvacFlashFoggingDetected 0;
BA_ "Confidence" SG_ 691 VCRIGHT_solarSensitivityInfr 0;
BA_ "Confidence" SG_ 691 VCRIGHT_solarSensitivityInfrCorr 0;
BA_ "Confidence" SG_ 691 VCRIGHT_lumbarCurrent 0;
BA_ "Confidence" SG_ 691 VCRIGHT_ocsCurrent 0;
BA_ "Confidence" SG_ 691 VCRIGHT_rcmCurrent 0;
BA_ "Confidence" SG_ 691 VCRIGHT_radioTunerCurrent 0;
BA_ "Confidence" SG_ 691 VCRIGHT_rearOilPumpCurrent 0;
BA_ "Confidence" SG_ 691 VCRIGHT_rearDefrostCurrent 0;
BA_ "Confidence" SG_ 691 VCRIGHT_tailLightCurrent 0;
BA_ "Confidence" SG_ 691 VCRIGHT_turnTailStopLightCurrent 0;
BA_ "Confidence" SG_ 691 VCRIGHT_reverseFogLightsCurrent 0;
BA_ "GenSigSNA" SG_ 691 VCRIGHT_reverseFogLightsCurrent "15";
BA_ "Confidence" SG_ 691 VCRIGHT_stopReverseTurnLightCurr 0;
BA_ "SystemSignalLongSymbol" SG_ 691 VCRIGHT_stopReverseTurnLightCurr "VCRIGHT_stopReverseTurnLightCurrent";
BA_ "Confidence" SG_ 691 VCRIGHT_sideMirrorCurrent 0;
BA_ "Confidence" SG_ 691 VCRIGHT_sideMirrorHeaterCurrent 0;
BA_ "GenSigSNA" SG_ 691 VCRIGHT_sideMirrorHeaterCurrent "31";
BA_ "Confidence" SG_ 691 VCRIGHT_frontSeatHeatCushionPwr 0;
BA_ "Confidence" SG_ 691 VCRIGHT_trunkInteriorLEDCurrent 0;
BA_ "GenSigSNA" SG_ 691 VCRIGHT_trunkInteriorLEDCurrent "15";
BA_ "Confidence" SG_ 691 VCRIGHT_mapPocketLEDsCurrent 0;
BA_ "GenSigSNA" SG_ 691 VCRIGHT_mapPocketLEDsCurrent "15";
BA_ "Confidence" SG_ 691 VCRIGHT_miscEFuseCurrent 0;
BA_ "GenSigSNA" SG_ 691 VCRIGHT_miscEFuseCurrent "31";
BA_ "Confidence" SG_ 691 VCRIGHT_interiorHandleLEDCurrent 0;
BA_ "Confidence" SG_ 691 VCRIGHT_miscInteriorLightsCurren 0;
BA_ "GenSigSNA" SG_ 691 VCRIGHT_miscInteriorLightsCurren "7";
BA_ "SystemSignalLongSymbol" SG_ 691 VCRIGHT_miscInteriorLightsCurren "VCRIGHT_miscInteriorLightsCurrent";
BA_ "Confidence" SG_ 691 VCRIGHT_frontPuddleLEDCurrent 0;
BA_ "GenSigSNA" SG_ 691 VCRIGHT_frontPuddleLEDCurrent "7";
BA_ "Confidence" SG_ 691 VCRIGHT_rearPuddleLEDCurrent 0;
BA_ "GenSigSNA" SG_ 691 VCRIGHT_rearPuddleLEDCurrent "7";
BA_ "Confidence" SG_ 691 VCRIGHT_liftgateShutfaceLEDCurre 0;
BA_ "GenSigSNA" SG_ 691 VCRIGHT_liftgateShutfaceLEDCurre "7";
BA_ "SystemSignalLongSymbol" SG_ 691 VCRIGHT_liftgateShutfaceLEDCurre "VCRIGHT_liftgateShutfaceLEDCurrent";
BA_ "Confidence" SG_ 691 VCRIGHT_3rSeatTOSCurrent 0;
BA_ "GenSigSNA" SG_ 691 VCRIGHT_3rSeatTOSCurrent "15";
BA_ "Confidence" SG_ 691 VCRIGHT_vbatFusedCurrent 0;
BA_ "GenSigSNA" SG_ 691 VCRIGHT_vbatFusedCurrent "15";
BA_ "Confidence" SG_ 691 VCRIGHT_cabinTempGlassGridHeater 0;
BA_ "GenSigSNA" SG_ 691 VCRIGHT_cabinTempGlassGridHeater "255";
BA_ "Confidence" SG_ 691 VCRIGHT_hvacAirflowReasonRight 0;
BA_ "Confidence" SG_ 691 VCRIGHT_hvacAirflowReasonLeft 0;
BA_ "Confidence" SG_ 691 VCRIGHT_hvacMassflowTargetLeft 0;
BA_ "Confidence" SG_ 691 VCRIGHT_hvacMassflowTargetRight 0;
BA_ "Confidence" SG_ 691 VCRIGHT_solarLoadLeftOccupantFil 0;
BA_ "GenSigSNA" SG_ 691 VCRIGHT_solarLoadLeftOccupantFil "127";
BA_ "SystemSignalLongSymbol" SG_ 691 VCRIGHT_solarLoadLeftOccupantFil "VCRIGHT_solarLoadLeftOccupantFilt";
BA_ "Confidence" SG_ 691 VCRIGHT_solarLoadRightOccupantFi 0;
BA_ "GenSigSNA" SG_ 691 VCRIGHT_solarLoadRightOccupantFi "127";
BA_ "SystemSignalLongSymbol" SG_ 691 VCRIGHT_solarLoadRightOccupantFi "VCRIGHT_solarLoadRightOccupantFilt";
BA_ "Confidence" SG_ 691 VCRIGHT_windshieldRHCapped 0;
BA_ "Confidence" SG_ 691 VCRIGHT_feedbackWarmUpScalar 0;
BA_ "Confidence" SG_ 691 VCRIGHT_maxMassflowScalarWarmUp 0;
BA_ "Confidence" SG_ 691 VCRIGHT_feedforwardWarmUpScalar 0;
BA_ "Confidence" SG_ 691 VCRIGHT_frontSeatHeatBackrestPwr 0;
BA_ "Confidence" SG_ 691 VCRIGHT_maxMassflowScalar 0;
BA_ "Confidence" SG_ 691 VCRIGHT_massflowTargetAutoInManu 0;
BA_ "SystemSignalLongSymbol" SG_ 691 VCRIGHT_massflowTargetAutoInManu "VCRIGHT_massflowTargetAutoInManualMode";
BA_ "Confidence" SG_ 691 VCRIGHT_airflowReasonAutoInManua 0;
BA_ "SystemSignalLongSymbol" SG_ 691 VCRIGHT_airflowReasonAutoInManua "VCRIGHT_airflowReasonAutoInManualMode";
BA_ "Confidence" SG_ 691 VCRIGHT_airflowReasonAutoIn_0001 0;
BA_ "SystemSignalLongSymbol" SG_ 691 VCRIGHT_airflowReasonAutoIn_0001 "VCRIGHT_airflowReasonAutoInManualModeLeft";
BA_ "Confidence" SG_ 691 VCRIGHT_airflowReasonAutoIn_0002 0;
BA_ "SystemSignalLongSymbol" SG_ 691 VCRIGHT_airflowReasonAutoIn_0002 "VCRIGHT_airflowReasonAutoInManualModeRight";
BA_ "Confidence" SG_ 691 VCRIGHT_hvacTorqueMassflowQuadra 0;
BA_ "SystemSignalLongSymbol" SG_ 691 VCRIGHT_hvacTorqueMassflowQuadra "VCRIGHT_hvacTorqueMassflowQuadraticFit";
BA_ "Confidence" SG_ 691 VCRIGHT_vocSweatMassSeat 0;
BA_ "GenSigSNA" SG_ 691 VCRIGHT_vocSweatMassSeat "255";
BA_ "Confidence" SG_ 691 VCRIGHT_vocSweatConcentrationAir 0;
BA_ "GenSigSNA" SG_ 691 VCRIGHT_vocSweatConcentrationAir "255";
BA_ "Confidence" SG_ 691 VCRIGHT_hvacBiLevelWhsldRhEst 0;
BA_ "Confidence" SG_ 691 VCRIGHT_steeringWheelSurfaceTemp 0;
BA_ "GenSigSNA" SG_ 691 VCRIGHT_steeringWheelSurfaceTemp "1023";
BA_ "SystemSignalLongSymbol" SG_ 691 VCRIGHT_steeringWheelSurfaceTemp "VCRIGHT_steeringWheelSurfaceTempEst";
BA_ "Confidence" SG_ 691 VCRIGHT_steeringWheelSurfac_0001 0;
BA_ "GenSigSNA" SG_ 691 VCRIGHT_steeringWheelSurfac_0001 "1023";
BA_ "SystemSignalLongSymbol" SG_ 691 VCRIGHT_steeringWheelSurfac_0001 "VCRIGHT_steeringWheelSurfaceTempTgt";
BA_ "Confidence" SG_ 691 VCRIGHT_timeToComfortHeating 0;
BA_ "Confidence" SG_ 691 VCRIGHT_timeToComfortCooling 0;
BA_ "Confidence" SG_ 691 VCRIGHT_cabinWaterMassRaw 0;
BA_ "GenSigSNA" SG_ 691 VCRIGHT_cabinWaterMassRaw "255";
BA_ "Confidence" SG_ 691 VCRIGHT_massflowSingleZoneSplit 0;
BA_ "Confidence" SG_ 691 VCRIGHT_VOCPurgeState 0;
BA_ "Confidence" SG_ 691 VCRIGHT_cameraFoggingMonitorStat 0;
BA_ "SystemSignalLongSymbol" SG_ 691 VCRIGHT_cameraFoggingMonitorStat "VCRIGHT_cameraFoggingMonitorState";
BA_ "Confidence" SG_ 691 VCRIGHT_windWeatherSource 0;
BA_ "Confidence" SG_ 691 VCRIGHT_humidityRatioWeatherSour 0;
BA_ "SystemSignalLongSymbol" SG_ 691 VCRIGHT_humidityRatioWeatherSour "VCRIGHT_humidityRatioWeatherSource";
BA_ "Confidence" SG_ 691 VCRIGHT_cabinOverheatProtectNotR 0;
BA_ "SystemSignalLongSymbol" SG_ 691 VCRIGHT_cabinOverheatProtectNotR "VCRIGHT_cabinOverheatProtectNotRunningReasonRaw";
BA_ "Confidence" SG_ 691 VCRIGHT_hvacIntakeReason 0;
BA_ "Confidence" SG_ 691 VCRIGHT_hvacCabinPurgeActive 0;
BA_ "Confidence" SG_ 691 VCRIGHT_solarAzimuthCarRef 0;
BA_ "GenSigSNA" SG_ 691 VCRIGHT_solarAzimuthCarRef "1025";
BA_ "Confidence" SG_ 691 VCRIGHT_massflowPulldownBias 0;
BA_ "Confidence" SG_ 691 VCRIGHT_evapPulldownBias 0;
BA_ "Confidence" SG_ 691 VCRIGHT_modeledMassflowFresh 0;
BA_ "Confidence" SG_ 691 VCRIGHT_modeledMassflowRecirc 0;
BA_ "Confidence" SG_ 691 VCRIGHT_hvacLimpModeStatus 0;
BA_ "Confidence" SG_ 691 VCRIGHT_hvacEstimatedCameraWinds 0;
BA_ "GenSigSNA" SG_ 691 VCRIGHT_hvacEstimatedCameraWinds "255";
BA_ "SystemSignalLongSymbol" SG_ 691 VCRIGHT_hvacEstimatedCameraWinds "VCRIGHT_hvacEstimatedCameraWindshieldRH";
BA_ "Confidence" SG_ 691 VCRIGHT_hvacRearVoltage 0;
BA_ "Confidence" SG_ 691 VCRIGHT_cabinTempRoofL2 0;
BA_ "GenSigSNA" SG_ 691 VCRIGHT_cabinTempRoofL2 "255";
BA_ "Confidence" SG_ 691 VCRIGHT_cabinTempRoofL3 0;
BA_ "GenSigSNA" SG_ 691 VCRIGHT_cabinTempRoofL3 "255";
BA_ "Confidence" SG_ 691 VCRIGHT_odorRoutineState 0;
BA_ "GenSigSNA" SG_ 691 VCRIGHT_odorRoutineState "7";
BA_ "Confidence" SG_ 691 VCRIGHT_rgbLedFrontCurrent 0;
BA_ "Confidence" SG_ 691 VCRIGHT_rgbLedRearCurrent 0;
BA_ "Confidence" SG_ 691 VCRIGHT_rgbLedFrontOutput 0;
BA_ "Confidence" SG_ 691 VCRIGHT_rgbLedRearOutput 0;
BA_ "Confidence" SG_ 691 VCRIGHT_cameraDefogState 0;
BA_ "Confidence" SG_ 1859 VCRIGHT_systemRecallStatus 0;
BA_ "GenSigSNA" SG_ 1859 VCRIGHT_systemRecallStatus "0";
BA_ "Confidence" SG_ 1859 VCRIGHT_seatRecallStatus 0;
BA_ "GenSigSNA" SG_ 1859 VCRIGHT_seatRecallStatus "0";
BA_ "Confidence" SG_ 1859 VCRIGHT_mirrorRecallStatus 0;
BA_ "GenSigSNA" SG_ 1859 VCRIGHT_mirrorRecallStatus "0";
BA_ "Confidence" SG_ 1251 VCRIGHT_seatStatusIndex 1;
BA_ "Confidence" SG_ 1251 VC_AH_1RowRightSeatMovementHealt 0;
BA_ "SystemSignalLongSymbol" SG_ 1251 VC_AH_1RowRightSeatMovementHealt "VC_AH_1RowRightSeatMovementHealth";
BA_ "Confidence" SG_ 1251 VCRIGHT_frontSeatTrackPos 0;
BA_ "Confidence" SG_ 1251 VCRIGHT_frontSeatTrackCurrent 0;
BA_ "Confidence" SG_ 1251 VCRIGHT_frontSeatTrackDuty 0;
BA_ "Confidence" SG_ 1251 VCRIGHT_frontSeatTrackState 0;
BA_ "Confidence" SG_ 1251 VCRIGHT_frontSeatTrackCalibrated 0;
BA_ "Confidence" SG_ 1251 VCRIGHT_frontSeatTrackLog 0;
BA_ "Confidence" SG_ 1251 VCRIGHT_frontSeatTrackBridgeSt 0;
BA_ "Confidence" SG_ 1251 VCRIGHT_frontSeatTrackPercentage 0;
BA_ "Confidence" SG_ 1251 VCRIGHT_frontSeatBackPos 0;
BA_ "Confidence" SG_ 1251 VCRIGHT_frontSeatBackCurrent 0;
BA_ "Confidence" SG_ 1251 VCRIGHT_frontSeatBackDuty 0;
BA_ "Confidence" SG_ 1251 VCRIGHT_frontSeatBackState 0;
BA_ "Confidence" SG_ 1251 VCRIGHT_frontSeatBackCalibrated 0;
BA_ "Confidence" SG_ 1251 VCRIGHT_frontSeatBackLog 0;
BA_ "Confidence" SG_ 1251 VCRIGHT_frontSeatBackBridgeSt 0;
BA_ "Confidence" SG_ 1251 VCRIGHT_frontSeatBackPercentage 0;
BA_ "Confidence" SG_ 1251 VCRIGHT_frontSeatLiftPos 0;
BA_ "Confidence" SG_ 1251 VCRIGHT_frontSeatLiftCurrent 0;
BA_ "Confidence" SG_ 1251 VCRIGHT_frontSeatLiftDuty 0;
BA_ "Confidence" SG_ 1251 VCRIGHT_frontSeatLiftState 0;
BA_ "Confidence" SG_ 1251 VCRIGHT_frontSeatLiftCalibrated 0;
BA_ "Confidence" SG_ 1251 VCRIGHT_frontSeatLiftLog 0;
BA_ "Confidence" SG_ 1251 VCRIGHT_frontSeatLiftBridgeSt 0;
BA_ "Confidence" SG_ 1251 VCRIGHT_frontSeatLiftPercentage 0;
BA_ "Confidence" SG_ 1251 VCRIGHT_frontSeatTiltPos 0;
BA_ "Confidence" SG_ 1251 VCRIGHT_frontSeatTiltCurrent 0;
BA_ "Confidence" SG_ 1251 VCRIGHT_frontSeatTiltDuty 0;
BA_ "Confidence" SG_ 1251 VCRIGHT_frontSeatTiltState 0;
BA_ "Confidence" SG_ 1251 VCRIGHT_frontSeatTiltCalibrated 0;
BA_ "Confidence" SG_ 1251 VCRIGHT_frontSeatTiltLog 0;
BA_ "Confidence" SG_ 1251 VCRIGHT_frontSeatTiltBridgeSt 0;
BA_ "Confidence" SG_ 1251 VCRIGHT_frontSeatTiltPercentage 0;
BA_ "Confidence" SG_ 1251 VCRIGHT_lumbarAState 0;
BA_ "Confidence" SG_ 1251 VCRIGHT_lumbarBState 0;
BA_ "Confidence" SG_ 1251 VCRIGHT_lumbarAPressureHpa 0;
BA_ "Confidence" SG_ 1251 VCRIGHT_lumbarAPressureHpaFilt 0;
BA_ "Confidence" SG_ 1251 VCRIGHT_lumbarBPressureHpa 0;
BA_ "Confidence" SG_ 1251 VCRIGHT_lumbarBPressureHpaFilt 0;
BA_ "Confidence" SG_ 1251 VCRIGHT_lumbarActiveTooLongErr 0;
BA_ "Confidence" SG_ 1251 VCRIGHT_lumbarMaxPErr 0;
BA_ "Confidence" SG_ 1251 VCRIGHT_lumbarOvercurrentErr 0;
BA_ "Confidence" SG_ 1251 VCRIGHT_lumbarMaxOperatingPErr 0;
BA_ "Confidence" SG_ 1251 VCRIGHT_lumbarMinPErr 0;
BA_ "Confidence" SG_ 1251 VCRIGHT_lumbarGeneralErr 0;
BA_ "Confidence" SG_ 1251 VCRIGHT_lumbarDevMaxPumpPressA 0;
BA_ "Confidence" SG_ 1251 VCRIGHT_lumbarDevMaxPumpPressB 0;
BA_ "Confidence" SG_ 1251 VCRIGHT_frontSeatTrackPosReal 0;
BA_ "Confidence" SG_ 1251 VCRIGHT_frontSeatBackPosReal 0;
BA_ "Confidence" SG_ 1251 VCRIGHT_frontSeatLiftPosReal 0;
BA_ "Confidence" SG_ 1251 VCRIGHT_frontSeatTiltPosReal 0;
BA_ "Confidence" SG_ 1251 VCRIGHT_frontSeatThighSuppo_0001 0;
BA_ "SystemSignalLongSymbol" SG_ 1251 VCRIGHT_frontSeatThighSuppo_0001 "VCRIGHT_frontSeatThighSupportPosReal";
BA_ "Confidence" SG_ 1251 VCRIGHT_frontSeatTrackPosOffset 0;
BA_ "Confidence" SG_ 1251 VCRIGHT_frontSeatBackPosOffset 0;
BA_ "Confidence" SG_ 1251 VCRIGHT_frontSeatLiftPosOffset 0;
BA_ "Confidence" SG_ 1251 VCRIGHT_frontSeatTiltPosOffset 0;
BA_ "Confidence" SG_ 1251 VCRIGHT_frontSeatThighSupportPos 0;
BA_ "SystemSignalLongSymbol" SG_ 1251 VCRIGHT_frontSeatThighSupportPos "VCRIGHT_frontSeatThighSupportPosOffset";
BA_ "Confidence" SG_ 1251 VCRIGHT_lumbarAPressurePercentag 0;
BA_ "SystemSignalLongSymbol" SG_ 1251 VCRIGHT_lumbarAPressurePercentag "VCRIGHT_lumbarAPressurePercentage";
BA_ "Confidence" SG_ 1251 VCRIGHT_lumbarBPressurePercentag 0;
BA_ "SystemSignalLongSymbol" SG_ 1251 VCRIGHT_lumbarBPressurePercentag "VCRIGHT_lumbarBPressurePercentage";
BA_ "Confidence" SG_ 739 VCRIGHT_seatStatus2Index 1;
BA_ "Confidence" SG_ 739 VCRIGHT_frontSeatHeatCurrent 0;
BA_ "GenSigSNA" SG_ 739 VCRIGHT_frontSeatHeatCurrent "12";
BA_ "Confidence" SG_ 739 VCRIGHT_frontSeatHeatDuty 0;
BA_ "Confidence" SG_ 739 VCRIGHT_frontSeatHeatTmp 0;
BA_ "Confidence" SG_ 739 VCRIGHT_frontSeatHeatTmpTarget 0;
BA_ "Confidence" SG_ 739 VCRIGHT_frontSeatHeatInhibited 0;
BA_ "Confidence" SG_ 739 VCRIGHT_frontSeatHeatPowered 0;
BA_ "Confidence" SG_ 739 VC_AH_1RowRightSeatHeatVentHealt 0;
BA_ "SystemSignalLongSymbol" SG_ 739 VC_AH_1RowRightSeatHeatVentHealt "VC_AH_1RowRightSeatHeatVentHealth";
BA_ "Confidence" SG_ 739 VCRIGHT_rearLSeatHeatCurrent 0;
BA_ "Confidence" SG_ 739 VCRIGHT_rearLSeatHeatDuty 0;
BA_ "Confidence" SG_ 739 VCRIGHT_rearLSeatHeatTmp 0;
BA_ "Confidence" SG_ 739 VCRIGHT_rearLSeatHeatTmpTarget 0;
BA_ "Confidence" SG_ 739 VCRIGHT_rearLSeatHeatInhibited 0;
BA_ "Confidence" SG_ 739 VCRIGHT_rearLSeatHeatPowered 0;
BA_ "Confidence" SG_ 739 VCRIGHT_rearCSeatHeatCurrent 0;
BA_ "Confidence" SG_ 739 VCRIGHT_rearCSeatHeatDuty 0;
BA_ "Confidence" SG_ 739 VCRIGHT_rearCSeatHeatTmp 0;
BA_ "Confidence" SG_ 739 VCRIGHT_rearCSeatHeatTmpTarget 0;
BA_ "Confidence" SG_ 739 VCRIGHT_rearCSeatHeatInhibited 0;
BA_ "Confidence" SG_ 739 VCRIGHT_rearCSeatHeatPowered 0;
BA_ "Confidence" SG_ 739 VCRIGHT_rearRSeatHeatCurrent 0;
BA_ "Confidence" SG_ 739 VCRIGHT_rearRSeatHeatDuty 0;
BA_ "Confidence" SG_ 739 VCRIGHT_rearRSeatHeatTmp 0;
BA_ "Confidence" SG_ 739 VCRIGHT_rearRSeatHeatTmpTarget 0;
BA_ "Confidence" SG_ 739 VCRIGHT_rearRSeatHeatInhibited 0;
BA_ "Confidence" SG_ 739 VCRIGHT_rearRSeatHeatPowered 0;
BA_ "Confidence" SG_ 739 VCRIGHT_2RowSeatReclineState 0;
BA_ "GenSigSNA" SG_ 739 VCRIGHT_2RowSeatReclineState "15";
BA_ "Confidence" SG_ 739 VCRIGHT_2RowSeatReclineDuty 0;
BA_ "Confidence" SG_ 739 VCRIGHT_2RowSeatReclineCurrent 0;
BA_ "Confidence" SG_ 739 VCRIGHT_2RowSeatReclineCalibrate 0;
BA_ "SystemSignalLongSymbol" SG_ 739 VCRIGHT_2RowSeatReclineCalibrate "VCRIGHT_2RowSeatReclineCalibrated";
BA_ "Confidence" SG_ 739 VCRIGHT_2RowSeatReclinePositionR 0;
BA_ "SystemSignalLongSymbol" SG_ 739 VCRIGHT_2RowSeatReclinePositionR "VCRIGHT_2RowSeatReclinePositionRaw";
BA_ "Confidence" SG_ 739 VCRIGHT_2RowSeatReclineAngle 0;
BA_ "Confidence" SG_ 739 VCRIGHT_2RowSeatReclineAbsPosSwi 0;
BA_ "GenSigSNA" SG_ 739 VCRIGHT_2RowSeatReclineAbsPosSwi "0";
BA_ "SystemSignalLongSymbol" SG_ 739 VCRIGHT_2RowSeatReclineAbsPosSwi "VCRIGHT_2RowSeatReclineAbsPosSwitchState";
BA_ "Confidence" SG_ 739 VCRIGHT_2RowSeatReclinePositionS 0;
BA_ "GenSigSNA" SG_ 739 VCRIGHT_2RowSeatReclinePositionS "4";
BA_ "SystemSignalLongSymbol" SG_ 739 VCRIGHT_2RowSeatReclinePositionS "VCRIGHT_2RowSeatReclinePositionState";
BA_ "Confidence" SG_ 739 VCRIGHT_2RowSeatReclineAdjustmen 0;
BA_ "SystemSignalLongSymbol" SG_ 739 VCRIGHT_2RowSeatReclineAdjustmen "VCRIGHT_2RowSeatReclineAdjustmentAllowed";
BA_ "Confidence" SG_ 739 VCRIGHT_2RowSeatReclineFoldAllow 0;
BA_ "SystemSignalLongSymbol" SG_ 739 VCRIGHT_2RowSeatReclineFoldAllow "VCRIGHT_2RowSeatReclineFoldAllowed";
BA_ "Confidence" SG_ 739 VCRIGHT_2RowSeatReclineUnfoldAll 0;
BA_ "SystemSignalLongSymbol" SG_ 739 VCRIGHT_2RowSeatReclineUnfoldAll "VCRIGHT_2RowSeatReclineUnfoldAllowed";
BA_ "Confidence" SG_ 739 VCRIGHT_2RowSeatReclineNextToggl 0;
BA_ "GenSigSNA" SG_ 739 VCRIGHT_2RowSeatReclineNextToggl "2";
BA_ "SystemSignalLongSymbol" SG_ 739 VCRIGHT_2RowSeatReclineNextToggl "VCRIGHT_2RowSeatReclineNextToggleDirection";
BA_ "Confidence" SG_ 739 VCRIGHT_2RowSeatReclineChoreoBlo 0;
BA_ "SystemSignalLongSymbol" SG_ 739 VCRIGHT_2RowSeatReclineChoreoBlo "VCRIGHT_2RowSeatReclineChoreoBlockedByOccupancy";
BA_ "Confidence" SG_ 739 VCRIGHT_2RowSeat1RClashAvoidance 0;
BA_ "SystemSignalLongSymbol" SG_ 739 VCRIGHT_2RowSeat1RClashAvoidance "VCRIGHT_2RowSeat1RClashAvoidanceBlockedReason";
BA_ "Confidence" SG_ 739 VCRIGHT_2RowSeat1RClashAvoi_0001 0;
BA_ "SystemSignalLongSymbol" SG_ 739 VCRIGHT_2RowSeat1RClashAvoi_0001 "VCRIGHT_2RowSeat1RClashAvoidanceState";
BA_ "Confidence" SG_ 739 VCRIGHT_2RowSeatReclineAbsP_0001 0;
BA_ "SystemSignalLongSymbol" SG_ 739 VCRIGHT_2RowSeatReclineAbsP_0001 "VCRIGHT_2RowSeatReclineAbsPosSwitchTransPoint";
BA_ "Confidence" SG_ 739 VC_AH_2RowRightSeatMovementHealt 0;
BA_ "SystemSignalLongSymbol" SG_ 739 VC_AH_2RowRightSeatMovementHealt "VC_AH_2RowRightSeatMovementHealth";
BA_ "Confidence" SG_ 739 VCRIGHT_3RowSeatReclineState 0;
BA_ "GenSigSNA" SG_ 739 VCRIGHT_3RowSeatReclineState "15";
BA_ "Confidence" SG_ 739 VCRIGHT_3RowSeatReclineDuty 0;
BA_ "Confidence" SG_ 739 VCRIGHT_3RowSeatReclineCurrent 0;
BA_ "Confidence" SG_ 739 VCRIGHT_3RowSeatReclineCalibrate 0;
BA_ "SystemSignalLongSymbol" SG_ 739 VCRIGHT_3RowSeatReclineCalibrate "VCRIGHT_3RowSeatReclineCalibrated";
BA_ "Confidence" SG_ 739 VCRIGHT_3RowSeatReclinePositionR 0;
BA_ "SystemSignalLongSymbol" SG_ 739 VCRIGHT_3RowSeatReclinePositionR "VCRIGHT_3RowSeatReclinePositionRaw";
BA_ "Confidence" SG_ 739 VCRIGHT_3RowSeatReclineAngle 0;
BA_ "Confidence" SG_ 739 VCRIGHT_3RowSeatReclineNextToggl 0;
BA_ "GenSigSNA" SG_ 739 VCRIGHT_3RowSeatReclineNextToggl "2";
BA_ "SystemSignalLongSymbol" SG_ 739 VCRIGHT_3RowSeatReclineNextToggl "VCRIGHT_3RowSeatReclineNextToggleDirection";
BA_ "Confidence" SG_ 739 VCRIGHT_3RRightSeatHeatCurrent 0;
BA_ "Confidence" SG_ 739 VCRIGHT_3RRightSeatHeatDuty 0;
BA_ "Confidence" SG_ 739 VCRIGHT_3RRightSeatHeatTmp 0;
BA_ "Confidence" SG_ 739 VCRIGHT_3RRightSeatHeatTmpTarget 0;
BA_ "Confidence" SG_ 739 VCRIGHT_3RRightSeatHeatInhibited 0;
BA_ "Confidence" SG_ 739 VCRIGHT_3RowSeatReclinePositionS 0;
BA_ "GenSigSNA" SG_ 739 VCRIGHT_3RowSeatReclinePositionS "4";
BA_ "SystemSignalLongSymbol" SG_ 739 VCRIGHT_3RowSeatReclinePositionS "VCRIGHT_3RowSeatReclinePositionState";
BA_ "Confidence" SG_ 739 VCRIGHT_3RowSeatReclineAdjustmen 0;
BA_ "SystemSignalLongSymbol" SG_ 739 VCRIGHT_3RowSeatReclineAdjustmen "VCRIGHT_3RowSeatReclineAdjustmentAllowed";
BA_ "Confidence" SG_ 739 VCRIGHT_3RowSeatReclineFoldAllow 0;
BA_ "SystemSignalLongSymbol" SG_ 739 VCRIGHT_3RowSeatReclineFoldAllow "VCRIGHT_3RowSeatReclineFoldAllowed";
BA_ "Confidence" SG_ 739 VCRIGHT_3RowSeatReclineUnfoldAll 0;
BA_ "SystemSignalLongSymbol" SG_ 739 VCRIGHT_3RowSeatReclineUnfoldAll "VCRIGHT_3RowSeatReclineUnfoldAllowed";
BA_ "Confidence" SG_ 739 VCRIGHT_3RowSeatReclineChoreoBlo 0;
BA_ "SystemSignalLongSymbol" SG_ 739 VCRIGHT_3RowSeatReclineChoreoBlo "VCRIGHT_3RowSeatReclineChoreoBlockedByOccupancy";
BA_ "Confidence" SG_ 739 VCRIGHT_3RowSeatReclineAbsPosSwi 0;
BA_ "GenSigSNA" SG_ 739 VCRIGHT_3RowSeatReclineAbsPosSwi "0";
BA_ "SystemSignalLongSymbol" SG_ 739 VCRIGHT_3RowSeatReclineAbsPosSwi "VCRIGHT_3RowSeatReclineAbsPosSwitchState";
BA_ "Confidence" SG_ 835 VCRIGHT_autonomyBehaviorStatus 0;
BA_ "Confidence" SG_ 835 VCRIGHT_LVBatteryTypeDBG 0;
BA_ "Confidence" SG_ 835 VCRIGHT_rearDefrostState 0;
BA_ "GenSigSNA" SG_ 835 VCRIGHT_rearDefrostState "0";
BA_ "Confidence" SG_ 835 VCRIGHT_mirrorHeatState 0;
BA_ "GenSigSNA" SG_ 835 VCRIGHT_mirrorHeatState "0";
BA_ "Confidence" SG_ 835 VCRIGHT_OTAState 0;
BA_ "Confidence" SG_ 835 VCRIGHT_5AVoltage 0;
BA_ "Confidence" SG_ 835 VCRIGHT_vbatProt 0;
BA_ "Confidence" SG_ 835 VCRIGHT_rationalityAggregateCurr 0;
BA_ "SystemSignalLongSymbol" SG_ 835 VCRIGHT_rationalityAggregateCurr "VCRIGHT_rationalityAggregateCurrent";
BA_ "Confidence" SG_ 835 VCRIGHT_eFuseMgmtVoltageMonitor 0;
BA_ "Confidence" SG_ 835 VCRIGHT_isSteeringWheelHeaterReq 0;
BA_ "Confidence" SG_ 835 VCRIGHT_steeringWheelHeaterDCTgt 0;
BA_ "GenSigSNA" SG_ 835 VCRIGHT_steeringWheelHeaterDCTgt "127";
BA_ "Confidence" SG_ 963 VCRIGHT_switchStatusIndex 1;
BA_ "Confidence" SG_ 963 VCRIGHT_frontBuckleSwitch 1;
BA_ "Confidence" SG_ 963 VCRIGHT_rearCenterBuckleSwitch 1;
BA_ "Confidence" SG_ 963 VCRIGHT_rearRightBuckleSwitch 1;
BA_ "Confidence" SG_ 963 VCRIGHT_trunkExtReleasePressedPe 0;
BA_ "SystemSignalLongSymbol" SG_ 963 VCRIGHT_trunkExtReleasePressedPe "VCRIGHT_trunkExtReleasePressedPersist";
BA_ "Confidence" SG_ 963 VCRIGHT_frontSeatTrackBack 0;
BA_ "GenSigSNA" SG_ 963 VCRIGHT_frontSeatTrackBack "0";
BA_ "Confidence" SG_ 963 VCRIGHT_frontSeatTrackForward 0;
BA_ "GenSigSNA" SG_ 963 VCRIGHT_frontSeatTrackForward "0";
BA_ "Confidence" SG_ 963 VCRIGHT_frontSeatTiltDown 0;
BA_ "GenSigSNA" SG_ 963 VCRIGHT_frontSeatTiltDown "0";
BA_ "Confidence" SG_ 963 VCRIGHT_frontSeatTiltUp 0;
BA_ "GenSigSNA" SG_ 963 VCRIGHT_frontSeatTiltUp "0";
BA_ "Confidence" SG_ 963 VCRIGHT_frontSeatLiftDown 0;
BA_ "GenSigSNA" SG_ 963 VCRIGHT_frontSeatLiftDown "0";
BA_ "Confidence" SG_ 963 VCRIGHT_frontSeatLiftUp 0;
BA_ "GenSigSNA" SG_ 963 VCRIGHT_frontSeatLiftUp "0";
BA_ "Confidence" SG_ 963 VCRIGHT_frontSeatBackrestBack 0;
BA_ "GenSigSNA" SG_ 963 VCRIGHT_frontSeatBackrestBack "0";
BA_ "Confidence" SG_ 963 VCRIGHT_frontSeatBackrestForward 0;
BA_ "GenSigSNA" SG_ 963 VCRIGHT_frontSeatBackrestForward "0";
BA_ "Confidence" SG_ 963 VCRIGHT_frontSeatLumbarDown 0;
BA_ "GenSigSNA" SG_ 963 VCRIGHT_frontSeatLumbarDown "0";
BA_ "Confidence" SG_ 963 VCRIGHT_frontSeatLumbarUp 0;
BA_ "GenSigSNA" SG_ 963 VCRIGHT_frontSeatLumbarUp "0";
BA_ "Confidence" SG_ 963 VCRIGHT_frontSeatLumbarIn 0;
BA_ "GenSigSNA" SG_ 963 VCRIGHT_frontSeatLumbarIn "0";
BA_ "Confidence" SG_ 963 VCRIGHT_frontSeatLumbarOut 0;
BA_ "GenSigSNA" SG_ 963 VCRIGHT_frontSeatLumbarOut "0";
BA_ "Confidence" SG_ 963 VCRIGHT_2RowSeatReclineSwitch 0;
BA_ "Confidence" SG_ 963 VCRIGHT_2RowSeatBackrestFoldSwit 0;
BA_ "SystemSignalLongSymbol" SG_ 963 VCRIGHT_2RowSeatBackrestFoldSwit "VCRIGHT_2RowSeatBackrestFoldSwitch";
BA_ "Confidence" SG_ 963 VCRIGHT_frontSeatThighSupportExt 0;
BA_ "GenSigSNA" SG_ 963 VCRIGHT_frontSeatThighSupportExt "0";
BA_ "SystemSignalLongSymbol" SG_ 963 VCRIGHT_frontSeatThighSupportExt "VCRIGHT_frontSeatThighSupportExtendSwitch";
BA_ "Confidence" SG_ 963 VCRIGHT_frontHandlePWM 0;
BA_ "Confidence" SG_ 963 VCRIGHT_hvacHeatingAllowedLeft 0;
BA_ "Confidence" SG_ 963 VCRIGHT_rearHandlePWM 0;
BA_ "Confidence" SG_ 963 VCRIGHT_gloveboxLightCurrent 0;
BA_ "Confidence" SG_ 963 VCRIGHT_frontSeatALR 0;
BA_ "GenSigSNA" SG_ 963 VCRIGHT_frontSeatALR "0";
BA_ "Confidence" SG_ 963 VCRIGHT_frontSeatResistiveOccupa 0;
BA_ "GenSigSNA" SG_ 963 VCRIGHT_frontSeatResistiveOccupa "0";
BA_ "SystemSignalLongSymbol" SG_ 963 VCRIGHT_frontSeatResistiveOccupa "VCRIGHT_frontSeatResistiveOccupancy";
BA_ "Confidence" SG_ 963 VCRIGHT_2RowSeatReclineSwitchpac 0;
BA_ "SystemSignalLongSymbol" SG_ 963 VCRIGHT_2RowSeatReclineSwitchpac "VCRIGHT_2RowSeatReclineSwitchpackState";
BA_ "Confidence" SG_ 963 VCRIGHT_hvacHeatingAllowedRight 0;
BA_ "Confidence" SG_ 963 VCRIGHT_frontSeatThighSupportRet 0;
BA_ "GenSigSNA" SG_ 963 VCRIGHT_frontSeatThighSupportRet "0";
BA_ "SystemSignalLongSymbol" SG_ 963 VCRIGHT_frontSeatThighSupportRet "VCRIGHT_frontSeatThighSupportRetractSwitch";
BA_ "Confidence" SG_ 899 VCRIGHT_thsActive 0;
BA_ "Confidence" SG_ 899 VCRIGHT_thsTemperature 0;
BA_ "GenSigSNA" SG_ 899 VCRIGHT_thsTemperature "255";
BA_ "Confidence" SG_ 899 VCRIGHT_thsState 0;
BA_ "Confidence" SG_ 899 VCRIGHT_thsLINCurrentSchedule 0;
BA_ "Confidence" SG_ 899 VCRIGHT_thsDetected 0;
BA_ "Confidence" SG_ 899 VCRIGHT_thsHumidity 0;
BA_ "GenSigSNA" SG_ 899 VCRIGHT_thsHumidity "127";
BA_ "Confidence" SG_ 899 VCRIGHT_estimatedVehicleSituatio 0;
BA_ "SystemSignalLongSymbol" SG_ 899 VCRIGHT_estimatedVehicleSituatio "VCRIGHT_estimatedVehicleSituation";
BA_ "Confidence" SG_ 899 VCRIGHT_thsSolarLoadInfrared 0;
BA_ "GenSigSNA" SG_ 899 VCRIGHT_thsSolarLoadInfrared "1023";
BA_ "Confidence" SG_ 899 VCRIGHT_thsSolarLoadVisible 0;
BA_ "GenSigSNA" SG_ 899 VCRIGHT_thsSolarLoadVisible "1023";
BA_ "Confidence" SG_ 899 VCRIGHT_estimatedThsSolarLoad 0;
BA_ "GenSigSNA" SG_ 899 VCRIGHT_estimatedThsSolarLoad "1023";
BA_ "Confidence" SG_ 899 VCRIGHT_hvacFastLoggingEnabled 0;
BA_ "Confidence" SG_ 1545 VCRIGHT_udsResponseData_H 1;
BA_ "Confidence" SG_ 1545 VCRIGHT_udsResponseData_L 1;
BA_ "Confidence" SG_ 1059 VCRIGHT_nmGoingToSleep 0;
BA_ "Confidence" SG_ 1059 VCRIGHT_nmWakeUpBus 0;
BA_ "Confidence" SG_ 1059 VCRIGHT_nmKeepAwakeReason 0;
BA_ "GenSigSNA" SG_ 1059 VCRIGHT_nmKeepAwakeReason "0";
BA_ "Confidence" SG_ 1059 VCRIGHT_nmWakeUpReason 0;
BA_ "Confidence" SG_ 1059 VCRIGHT_nmDebugWakeUp 0;
BA_ "Confidence" SG_ 1059 VCRIGHT_nmEthKeepAwakeReason 0;
BA_ "GenSigSNA" SG_ 1059 VCRIGHT_nmEthKeepAwakeReason "0";
BA_ "Confidence" SG_ 1059 VCRIGHT_nmChKeepAwakeReason 0;
BA_ "GenSigSNA" SG_ 1059 VCRIGHT_nmChKeepAwakeReason "0";
BA_ "Confidence" SG_ 707 VCRIGHT_windowStatusIndex 1;
BA_ "Confidence" SG_ 707 VCRIGHT_windowStateRF 0;
BA_ "Confidence" SG_ 707 VCRIGHT_windowTrimClearMoveReque 0;
BA_ "SystemSignalLongSymbol" SG_ 707 VCRIGHT_windowTrimClearMoveReque "VCRIGHT_windowTrimClearMoveRequest";
BA_ "Confidence" SG_ 707 VCRIGHT_windowDutyRF 0;
BA_ "Confidence" SG_ 707 VCRIGHT_windowTrimClearActiveReq 0;
BA_ "GenSigSNA" SG_ 707 VCRIGHT_windowTrimClearActiveReq "0";
BA_ "SystemSignalLongSymbol" SG_ 707 VCRIGHT_windowTrimClearActiveReq "VCRIGHT_windowTrimClearActiveRequest";
BA_ "Confidence" SG_ 707 VCRIGHT_windowCurrentRF 0;
BA_ "Confidence" SG_ 707 VCRIGHT_windowPositionRF 0;
BA_ "GenSigSNA" SG_ 707 VCRIGHT_windowPositionRF "1";
BA_ "Confidence" SG_ 707 VCRIGHT_windowCalibratedRF 0;
BA_ "Confidence" SG_ 707 VCRIGHT_windowStateRR 0;
BA_ "Confidence" SG_ 707 VCRIGHT_windowDutyRR 0;
BA_ "Confidence" SG_ 707 VCRIGHT_windowCurrentRR 0;
BA_ "Confidence" SG_ 707 VCRIGHT_windowPositionRR 0;
BA_ "Confidence" SG_ 707 VCRIGHT_windowCalibratedRR 0;
BA_ "Confidence" SG_ 707 VCRIGHT_windowThermalTCRF 0;
BA_ "Confidence" SG_ 707 VCRIGHT_windowThermalModeRF 0;
BA_ "GenSigSNA" SG_ 707 VCRIGHT_windowThermalModeRF "0";
BA_ "Confidence" SG_ 707 VCRIGHT_windowStopReasonRF 0;
BA_ "Confidence" SG_ 707 VCRIGHT_windowStopReqReasonRF 0;
BA_ "Confidence" SG_ 707 VCRIGHT_windowThermalTCRR 0;
BA_ "Confidence" SG_ 707 VCRIGHT_windowThermalModeRR 0;
BA_ "GenSigSNA" SG_ 707 VCRIGHT_windowThermalModeRR "0";
BA_ "Confidence" SG_ 707 VCRIGHT_windowStopReasonRR 0;
BA_ "Confidence" SG_ 707 VCRIGHT_windowStopReqReasonRR 0;
BA_ "Confidence" SG_ 707 VCRIGHT_windowControlStateRF 0;
BA_ "Confidence" SG_ 707 VCRIGHT_windowCtrlUnavailableRF 0;
BA_ "Confidence" SG_ 707 VCRIGHT_windowControlStateRR 0;
BA_ "Confidence" SG_ 707 VCRIGHT_windowCtrlUnavailableRR 0;
BA_ "Confidence" SG_ 707 VCRIGHT_windowPositionStateRF 0;
BA_ "Confidence" SG_ 707 VCRIGHT_windowPositionStateRR 0;
BA_ "Confidence" SG_ 707 VCRIGHT_windowVehGearStateRF 0;
BA_ "GenSigSNA" SG_ 707 VCRIGHT_windowVehGearStateRF "0";
BA_ "Confidence" SG_ 707 VCRIGHT_windowVehGearStateRR 0;
BA_ "GenSigSNA" SG_ 707 VCRIGHT_windowVehGearStateRR "0";
BA_ "Confidence" SG_ 707 VCRIGHT_windowSpeedTableStatusRF 0;
BA_ "GenSigSNA" SG_ 707 VCRIGHT_windowSpeedTableStatusRF "0";
BA_ "Confidence" SG_ 707 VCRIGHT_windowSpeedTableStatusRR 0;
BA_ "GenSigSNA" SG_ 707 VCRIGHT_windowSpeedTableStatusRR "0";
BA_ "Confidence" SG_ 969 VCSEC_BLEEndpointInfoIndex 1;
BA_ "Confidence" SG_ 969 VCSEC_BLECENTERComponentID 0;
BA_ "Confidence" SG_ 969 VCSEC_BLECENTERPcbaID 0;
BA_ "Confidence" SG_ 969 VCSEC_BLECENTERAssemblyID 0;
BA_ "Confidence" SG_ 969 VCSEC_BLECENTERUsageID 0;
BA_ "Confidence" SG_ 969 VCSEC_BLECENTERCrc 0;
BA_ "Confidence" SG_ 969 VCSEC_BLELEFTAppGitHashByte 0;
BA_ "Confidence" SG_ 969 VCSEC_BLELEFTComponentID 0;
BA_ "Confidence" SG_ 969 VCSEC_BLELEFTPcbaID 0;
BA_ "Confidence" SG_ 969 VCSEC_BLELEFTAssemblyID 0;
BA_ "Confidence" SG_ 969 VCSEC_BLELEFTUsageID 0;
BA_ "Confidence" SG_ 969 VCSEC_BLELEFTCrc 0;
BA_ "Confidence" SG_ 969 VCSEC_BLERIGHTAppGitHashByte 0;
BA_ "Confidence" SG_ 969 VCSEC_BLERIGHTComponentID 0;
BA_ "Confidence" SG_ 969 VCSEC_BLERIGHTPcbaID 0;
BA_ "Confidence" SG_ 969 VCSEC_BLERIGHTAssemblyID 0;
BA_ "Confidence" SG_ 969 VCSEC_BLERIGHTUsageID 0;
BA_ "Confidence" SG_ 969 VCSEC_BLERIGHTCrc 0;
BA_ "Confidence" SG_ 969 VCSEC_BLEREARAppGitHashByte 0;
BA_ "Confidence" SG_ 969 VCSEC_BLEREARComponentID 0;
BA_ "Confidence" SG_ 969 VCSEC_BLEREARPcbaID 0;
BA_ "Confidence" SG_ 969 VCSEC_BLEREARAssemblyID 0;
BA_ "Confidence" SG_ 969 VCSEC_BLEREARUsageID 0;
BA_ "Confidence" SG_ 969 VCSEC_BLEREARCrc 0;
BA_ "Confidence" SG_ 969 VCSEC_UWBRightCrc 0;
BA_ "Confidence" SG_ 969 VCSEC_UWBRightRadioConfigState 0;
BA_ "Confidence" SG_ 969 VCSEC_UWBRightUpdateStatus 0;
BA_ "GenSigSNA" SG_ 969 VCSEC_UWBRightUpdateStatus "7";
BA_ "Confidence" SG_ 969 VCSEC_UWBRightRetryLimitReached 0;
BA_ "Confidence" SG_ 969 VCSEC_UWBRightDspVersion 0;
BA_ "Confidence" SG_ 969 VCSEC_UWBRightComponentID 0;
BA_ "Confidence" SG_ 969 VCSEC_UWBRightPcbaID 0;
BA_ "Confidence" SG_ 969 VCSEC_UWBRightAssemblyID 0;
BA_ "Confidence" SG_ 969 VCSEC_UWBRightUsageID 0;
BA_ "Confidence" SG_ 969 VCSEC_UWBRearRightCrc 0;
BA_ "Confidence" SG_ 969 VCSEC_UWBRearRightRadioConfigSta 0;
BA_ "SystemSignalLongSymbol" SG_ 969 VCSEC_UWBRearRightRadioConfigSta "VCSEC_UWBRearRightRadioConfigState";
BA_ "Confidence" SG_ 969 VCSEC_UWBRearRightUpdateStatus 0;
BA_ "GenSigSNA" SG_ 969 VCSEC_UWBRearRightUpdateStatus "7";
BA_ "Confidence" SG_ 969 VCSEC_UWBRearRightRetryLimitReac 0;
BA_ "SystemSignalLongSymbol" SG_ 969 VCSEC_UWBRearRightRetryLimitReac "VCSEC_UWBRearRightRetryLimitReached";
BA_ "Confidence" SG_ 969 VCSEC_UWBRearRightDspVersion 0;
BA_ "Confidence" SG_ 969 VCSEC_UWBRearRightComponentID 0;
BA_ "Confidence" SG_ 969 VCSEC_UWBRearRightPcbaID 0;
BA_ "Confidence" SG_ 969 VCSEC_UWBRearRightAssemblyID 0;
BA_ "Confidence" SG_ 969 VCSEC_UWBRearRightUsageID 0;
BA_ "Confidence" SG_ 969 VCSEC_UWBRearLeftCrc 0;
BA_ "Confidence" SG_ 969 VCSEC_UWBRearLeftRadioConfigStat 0;
BA_ "SystemSignalLongSymbol" SG_ 969 VCSEC_UWBRearLeftRadioConfigStat "VCSEC_UWBRearLeftRadioConfigState";
BA_ "Confidence" SG_ 969 VCSEC_UWBRearLeftUpdateStatus 0;
BA_ "GenSigSNA" SG_ 969 VCSEC_UWBRearLeftUpdateStatus "7";
BA_ "Confidence" SG_ 969 VCSEC_UWBRearLeftRetryLimitReach 0;
BA_ "SystemSignalLongSymbol" SG_ 969 VCSEC_UWBRearLeftRetryLimitReach "VCSEC_UWBRearLeftRetryLimitReached";
BA_ "Confidence" SG_ 969 VCSEC_UWBRearLeftDspVersion 0;
BA_ "Confidence" SG_ 969 VCSEC_UWBRearLeftComponentID 0;
BA_ "Confidence" SG_ 969 VCSEC_UWBRearLeftPcbaID 0;
BA_ "Confidence" SG_ 969 VCSEC_UWBRearLeftAssemblyID 0;
BA_ "Confidence" SG_ 969 VCSEC_UWBRearLeftUsageID 0;
BA_ "Confidence" SG_ 969 VCSEC_UWBRearCrc 0;
BA_ "Confidence" SG_ 969 VCSEC_UWBRearRadioConfigState 0;
BA_ "Confidence" SG_ 969 VCSEC_UWBRearUpdateStatus 0;
BA_ "GenSigSNA" SG_ 969 VCSEC_UWBRearUpdateStatus "7";
BA_ "Confidence" SG_ 969 VCSEC_UWBRearRetryLimitReached 0;
BA_ "Confidence" SG_ 969 VCSEC_UWBRearDspVersion 0;
BA_ "Confidence" SG_ 969 VCSEC_UWBRearComponentID 0;
BA_ "Confidence" SG_ 969 VCSEC_UWBRearPcbaID 0;
BA_ "Confidence" SG_ 969 VCSEC_UWBRearAssemblyID 0;
BA_ "Confidence" SG_ 969 VCSEC_UWBRearUsageID 0;
BA_ "Confidence" SG_ 969 VCSEC_UWBLeftCrc 0;
BA_ "Confidence" SG_ 969 VCSEC_UWBLeftRadioConfigState 0;
BA_ "Confidence" SG_ 969 VCSEC_UWBLeftUpdateStatus 0;
BA_ "GenSigSNA" SG_ 969 VCSEC_UWBLeftUpdateStatus "7";
BA_ "Confidence" SG_ 969 VCSEC_UWBLeftRetryLimitReached 0;
BA_ "Confidence" SG_ 969 VCSEC_UWBLeftDspVersion 0;
BA_ "Confidence" SG_ 969 VCSEC_UWBLeftComponentID 0;
BA_ "Confidence" SG_ 969 VCSEC_UWBLeftPcbaID 0;
BA_ "Confidence" SG_ 969 VCSEC_UWBLeftAssemblyID 0;
BA_ "Confidence" SG_ 969 VCSEC_UWBLeftUsageID 0;
BA_ "Confidence" SG_ 969 VCSEC_UWBCenterCrc 0;
BA_ "Confidence" SG_ 969 VCSEC_UWBCenterRadioConfigState 0;
BA_ "Confidence" SG_ 969 VCSEC_UWBCenterUpdateStatus 0;
BA_ "GenSigSNA" SG_ 969 VCSEC_UWBCenterUpdateStatus "7";
BA_ "Confidence" SG_ 969 VCSEC_UWBCenterRetryLimitReached 0;
BA_ "Confidence" SG_ 969 VCSEC_UWBCenterDspVersion 0;
BA_ "Confidence" SG_ 969 VCSEC_UWBCenterComponentID 0;
BA_ "Confidence" SG_ 969 VCSEC_UWBCenterPcbaID 0;
BA_ "Confidence" SG_ 969 VCSEC_UWBCenterAssemblyID 0;
BA_ "Confidence" SG_ 969 VCSEC_UWBCenterUsageID 0;
BA_ "Confidence" SG_ 969 VCSEC_BLERIGHTREARCrc 0;
BA_ "Confidence" SG_ 969 VCSEC_BLERIGHTREARComponentID 0;
BA_ "Confidence" SG_ 969 VCSEC_BLERIGHTREARPcbaID 0;
BA_ "Confidence" SG_ 969 VCSEC_BLERIGHTREARAssemblyID 0;
BA_ "Confidence" SG_ 969 VCSEC_BLERIGHTREARUsageID 0;
BA_ "Confidence" SG_ 969 VCSEC_BLENFCCRADLECrc 0;
BA_ "Confidence" SG_ 969 VCSEC_BLENFCCRADLEComponentID 0;
BA_ "Confidence" SG_ 969 VCSEC_BLENFCCRADLEPcbaID 0;
BA_ "Confidence" SG_ 969 VCSEC_BLENFCCRADLEAssemblyID 0;
BA_ "Confidence" SG_ 969 VCSEC_BLENFCCRADLEUsageID 0;
BA_ "Confidence" SG_ 969 VCSEC_BLELEFTREARCrc 0;
BA_ "Confidence" SG_ 969 VCSEC_BLELEFTREARComponentID 0;
BA_ "Confidence" SG_ 969 VCSEC_BLELEFTREARPcbaID 0;
BA_ "Confidence" SG_ 969 VCSEC_BLELEFTREARAssemblyID 0;
BA_ "Confidence" SG_ 969 VCSEC_BLELEFTREARUsageID 0;
BA_ "Confidence" SG_ 607 VCSEC_childSeat0_connectionState 0;
BA_ "Confidence" SG_ 607 VCSEC_childSeat0_taskDisconnecti 0;
BA_ "SystemSignalLongSymbol" SG_ 607 VCSEC_childSeat0_taskDisconnecti "VCSEC_childSeat0_taskDisconnectionReason";
BA_ "Confidence" SG_ 607 VCSEC_childSeat0_state 0;
BA_ "Confidence" SG_ 607 VCSEC_childSeat0_taskErrorCode 0;
BA_ "Confidence" SG_ 607 VCSEC_childSeat0_RSSI 0;
BA_ "GenSigSNA" SG_ 607 VCSEC_childSeat0_RSSI "127";
BA_ "Confidence" SG_ 607 VCSEC_childSeat0_ISOFixStatus 0;
BA_ "Confidence" SG_ 607 VCSEC_childSeat0_buckleStatus 0;
BA_ "Confidence" SG_ 607 VCSEC_childSeat0_occupancyStatus 0;
BA_ "Confidence" SG_ 607 VCSEC_childSeat1_connectionState 0;
BA_ "Confidence" SG_ 607 VCSEC_childSeat1_taskDisconnecti 0;
BA_ "SystemSignalLongSymbol" SG_ 607 VCSEC_childSeat1_taskDisconnecti "VCSEC_childSeat1_taskDisconnectionReason";
BA_ "Confidence" SG_ 607 VCSEC_childSeat1_state 0;
BA_ "Confidence" SG_ 607 VCSEC_childSeat1_taskErrorCode 0;
BA_ "Confidence" SG_ 607 VCSEC_childSeat1_RSSI 0;
BA_ "GenSigSNA" SG_ 607 VCSEC_childSeat1_RSSI "127";
BA_ "Confidence" SG_ 607 VCSEC_childSeat1_ISOFixStatus 0;
BA_ "Confidence" SG_ 607 VCSEC_childSeat1_buckleStatus 0;
BA_ "Confidence" SG_ 607 VCSEC_childSeat1_occupancyStatus 0;
BA_ "Confidence" SG_ 607 VCSEC_childPresenceDetectionWarn 0;
BA_ "SystemSignalLongSymbol" SG_ 607 VCSEC_childPresenceDetectionWarn "VCSEC_childPresenceDetectionWarningActive";
BA_ "Confidence" SG_ 607 VCSEC_childSeatScanStatus 0;
BA_ "Confidence" SG_ 607 VCSEC_childPresenceDetectionStat 0;
BA_ "SystemSignalLongSymbol" SG_ 607 VCSEC_childPresenceDetectionStat "VCSEC_childPresenceDetectionState";
BA_ "Confidence" SG_ 607 VCSEC_childPresenceDetectionSupp 0;
BA_ "SystemSignalLongSymbol" SG_ 607 VCSEC_childPresenceDetectionSupp "VCSEC_childPresenceDetectionSupportType";
BA_ "Confidence" SG_ 607 VCSEC_childPresenceDetectionNoti 0;
BA_ "SystemSignalLongSymbol" SG_ 607 VCSEC_childPresenceDetectionNoti "VCSEC_childPresenceDetectionNotificationEnabled";
VAL_ 611 VCRIGHT_logging10HzIndex 5 "END" 4 "HVAC_ACTUATOR_BRUSHED_DUTY" 3 "HVAC_ACTUATOR_BRUSHED" 2 "HVAC_ACTUATOR_STATE" 1 "HVAC_ACTUATOR_POSITIONS" 0 "HVAC_ACTUATOR_TARGETS" ;
VAL_ 611 VCRIGHT_hvacLHBleedActuatorState 2 "HVACACTUATOR_STATE_COASTING" 1 "HVACACTUATOR_STATE_RUNNING" 0 "HVACACTUATOR_STATE_BRAKING" ;
VAL_ 611 VCRIGHT_hvacRHBleedActuatorState 2 "HVACACTUATOR_STATE_COASTING" 1 "HVACACTUATOR_STATE_RUNNING" 0 "HVACACTUATOR_STATE_BRAKING" ;
VAL_ 611 VCRIGHT_hvacLHVaneActuatorState 2 "HVACACTUATOR_STATE_COASTING" 1 "HVACACTUATOR_STATE_RUNNING" 0 "HVACACTUATOR_STATE_BRAKING" ;
VAL_ 611 VCRIGHT_hvacRHVaneActuatorState 2 "HVACACTUATOR_STATE_COASTING" 1 "HVACACTUATOR_STATE_RUNNING" 0 "HVACACTUATOR_STATE_BRAKING" ;
VAL_ 611 VCRIGHT_hvacUpperModeActState 2 "HVACACTUATOR_STATE_COASTING" 1 "HVACACTUATOR_STATE_RUNNING" 0 "HVACACTUATOR_STATE_BRAKING" ;
VAL_ 611 VCRIGHT_hvacLowerModeActState 2 "HVACACTUATOR_STATE_COASTING" 1 "HVACACTUATOR_STATE_RUNNING" 0 "HVACACTUATOR_STATE_BRAKING" ;
VAL_ 611 VCRIGHT_hvacIntakeActuatorState 2 "HVACACTUATOR_STATE_COASTING" 1 "HVACACTUATOR_STATE_RUNNING" 0 "HVACACTUATOR_STATE_BRAKING" ;
VAL_ 611 VCRIGHT_hvacRearActuatorState 2 "HVACACTUATOR_STATE_COASTING" 1 "HVACACTUATOR_STATE_RUNNING" 0 "HVACACTUATOR_STATE_BRAKING" ;
VAL_ 611 VCRIGHT_tempDatLeftEst 255 "SNA" ;
VAL_ 611 VCRIGHT_tempDatRightEst 255 "SNA" ;
VAL_ 611 VCRIGHT_tempDuctLeftEst 255 "SNA" ;
VAL_ 611 VCRIGHT_tempDuctRightEst 255 "SNA" ;
VAL_ 611 VCRIGHT_ptcHeaterBadRodDetection 11 "UNAVAILABLE" 10 "CLEAR_FAULT_RESTART" 9 "CLEAR_FAULT" 8 "CHECK_RIGHT_INNER" 7 "CHECK_RIGHT_CENTER" 6 "CHECK_RIGHT_OUTER" 5 "CHECK_LEFT_INNER" 4 "CHECK_LEFT_CENTER" 3 "CHECK_LEFT_OUTER" 2 "DETECTED" 1 "IDLE" 0 "INIT" ;
VAL_ 611 VCRIGHT_upperModeDrvActuatorStat 11 "HVAC_ACTUATOR_BRUSHED_STATE_RUNNING_OVERSHOOT" 10 "HVAC_ACTUATOR_BRUSHED_STATE_NEGATIVE_BACKOFF" 9 "HVAC_ACTUATOR_BRUSHED_STATE_POSITIVE_BACKOFF" 8 "HVAC_ACTUATOR_BRUSHED_STATE_CONTROL_DISABLED" 7 "HVAC_ACTUATOR_BRUSHED_STATE_FAULT" 6 "HVAC_ACTUATOR_BRUSHED_STATE_BRAKING" 5 "HVAC_ACTUATOR_BRUSHED_STATE_RUNNING" 4 "HVAC_ACTUATOR_BRUSHED_STATE_NEGATIVE_STALL" 3 "HVAC_ACTUATOR_BRUSHED_STATE_NEGATIVE_RUN" 2 "HVAC_ACTUATOR_BRUSHED_STATE_POSITIVE_STALL" 1 "HVAC_ACTUATOR_BRUSHED_STATE_POSITIVE_RUN" 0 "HVAC_ACTUATOR_BRUSHED_STATE_INIT" ;
VAL_ 611 VCRIGHT_leftVerticalActuatorStat 11 "HVAC_ACTUATOR_BRUSHED_STATE_RUNNING_OVERSHOOT" 10 "HVAC_ACTUATOR_BRUSHED_STATE_NEGATIVE_BACKOFF" 9 "HVAC_ACTUATOR_BRUSHED_STATE_POSITIVE_BACKOFF" 8 "HVAC_ACTUATOR_BRUSHED_STATE_CONTROL_DISABLED" 7 "HVAC_ACTUATOR_BRUSHED_STATE_FAULT" 6 "HVAC_ACTUATOR_BRUSHED_STATE_BRAKING" 5 "HVAC_ACTUATOR_BRUSHED_STATE_RUNNING" 4 "HVAC_ACTUATOR_BRUSHED_STATE_NEGATIVE_STALL" 3 "HVAC_ACTUATOR_BRUSHED_STATE_NEGATIVE_RUN" 2 "HVAC_ACTUATOR_BRUSHED_STATE_POSITIVE_STALL" 1 "HVAC_ACTUATOR_BRUSHED_STATE_POSITIVE_RUN" 0 "HVAC_ACTUATOR_BRUSHED_STATE_INIT" ;
VAL_ 611 VCRIGHT_leftLateralActuatorState 11 "HVAC_ACTUATOR_BRUSHED_STATE_RUNNING_OVERSHOOT" 10 "HVAC_ACTUATOR_BRUSHED_STATE_NEGATIVE_BACKOFF" 9 "HVAC_ACTUATOR_BRUSHED_STATE_POSITIVE_BACKOFF" 8 "HVAC_ACTUATOR_BRUSHED_STATE_CONTROL_DISABLED" 7 "HVAC_ACTUATOR_BRUSHED_STATE_FAULT" 6 "HVAC_ACTUATOR_BRUSHED_STATE_BRAKING" 5 "HVAC_ACTUATOR_BRUSHED_STATE_RUNNING" 4 "HVAC_ACTUATOR_BRUSHED_STATE_NEGATIVE_STALL" 3 "HVAC_ACTUATOR_BRUSHED_STATE_NEGATIVE_RUN" 2 "HVAC_ACTUATOR_BRUSHED_STATE_POSITIVE_STALL" 1 "HVAC_ACTUATOR_BRUSHED_STATE_POSITIVE_RUN" 0 "HVAC_ACTUATOR_BRUSHED_STATE_INIT" ;
VAL_ 611 VCRIGHT_rightVerticalActuatorSta 11 "HVAC_ACTUATOR_BRUSHED_STATE_RUNNING_OVERSHOOT" 10 "HVAC_ACTUATOR_BRUSHED_STATE_NEGATIVE_BACKOFF" 9 "HVAC_ACTUATOR_BRUSHED_STATE_POSITIVE_BACKOFF" 8 "HVAC_ACTUATOR_BRUSHED_STATE_CONTROL_DISABLED" 7 "HVAC_ACTUATOR_BRUSHED_STATE_FAULT" 6 "HVAC_ACTUATOR_BRUSHED_STATE_BRAKING" 5 "HVAC_ACTUATOR_BRUSHED_STATE_RUNNING" 4 "HVAC_ACTUATOR_BRUSHED_STATE_NEGATIVE_STALL" 3 "HVAC_ACTUATOR_BRUSHED_STATE_NEGATIVE_RUN" 2 "HVAC_ACTUATOR_BRUSHED_STATE_POSITIVE_STALL" 1 "HVAC_ACTUATOR_BRUSHED_STATE_POSITIVE_RUN" 0 "HVAC_ACTUATOR_BRUSHED_STATE_INIT" ;
VAL_ 611 VCRIGHT_rightLateralActuatorStat 11 "HVAC_ACTUATOR_BRUSHED_STATE_RUNNING_OVERSHOOT" 10 "HVAC_ACTUATOR_BRUSHED_STATE_NEGATIVE_BACKOFF" 9 "HVAC_ACTUATOR_BRUSHED_STATE_POSITIVE_BACKOFF" 8 "HVAC_ACTUATOR_BRUSHED_STATE_CONTROL_DISABLED" 7 "HVAC_ACTUATOR_BRUSHED_STATE_FAULT" 6 "HVAC_ACTUATOR_BRUSHED_STATE_BRAKING" 5 "HVAC_ACTUATOR_BRUSHED_STATE_RUNNING" 4 "HVAC_ACTUATOR_BRUSHED_STATE_NEGATIVE_STALL" 3 "HVAC_ACTUATOR_BRUSHED_STATE_NEGATIVE_RUN" 2 "HVAC_ACTUATOR_BRUSHED_STATE_POSITIVE_STALL" 1 "HVAC_ACTUATOR_BRUSHED_STATE_POSITIVE_RUN" 0 "HVAC_ACTUATOR_BRUSHED_STATE_INIT" ;
VAL_ 611 VCRIGHT_windshieldRHExteriorSurf 255 "SNA" ;
VAL_ 611 VCRIGHT_frontLeftSeatTempTargetQ 0 "OFF" ;
VAL_ 611 VCRIGHT_frontRightSeatTempTarget 0 "OFF" ;
VAL_ 691 VCRIGHT_logging1HzIndex 17 "END" 16 "MISCELLANEOUS_LOGGING" 15 "HVAC_MISCELLANEOUS_3" 14 "STEERING_WHEEL_HEAT" 13 "HVAC_COMFORT_SOLAR_3" 12 "HVAC_COMFORT_SOLAR_2" 11 "HSD_CURRENTS_2" 10 "HSD_CURRENTS_1" 9 "HVAC_MISCELLANEOUS_2" 8 "HVAC_MISCELLANEOUS_1" 7 "HVAC_TEMP_SENSORS_AND_ESTIMATES_3" 6 "HVAC_ACTUATOR_VOLTAGES" 5 "HEATER_AND_DUCT_TARGETS" 4 "HVAC_COMFORT_SOLAR" 3 "HVAC_STATUS_AIRFLOW" 2 "HVAC_HUMIDITY_HEATER_TEMP" 1 "HVAC_TEMP_SENSORS_AND_ESTIMATES_2" 0 "HVAC_TEMP_SENSORS_AND_ESTIMATES_1" ;
VAL_ 691 VCRIGHT_glareShieldHeaterState 4 "FAULT" 3 "INACTIVE" 2 "PASSIVE" 1 "REQUESTED" 0 "IDLE" ;
VAL_ 691 VCRIGHT_tempIncarCabinProbe 255 "SNA" ;
VAL_ 691 VCRIGHT_cabinTempInteriorL2 255 "SNA" ;
VAL_ 691 VCRIGHT_cabinTempInteriorSunnyL2 255 "SNA" ;
VAL_ 691 VCRIGHT_tempIncarCabinMid 250 "SNA" ;
VAL_ 691 VCRIGHT_cabinTempInteriorL3 255 "SNA" ;
VAL_ 691 VCRIGHT_cabinTempInteriorSunnyL3 255 "SNA" ;
VAL_ 691 VCRIGHT_tempWetBulb 255 "SNA" ;
VAL_ 691 VCRIGHT_cabinTempGlassRoof 255 "SNA" ;
VAL_ 691 VCRIGHT_cabinTempWindshield 255 "SNA" ;
VAL_ 691 VCRIGHT_cabinTempInterior 255 "SNA" ;
VAL_ 691 VCRIGHT_cabinTempInteriorSunny 255 "SNA" ;
VAL_ 691 VCRIGHT_cabinTempSideGlassLeft 255 "SNA" ;
VAL_ 691 VCRIGHT_cabinTempSideGlassRight 255 "SNA" ;
VAL_ 691 VCRIGHT_cabinTempBreathLevel 255 "SNA" ;
VAL_ 691 VCRIGHT_hvacAutoTransitionReason 23 "END" 22 "VOC_PURGE" 21 "RETURN_FROM_DEFOG_OVERRIDE" 20 "HVAC_AIR_HUMID" 19 "BIODEFENSE" 18 "DUCT_TARGETS_INVALID" 17 "HVAC_OFF" 16 "EVAP_OIL_PURGE" 15 "EVAP_DRYING" 14 "CABIN_PURGE" 13 "SET_TEMP_HI" 12 "SET_TEMP_LO" 11 "DEFOG_OVERRIDE" 10 "BI_LEVEL_LANDING" 9 "DUCTS_COLD" 8 "TEMP_TARGET_LOW" 7 "OCCUPANT_CONVECTION_REQUIREMENT" 6 "EXCESS_OCCUPANT_CONVECTION" 5 "TEMP_TARGET_ABOVE_THRESHOLD" 4 "TEMP_TARGET_BELOW_THRESHOLD" 3 "HUMIDITY_LOW" 2 "HUMIDITY_MODERATE" 1 "HUMIDITY_HIGH" 0 "NONE" ;
VAL_ 691 VCRIGHT_hvacLHBleedOperationMode 1 "HVACACTUATOR_OPERATION_MODE_CALIBRATION" 0 "HVACACTUATOR_OPERATION_MODE_NORMAL" ;
VAL_ 691 VCRIGHT_hvacRHBleedOperationMode 1 "HVACACTUATOR_OPERATION_MODE_CALIBRATION" 0 "HVACACTUATOR_OPERATION_MODE_NORMAL" ;
VAL_ 691 VCRIGHT_hvacLHVaneOperationMode 1 "HVACACTUATOR_OPERATION_MODE_CALIBRATION" 0 "HVACACTUATOR_OPERATION_MODE_NORMAL" ;
VAL_ 691 VCRIGHT_hvacRHVaneOperationMode 1 "HVACACTUATOR_OPERATION_MODE_CALIBRATION" 0 "HVACACTUATOR_OPERATION_MODE_NORMAL" ;
VAL_ 691 VCRIGHT_hvacUpperModeOpMode 1 "HVACACTUATOR_OPERATION_MODE_CALIBRATION" 0 "HVACACTUATOR_OPERATION_MODE_NORMAL" ;
VAL_ 691 VCRIGHT_hvacLowerModeOpMode 1 "HVACACTUATOR_OPERATION_MODE_CALIBRATION" 0 "HVACACTUATOR_OPERATION_MODE_NORMAL" ;
VAL_ 691 VCRIGHT_hvacIntakeOperationMode 1 "HVACACTUATOR_OPERATION_MODE_CALIBRATION" 0 "HVACACTUATOR_OPERATION_MODE_NORMAL" ;
VAL_ 691 VCRIGHT_hvacRearOperationMode 1 "HVACACTUATOR_OPERATION_MODE_CALIBRATION" 0 "HVACACTUATOR_OPERATION_MODE_NORMAL" ;
VAL_ 691 VCRIGHT_isProbeFeedbackApplied 4 "NEGATIVEHIGH" 3 "POSITIVEHIGH" 2 "NEGATIVE" 1 "POSITIVE" 0 "OFF" ;
VAL_ 691 VCRIGHT_convectionTargetLeft 511 "SNA" ;
VAL_ 691 VCRIGHT_convectionTargetRight 511 "SNA" ;
VAL_ 691 VCRIGHT_convectionDeliveredLeft 511 "SNA" ;
VAL_ 691 VCRIGHT_convectionDeliveredRight 511 "SNA" ;
VAL_ 691 VCRIGHT_solarLoadRightOccupant 127 "SNA" ;
VAL_ 691 VCRIGHT_solarLoadLeftOccupant 127 "SNA" ;
VAL_ 691 VCRIGHT_solarLoadFromThsTemp 255 "SNA" ;
VAL_ 691 VCRIGHT_cabinTempWshldDefog 255 "SNA" ;
VAL_ 691 VCRIGHT_cabinTempWshldDefogTop 255 "SNA" ;
VAL_ 691 VCRIGHT_cabinTempBreathLevelFHea 255 "SNA" ;
VAL_ 691 VCRIGHT_cabinTempBreathLevelFCoo 255 "SNA" ;
VAL_ 691 VCRIGHT_hvacTorqueMassflowEstima 5 "HVAC_TORQUE_MASSFLOW_ESTIMATE_STATUS_COMPUTED_FILTERED" 4 "HVAC_TORQUE_MASSFLOW_ESTIMATE_STATUS_COMPUTED_UNFILTERED" 3 "HVAC_TORQUE_MASSFLOW_ESTIMATE_STATUS_CFM_NEGATIVE" 2 "HVAC_TORQUE_MASSFLOW_ESTIMATE_STATUS_DISCRIMINANT_NEGATIVE" 1 "HVAC_TORQUE_MASSFLOW_ESTIMATE_STATUS_TORQUE_BELOW_OFFSET" 0 "HVAC_TORQUE_MASSFLOW_ESTIMATE_STATUS_BLOWER_NOT_ACTIVE" ;
VAL_ 691 VCRIGHT_AP_humidityModelBasedCab 1023 "SNA" ;
VAL_ 691 VCRIGHT_solarLoadOnVehFiltered 255 "SNA" ;
VAL_ 691 VCRIGHT_cabinTempProbeEstimate 255 "SNA" ;
VAL_ 691 VCRIGHT_cabinTempThs 255 "SNA" ;
VAL_ 691 VCRIGHT_cabinTempThsBracket 255 "SNA" ;
VAL_ 691 VCRIGHT_CO2ppm 1023 "SNA" ;
VAL_ 691 VCRIGHT_reverseFogLightsCurrent 15 "SNA" ;
VAL_ 691 VCRIGHT_sideMirrorHeaterCurrent 31 "SNA" ;
VAL_ 691 VCRIGHT_trunkInteriorLEDCurrent 15 "SNA" ;
VAL_ 691 VCRIGHT_mapPocketLEDsCurrent 15 "SNA" ;
VAL_ 691 VCRIGHT_miscEFuseCurrent 31 "SNA" ;
VAL_ 691 VCRIGHT_miscInteriorLightsCurren 7 "SNA" ;
VAL_ 691 VCRIGHT_frontPuddleLEDCurrent 7 "SNA" ;
VAL_ 691 VCRIGHT_rearPuddleLEDCurrent 7 "SNA" ;
VAL_ 691 VCRIGHT_liftgateShutfaceLEDCurre 7 "SNA" ;
VAL_ 691 VCRIGHT_3rSeatTOSCurrent 15 "SNA" ;
VAL_ 691 VCRIGHT_vbatFusedCurrent 15 "SNA" ;
VAL_ 691 VCRIGHT_cabinTempGlassGridHeater 255 "SNA" ;
VAL_ 691 VCRIGHT_hvacAirflowReasonRight 21 "NONE" 20 "ODOR_ROUTINE" 19 "DRIVERLESS_SELF_TEST" 18 "VOC_PURGE" 17 "STRATIFICATION_TOP_PAD_AREA" 16 "HOT_DUCT_LOCKOUT" 15 "COLD_DUCT_LOCKOUT" 14 "BIOWEAPON_DEFENSE" 13 "EVAP_OIL_PURGE" 12 "EVAP_DRYING" 11 "SCREEN_PROTECTION" 10 "CABIN_OVERHEAT_PROTECT" 9 "CABIN_PURGE" 8 "OUTLET_TEMP_LIMIT" 7 "OCCUPANT_CONVECTION_REQUIREMENT" 6 "STRATIFICATION_INTERIOR_SURFACES" 5 "STRATIFICATION_GLASS_ROOF" 4 "MINIMUM_AUTO_AIRFLOW" 3 "CABIN_TEMPERATURE_CONTROL" 2 "UI_SHORTCUT" 1 "MANUAL_FAN_SPEED" 0 "HVAC_OFF" ;
VAL_ 691 VCRIGHT_hvacAirflowReasonLeft 21 "NONE" 20 "ODOR_ROUTINE" 19 "DRIVERLESS_SELF_TEST" 18 "VOC_PURGE" 17 "STRATIFICATION_TOP_PAD_AREA" 16 "HOT_DUCT_LOCKOUT" 15 "COLD_DUCT_LOCKOUT" 14 "BIOWEAPON_DEFENSE" 13 "EVAP_OIL_PURGE" 12 "EVAP_DRYING" 11 "SCREEN_PROTECTION" 10 "CABIN_OVERHEAT_PROTECT" 9 "CABIN_PURGE" 8 "OUTLET_TEMP_LIMIT" 7 "OCCUPANT_CONVECTION_REQUIREMENT" 6 "STRATIFICATION_INTERIOR_SURFACES" 5 "STRATIFICATION_GLASS_ROOF" 4 "MINIMUM_AUTO_AIRFLOW" 3 "CABIN_TEMPERATURE_CONTROL" 2 "UI_SHORTCUT" 1 "MANUAL_FAN_SPEED" 0 "HVAC_OFF" ;
VAL_ 691 VCRIGHT_solarLoadLeftOccupantFil 127 "SNA" ;
VAL_ 691 VCRIGHT_solarLoadRightOccupantFi 127 "SNA" ;
VAL_ 691 VCRIGHT_airflowReasonAutoInManua 21 "NONE" 20 "ODOR_ROUTINE" 19 "DRIVERLESS_SELF_TEST" 18 "VOC_PURGE" 17 "STRATIFICATION_TOP_PAD_AREA" 16 "HOT_DUCT_LOCKOUT" 15 "COLD_DUCT_LOCKOUT" 14 "BIOWEAPON_DEFENSE" 13 "EVAP_OIL_PURGE" 12 "EVAP_DRYING" 11 "SCREEN_PROTECTION" 10 "CABIN_OVERHEAT_PROTECT" 9 "CABIN_PURGE" 8 "OUTLET_TEMP_LIMIT" 7 "OCCUPANT_CONVECTION_REQUIREMENT" 6 "STRATIFICATION_INTERIOR_SURFACES" 5 "STRATIFICATION_GLASS_ROOF" 4 "MINIMUM_AUTO_AIRFLOW" 3 "CABIN_TEMPERATURE_CONTROL" 2 "UI_SHORTCUT" 1 "MANUAL_FAN_SPEED" 0 "HVAC_OFF" ;
VAL_ 691 VCRIGHT_airflowReasonAutoIn_0001 21 "NONE" 20 "ODOR_ROUTINE" 19 "DRIVERLESS_SELF_TEST" 18 "VOC_PURGE" 17 "STRATIFICATION_TOP_PAD_AREA" 16 "HOT_DUCT_LOCKOUT" 15 "COLD_DUCT_LOCKOUT" 14 "BIOWEAPON_DEFENSE" 13 "EVAP_OIL_PURGE" 12 "EVAP_DRYING" 11 "SCREEN_PROTECTION" 10 "CABIN_OVERHEAT_PROTECT" 9 "CABIN_PURGE" 8 "OUTLET_TEMP_LIMIT" 7 "OCCUPANT_CONVECTION_REQUIREMENT" 6 "STRATIFICATION_INTERIOR_SURFACES" 5 "STRATIFICATION_GLASS_ROOF" 4 "MINIMUM_AUTO_AIRFLOW" 3 "CABIN_TEMPERATURE_CONTROL" 2 "UI_SHORTCUT" 1 "MANUAL_FAN_SPEED" 0 "HVAC_OFF" ;
VAL_ 691 VCRIGHT_airflowReasonAutoIn_0002 21 "NONE" 20 "ODOR_ROUTINE" 19 "DRIVERLESS_SELF_TEST" 18 "VOC_PURGE" 17 "STRATIFICATION_TOP_PAD_AREA" 16 "HOT_DUCT_LOCKOUT" 15 "COLD_DUCT_LOCKOUT" 14 "BIOWEAPON_DEFENSE" 13 "EVAP_OIL_PURGE" 12 "EVAP_DRYING" 11 "SCREEN_PROTECTION" 10 "CABIN_OVERHEAT_PROTECT" 9 "CABIN_PURGE" 8 "OUTLET_TEMP_LIMIT" 7 "OCCUPANT_CONVECTION_REQUIREMENT" 6 "STRATIFICATION_INTERIOR_SURFACES" 5 "STRATIFICATION_GLASS_ROOF" 4 "MINIMUM_AUTO_AIRFLOW" 3 "CABIN_TEMPERATURE_CONTROL" 2 "UI_SHORTCUT" 1 "MANUAL_FAN_SPEED" 0 "HVAC_OFF" ;
VAL_ 691 VCRIGHT_vocSweatMassSeat 255 "SNA" ;
VAL_ 691 VCRIGHT_vocSweatConcentrationAir 255 "SNA" ;
VAL_ 691 VCRIGHT_steeringWheelSurfaceTemp 1023 "SNA" ;
VAL_ 691 VCRIGHT_steeringWheelSurfac_0001 1023 "SNA" ;
VAL_ 691 VCRIGHT_timeToComfortHeating 63 "HVAC_OFF" 62 "UNATTAINABLE" 0 "IN_COMFORT_BAND" ;
VAL_ 691 VCRIGHT_timeToComfortCooling 63 "HVAC_OFF" 62 "UNATTAINABLE" 0 "IN_COMFORT_BAND" ;
VAL_ 691 VCRIGHT_cabinWaterMassRaw 255 "SNA" ;
VAL_ 691 VCRIGHT_VOCPurgeState 5 "PURGING_AND_DRYING" 4 "WAITING" 3 "PURGING" 2 "IDLE" 1 "INACTIVE" 0 "INIT" ;
VAL_ 691 VCRIGHT_cameraFoggingMonitorStat 6 "PRE_RUN_PURGE" 5 "IDLE" 4 "INACTIVE" 3 "RUNNING" 2 "WAKEUP" 1 "MONITORING" 0 "INIT" ;
VAL_ 691 VCRIGHT_windWeatherSource 2 "FALLBACK" 1 "FORECAST" 0 "CURRENT" ;
VAL_ 691 VCRIGHT_humidityRatioWeatherSour 2 "FALLBACK" 1 "FORECAST" 0 "CURRENT" ;
VAL_ 691 VCRIGHT_hvacIntakeReason 26 "INTAKE_REASON_ODOR_ROUTINE" 25 "INTAKE_REASON_HVAC_OFF_IN_MOTION" 24 "INTAKE_REASON_LIFTGATE_CLOSING" 23 "INTAKE_REASON_DRIVERLESS_SELF_TEST" 22 "INTAKE_REASON_VOC_PURGE" 21 "INTAKE_REASON_STEAMING" 20 "INTAKE_REASON_PULLDOWN_IN_FRESH" 19 "INTAKE_REASON_RECIRC_NVH" 18 "INTAKE_REASON_CO2_PURGE" 17 "INTAKE_REASON_HVAC_OFF" 16 "INTAKE_REASON_PARK_POSITION" 15 "INTAKE_REASON_EVAP_DRYING" 14 "INTAKE_REASON_OIL_PURGE" 13 "INTAKE_REASON_CABIN_PURGE" 12 "INTAKE_REASON_COP" 11 "INTAKE_REASON_ENHANCED_FILTERATION" 10 "INTAKE_REASON_CHARGE_PORT_THAW" 9 "INTAKE_REASON_PRECON_OVERRIDE" 8 "INTAKE_REASON_HUMIDITY" 7 "INTAKE_REASON_BIO_WEAPON_STEADY" 6 "INTAKE_REASON_BIO_WEAPON_INIT" 5 "INTAKE_REASON_TEMPERATURE_CONTROL" 4 "INTAKE_REASON_MANUAL_RECIRC" 3 "INTAKE_REASON_MANUAL_FRESH" 2 "INTAKE_REASON_CAR_WASH" 1 "INTAKE_REASON_UDS" 0 "INTAKE_REASON_NONE" ;
VAL_ 691 VCRIGHT_solarAzimuthCarRef -1023 "SNA" ;
VAL_ 691 VCRIGHT_hvacLimpModeStatus 4 "LIMP_MODE_FAULTED" 3 "LIMP_MODE_ACTIVE" 2 "LIMP_MODE_READY" 1 "LIMP_MODE_WAITING_FOR_SENSORS" 0 "LIMP_MODE_NOT_NEEDED" ;
VAL_ 691 VCRIGHT_hvacEstimatedCameraWinds 255 "SNA" ;
VAL_ 691 VCRIGHT_cabinTempRoofL2 255 "SNA" ;
VAL_ 691 VCRIGHT_cabinTempRoofL3 255 "SNA" ;
VAL_ 691 VCRIGHT_odorRoutineState 7 "SNA" 6 "BLOCKED_NO_TRIP_END" 5 "BLOCKED_NO_HVAC_PERMISSION" 4 "BLOCKED_NO_RIDESTATE" 3 "AUTO_ACTIVE" 2 "WAITING_FOR_ACTIVATION" 1 "IDLE" 0 "INACTIVE" ;
VAL_ 691 VCRIGHT_cameraDefogState 3 "FAULT" 2 "ACTIVE" 1 "IDLE" 0 "INACTIVE" ;
VAL_ 1859 VCRIGHT_systemRecallStatus 3 "RECALL_INTERRUPTED" 2 "RECALL_COMPLETE" 1 "RECALL_IN_PROGRESS" 0 "RECALL_SNA" ;
VAL_ 1859 VCRIGHT_seatRecallStatus 3 "RECALL_INTERRUPTED" 2 "RECALL_COMPLETE" 1 "RECALL_IN_PROGRESS" 0 "RECALL_SNA" ;
VAL_ 1859 VCRIGHT_mirrorRecallStatus 3 "RECALL_INTERRUPTED" 2 "RECALL_COMPLETE" 1 "RECALL_IN_PROGRESS" 0 "RECALL_SNA" ;
VAL_ 1251 VCRIGHT_seatStatusIndex 7 "RELATIVE_POSITION" 6 "OFFSETS" 5 "POSITION" 4 "LUMBAR" 3 "TILT" 2 "LIFT" 1 "BACK" 0 "TRACK" ;
VAL_ 1251 VC_AH_1RowRightSeatMovementHealt 4 "SEAT_CALIBRATION_REQUIRED" 3 "SEAT_IN_NON_USE_POSITION" 2 "SEAT_CANNOT_MOVE" 1 "SEAT_MOVEMENT_HEALTHY" 0 "SEAT_MOVEMENT_HEALTH_UNKNOWN" ;
VAL_ 1251 VCRIGHT_frontSeatTrackState 5 "SEAT_STATE_UNDEFINED" 4 "SEAT_STATE_CALIBRATING" 3 "SEAT_STATE_RECALLING" 2 "SEAT_STATE_MOVING_DOWN" 1 "SEAT_STATE_MOVING_UP" 0 "SEAT_STATE_STOPPED" ;
VAL_ 1251 VCRIGHT_frontSeatTrackBridgeSt 3 "IO_BRIDGE_STATE_COAST" 2 "IO_BRIDGE_STATE_BRAKE" 1 "IO_BRIDGE_STATE_ENABLED" 0 "IO_BRIDGE_STATE_DISABLED" ;
VAL_ 1251 VCRIGHT_frontSeatBackState 5 "SEAT_STATE_UNDEFINED" 4 "SEAT_STATE_CALIBRATING" 3 "SEAT_STATE_RECALLING" 2 "SEAT_STATE_MOVING_DOWN" 1 "SEAT_STATE_MOVING_UP" 0 "SEAT_STATE_STOPPED" ;
VAL_ 1251 VCRIGHT_frontSeatBackBridgeSt 3 "IO_BRIDGE_STATE_COAST" 2 "IO_BRIDGE_STATE_BRAKE" 1 "IO_BRIDGE_STATE_ENABLED" 0 "IO_BRIDGE_STATE_DISABLED" ;
VAL_ 1251 VCRIGHT_frontSeatLiftState 5 "SEAT_STATE_UNDEFINED" 4 "SEAT_STATE_CALIBRATING" 3 "SEAT_STATE_RECALLING" 2 "SEAT_STATE_MOVING_DOWN" 1 "SEAT_STATE_MOVING_UP" 0 "SEAT_STATE_STOPPED" ;
VAL_ 1251 VCRIGHT_frontSeatLiftBridgeSt 3 "IO_BRIDGE_STATE_COAST" 2 "IO_BRIDGE_STATE_BRAKE" 1 "IO_BRIDGE_STATE_ENABLED" 0 "IO_BRIDGE_STATE_DISABLED" ;
VAL_ 1251 VCRIGHT_frontSeatTiltState 5 "SEAT_STATE_UNDEFINED" 4 "SEAT_STATE_CALIBRATING" 3 "SEAT_STATE_RECALLING" 2 "SEAT_STATE_MOVING_DOWN" 1 "SEAT_STATE_MOVING_UP" 0 "SEAT_STATE_STOPPED" ;
VAL_ 1251 VCRIGHT_frontSeatTiltBridgeSt 3 "IO_BRIDGE_STATE_COAST" 2 "IO_BRIDGE_STATE_BRAKE" 1 "IO_BRIDGE_STATE_ENABLED" 0 "IO_BRIDGE_STATE_DISABLED" ;
VAL_ 1251 VCRIGHT_lumbarAState 5 "SEAT_STATE_UNDEFINED" 4 "SEAT_STATE_CALIBRATING" 3 "SEAT_STATE_RECALLING" 2 "SEAT_STATE_MOVING_DOWN" 1 "SEAT_STATE_MOVING_UP" 0 "SEAT_STATE_STOPPED" ;
VAL_ 1251 VCRIGHT_lumbarBState 5 "SEAT_STATE_UNDEFINED" 4 "SEAT_STATE_CALIBRATING" 3 "SEAT_STATE_RECALLING" 2 "SEAT_STATE_MOVING_DOWN" 1 "SEAT_STATE_MOVING_UP" 0 "SEAT_STATE_STOPPED" ;
VAL_ 739 VCRIGHT_seatStatus2Index 15 "SEAT_HEAT_3R_RIGHT" 14 "SEAT_3ROW_ADJUSTABLE_FOLD_FLAT" 13 "FRONT_SEAT_THIGH_SUPPORT" 12 "SEAT_2ROW_ADJUSTABLE_FOLD_FLAT_2" 11 "SEAT_2ROW_ADJUSTABLE_FOLD_FLAT" 10 "OCS_IEE" 9 "SEAT_2ROW_EASY_ENTRY" 8 "SEAT_SWITCH_VOLTAGES_2" 7 "SEAT_SWITCH_VOLTAGES_1" 6 "SEAT_2ROW_ACTUATOR" 5 "SEAT_HEAT_REARR_BACKREST" 4 "OCCUPANCY" 3 "SEAT_HEAT_REARR" 2 "SEAT_HEAT_REARC" 1 "SEAT_HEAT_REARL_CUSHION" 0 "SEAT_HEAT_FRONT" ;
VAL_ 739 VCRIGHT_frontSeatHeatCurrent 12 "SNA" ;
VAL_ 739 VC_AH_1RowRightSeatHeatVentHealt 2 "SEAT_HEAT_VENT_UNAVAILABLE" 1 "SEAT_HEAT_VENT_HEALTHY" 0 "SEAT_HEAT_VENT_HEALTH_UNKNOWN" ;
VAL_ 739 VCRIGHT_2RowSeatReclineState 15 "SEAT_ADJUSTABLE_FOLD_FLAT_STATE_SNA" 12 "SEAT_ADJUSTABLE_FOLD_FLAT_STATE_CALIBRATING_ABSOLUTE_SENSOR" 11 "SEAT_ADJUSTABLE_FOLD_FLAT_STATE_CALIBRATING_ZERO_POSITION" 10 "SEAT_ADJUSTABLE_FOLD_FLAT_STATE_WAITING_TO_CLEAR_FOR_UNFOLD" 9 "SEAT_ADJUSTABLE_FOLD_FLAT_STATE_WAITING_TO_CLEAR_FOR_FOLD" 8 "SEAT_ADJUSTABLE_FOLD_FLAT_STATE_MOVING_REARWARD_TO_POSITION" 7 "SEAT_ADJUSTABLE_FOLD_FLAT_STATE_MOVING_FORWARD_TO_POSITION" 6 "SEAT_ADJUSTABLE_FOLD_FLAT_STATE_UNFOLDING" 5 "SEAT_ADJUSTABLE_FOLD_FLAT_STATE_FOLDING" 4 "SEAT_ADJUSTABLE_FOLD_FLAT_STATE_ADJUSTING_REARWARD_FAST" 3 "SEAT_ADJUSTABLE_FOLD_FLAT_STATE_ADJUSTING_FORWARD_FAST" 2 "SEAT_ADJUSTABLE_FOLD_FLAT_STATE_ADJUSTING_REARWARD_COMFORT" 1 "SEAT_ADJUSTABLE_FOLD_FLAT_STATE_ADJUSTING_FORWARD_COMFORT" 0 "SEAT_ADJUSTABLE_FOLD_FLAT_STATE_STOPPED" ;
VAL_ 739 VCRIGHT_2RowSeatReclineAbsPosSwi 3 "SWITCH_FAULT" 2 "SWITCH_ON" 1 "SWITCH_OFF" 0 "SWITCH_SNA" ;
VAL_ 739 VCRIGHT_2RowSeatReclinePositionS 4 "SEAT_ADJUSTABLE_FOLD_FLAT_POSITION_STATE_SNA" 3 "SEAT_ADJUSTABLE_FOLD_FLAT_POSITION_STATE_UNKNOWN" 2 "SEAT_ADJUSTABLE_FOLD_FLAT_POSITION_STATE_UNSAFE_INTERMEDIATE" 1 "SEAT_ADJUSTABLE_FOLD_FLAT_POSITION_STATE_UNFOLDED" 0 "SEAT_ADJUSTABLE_FOLD_FLAT_POSITION_STATE_FOLDED" ;
VAL_ 739 VCRIGHT_2RowSeatReclineNextToggl 2 "SEAT_ADJUSTABLE_FOLD_FLAT_NEXT_TOGGLE_DIRECTION_SNA" 1 "SEAT_ADJUSTABLE_FOLD_FLAT_NEXT_TOGGLE_DIRECTION_UNFOLD" 0 "SEAT_ADJUSTABLE_FOLD_FLAT_NEXT_TOGGLE_DIRECTION_FOLD" ;
VAL_ 739 VCRIGHT_2RowSeat1RClashAvoidance 6 "SEAT_FOLD_FLAT_CLASH_AVOIDANCE_REASON_FRONT_SEAT_OCCUPANCY" 5 "SEAT_FOLD_FLAT_CLASH_AVOIDANCE_REASON_FRONT_SEAT_MOVING" 4 "SEAT_FOLD_FLAT_CLASH_AVOIDANCE_REASON_FRONT_SEAT_PROFILE_RECALL" 3 "SEAT_FOLD_FLAT_CLASH_AVOIDANCE_REASON_REAR_SEAT_UNCALIBRATED" 2 "SEAT_FOLD_FLAT_CLASH_AVOIDANCE_REASON_FRONT_SEAT_UNCALIBRATED" 1 "SEAT_FOLD_FLAT_CLASH_AVOIDANCE_REASON_VEHICLE_IN_MOTION" 0 "SEAT_FOLD_FLAT_CLASH_AVOIDANCE_REASON_NONE" ;
VAL_ 739 VCRIGHT_2RowSeat1RClashAvoi_0001 3 "SEAT_FOLD_FLAT_CLASH_AVOIDANCE_STATE_RESTORING_FRONT_SEAT" 2 "SEAT_FOLD_FLAT_CLASH_AVOIDANCE_STATE_WAITING_TO_RESTORE_FRONT_SEAT" 1 "SEAT_FOLD_FLAT_CLASH_AVOIDANCE_STATE_FRONT_SEAT_CLEARING" 0 "SEAT_FOLD_FLAT_CLASH_AVOIDANCE_STATE_IDLE" ;
VAL_ 739 VC_AH_2RowRightSeatMovementHealt 4 "SEAT_CALIBRATION_REQUIRED" 3 "SEAT_IN_NON_USE_POSITION" 2 "SEAT_CANNOT_MOVE" 1 "SEAT_MOVEMENT_HEALTHY" 0 "SEAT_MOVEMENT_HEALTH_UNKNOWN" ;
VAL_ 739 VCRIGHT_3RowSeatReclineState 15 "SEAT_ADJUSTABLE_FOLD_FLAT_STATE_SNA" 12 "SEAT_ADJUSTABLE_FOLD_FLAT_STATE_CALIBRATING_ABSOLUTE_SENSOR" 11 "SEAT_ADJUSTABLE_FOLD_FLAT_STATE_CALIBRATING_ZERO_POSITION" 10 "SEAT_ADJUSTABLE_FOLD_FLAT_STATE_WAITING_TO_CLEAR_FOR_UNFOLD" 9 "SEAT_ADJUSTABLE_FOLD_FLAT_STATE_WAITING_TO_CLEAR_FOR_FOLD" 8 "SEAT_ADJUSTABLE_FOLD_FLAT_STATE_MOVING_REARWARD_TO_POSITION" 7 "SEAT_ADJUSTABLE_FOLD_FLAT_STATE_MOVING_FORWARD_TO_POSITION" 6 "SEAT_ADJUSTABLE_FOLD_FLAT_STATE_UNFOLDING" 5 "SEAT_ADJUSTABLE_FOLD_FLAT_STATE_FOLDING" 4 "SEAT_ADJUSTABLE_FOLD_FLAT_STATE_ADJUSTING_REARWARD_FAST" 3 "SEAT_ADJUSTABLE_FOLD_FLAT_STATE_ADJUSTING_FORWARD_FAST" 2 "SEAT_ADJUSTABLE_FOLD_FLAT_STATE_ADJUSTING_REARWARD_COMFORT" 1 "SEAT_ADJUSTABLE_FOLD_FLAT_STATE_ADJUSTING_FORWARD_COMFORT" 0 "SEAT_ADJUSTABLE_FOLD_FLAT_STATE_STOPPED" ;
VAL_ 739 VCRIGHT_3RowSeatReclineNextToggl 2 "SEAT_ADJUSTABLE_FOLD_FLAT_NEXT_TOGGLE_DIRECTION_SNA" 1 "SEAT_ADJUSTABLE_FOLD_FLAT_NEXT_TOGGLE_DIRECTION_UNFOLD" 0 "SEAT_ADJUSTABLE_FOLD_FLAT_NEXT_TOGGLE_DIRECTION_FOLD" ;
VAL_ 739 VCRIGHT_3RowSeatReclinePositionS 4 "SEAT_ADJUSTABLE_FOLD_FLAT_POSITION_STATE_SNA" 3 "SEAT_ADJUSTABLE_FOLD_FLAT_POSITION_STATE_UNKNOWN" 2 "SEAT_ADJUSTABLE_FOLD_FLAT_POSITION_STATE_UNSAFE_INTERMEDIATE" 1 "SEAT_ADJUSTABLE_FOLD_FLAT_POSITION_STATE_UNFOLDED" 0 "SEAT_ADJUSTABLE_FOLD_FLAT_POSITION_STATE_FOLDED" ;
VAL_ 739 VCRIGHT_3RowSeatReclineAbsPosSwi 3 "SWITCH_FAULT" 2 "SWITCH_ON" 1 "SWITCH_OFF" 0 "SWITCH_SNA" ;
VAL_ 835 VCRIGHT_autonomyBehaviorStatus 2 "DRIVERLESS_NO_TAKEOVER" 1 "DRIVERLESS_TAKEOVER" 0 "DRIVER" ;
VAL_ 835 VCRIGHT_LVBatteryTypeDBG 5 "LV_BATTERY_TYPE_TESLA_48V_LI_ION" 4 "LV_BATTERY_TYPE_TESLA_16V_LI_ION" 3 "LV_BATTERY_TYPE_CATL_LI_ION" 2 "LV_BATTERY_TYPE_CLARIOS_B24_FLOODED" 1 "LV_BATTERY_TYPE_ATLASBX_B24_FLOODED" 0 "LV_BATTERY_TYPE_UNKNOWN" ;
VAL_ 835 VCRIGHT_rearDefrostState 4 "HEATER_STATE_FAULT" 3 "HEATER_STATE_OFF_UNAVAILABLE" 2 "HEATER_STATE_OFF" 1 "HEATER_STATE_ON" 0 "HEATER_STATE_SNA" ;
VAL_ 835 VCRIGHT_mirrorHeatState 4 "HEATER_STATE_FAULT" 3 "HEATER_STATE_OFF_UNAVAILABLE" 2 "HEATER_STATE_OFF" 1 "HEATER_STATE_ON" 0 "HEATER_STATE_SNA" ;
VAL_ 835 VCRIGHT_steeringWheelHeaterDCTgt 127 "SNA" ;
VAL_ 963 VCRIGHT_switchStatusIndex 1 "1" 0 "0" ;
VAL_ 963 VCRIGHT_frontBuckleSwitch 3 "SWITCH_FAULT" 2 "SWITCH_ON" 1 "SWITCH_OFF" 0 "SWITCH_SNA" ;
VAL_ 963 VCRIGHT_rearCenterBuckleSwitch 3 "SWITCH_FAULT" 2 "SWITCH_ON" 1 "SWITCH_OFF" 0 "SWITCH_SNA" ;
VAL_ 963 VCRIGHT_rearRightBuckleSwitch 3 "SWITCH_FAULT" 2 "SWITCH_ON" 1 "SWITCH_OFF" 0 "SWITCH_SNA" ;
VAL_ 963 VCRIGHT_frontSeatTrackBack 3 "SWITCH_FAULT" 2 "SWITCH_ON" 1 "SWITCH_OFF" 0 "SWITCH_SNA" ;
VAL_ 963 VCRIGHT_frontSeatTrackForward 3 "SWITCH_FAULT" 2 "SWITCH_ON" 1 "SWITCH_OFF" 0 "SWITCH_SNA" ;
VAL_ 963 VCRIGHT_frontSeatTiltDown 3 "SWITCH_FAULT" 2 "SWITCH_ON" 1 "SWITCH_OFF" 0 "SWITCH_SNA" ;
VAL_ 963 VCRIGHT_frontSeatTiltUp 3 "SWITCH_FAULT" 2 "SWITCH_ON" 1 "SWITCH_OFF" 0 "SWITCH_SNA" ;
VAL_ 963 VCRIGHT_frontSeatLiftDown 3 "SWITCH_FAULT" 2 "SWITCH_ON" 1 "SWITCH_OFF" 0 "SWITCH_SNA" ;
VAL_ 963 VCRIGHT_frontSeatLiftUp 3 "SWITCH_FAULT" 2 "SWITCH_ON" 1 "SWITCH_OFF" 0 "SWITCH_SNA" ;
VAL_ 963 VCRIGHT_frontSeatBackrestBack 3 "SWITCH_FAULT" 2 "SWITCH_ON" 1 "SWITCH_OFF" 0 "SWITCH_SNA" ;
VAL_ 963 VCRIGHT_frontSeatBackrestForward 3 "SWITCH_FAULT" 2 "SWITCH_ON" 1 "SWITCH_OFF" 0 "SWITCH_SNA" ;
VAL_ 963 VCRIGHT_frontSeatLumbarDown 3 "SWITCH_FAULT" 2 "SWITCH_ON" 1 "SWITCH_OFF" 0 "SWITCH_SNA" ;
VAL_ 963 VCRIGHT_frontSeatLumbarUp 3 "SWITCH_FAULT" 2 "SWITCH_ON" 1 "SWITCH_OFF" 0 "SWITCH_SNA" ;
VAL_ 963 VCRIGHT_frontSeatLumbarIn 3 "SWITCH_FAULT" 2 "SWITCH_ON" 1 "SWITCH_OFF" 0 "SWITCH_SNA" ;
VAL_ 963 VCRIGHT_frontSeatLumbarOut 3 "SWITCH_FAULT" 2 "SWITCH_ON" 1 "SWITCH_OFF" 0 "SWITCH_SNA" ;
VAL_ 963 VCRIGHT_frontSeatThighSupportExt 3 "SWITCH_FAULT" 2 "SWITCH_ON" 1 "SWITCH_OFF" 0 "SWITCH_SNA" ;
VAL_ 963 VCRIGHT_frontSeatALR 3 "SWITCH_FAULT" 2 "SWITCH_ON" 1 "SWITCH_OFF" 0 "SWITCH_SNA" ;
VAL_ 963 VCRIGHT_frontSeatResistiveOccupa 3 "SWITCH_FAULT" 2 "SWITCH_ON" 1 "SWITCH_OFF" 0 "SWITCH_SNA" ;
VAL_ 963 VCRIGHT_2RowSeatReclineSwitchpac 6 "FAULT" 5 "REARWARD_FAST" 4 "REARWARD_SLOW" 3 "FORWARD_FAST" 2 "FORWARD_SLOW" 1 "INACTIVE" 0 "DISCONNECTED" ;
VAL_ 963 VCRIGHT_frontSeatThighSupportRet 3 "SWITCH_FAULT" 2 "SWITCH_ON" 1 "SWITCH_OFF" 0 "SWITCH_SNA" ;
VAL_ 899 VCRIGHT_thsTemperature 255 "SNA" ;
VAL_ 899 VCRIGHT_thsState 4 "IDLE" 3 "WAIT_CRC_RESPONSE" 2 "WAIT_CRC_REQUEST" 1 "CONFIG" 0 "INIT" ;
VAL_ 899 VCRIGHT_thsLINCurrentSchedule 7 "OTHER" 3 "DIAGNOSTIC" 2 "CONFIG" 1 "MAIN" 0 "OFF" ;
VAL_ 899 VCRIGHT_thsHumidity 127 "SNA" ;
VAL_ 899 VCRIGHT_estimatedVehicleSituatio 2 "VEHICLE_SITUATION_OUTDOOR" 1 "VEHICLE_SITUATION_INDOOR" 0 "VEHICLE_SITUATION_UNKNOWN" ;
VAL_ 899 VCRIGHT_thsSolarLoadInfrared 1023 "SNA" ;
VAL_ 899 VCRIGHT_thsSolarLoadVisible 1023 "SNA" ;
VAL_ 899 VCRIGHT_estimatedThsSolarLoad 1023 "SNA" ;
VAL_ 1059 VCRIGHT_nmKeepAwakeReason 31 "VCRIGHT_KEEPAWAKE_REASON_MULTIPLE" 17 "VCRIGHT_KEEPAWAKE_REASON_DEFOG_CMD" 16 "VCRIGHT_KEEPAWAKE_REASON_DEFOG_CAMERA" 15 "VCRIGHT_KEEPAWAKE_REASON_VOC_PURGE" 14 "VCRIGHT_KEEPAWAKE_REASON_OTHER" 12 "VCRIGHT_KEEPAWAKE_REASON_TRUNK_SWITCH" 11 "VCRIGHT_KEEPAWAKE_REASON_HVAC_EVAP_DRYING" 10 "VCRIGHT_KEEPAWAKE_REASON_UDS_ACTIVE" 9 "VCRIGHT_KEEPAWAKE_REASON_TRUNK_LIGHT" 8 "VCRIGHT_KEEPAWAKE_REASON_SEAT" 7 "VCRIGHT_KEEPAWAKE_REASON_HANDLE" 6 "VCRIGHT_KEEPAWAKE_REASON_EPB_SUMMON_ACTIVE" 5 "VCRIGHT_KEEPAWAKE_REASON_CLOSURE_LATCH" 4 "VCRIGHT_KEEPAWAKE_REASON_HVAC_PRECONDITIONING" 3 "VCRIGHT_KEEPAWAKE_REASON_HVAC_CABIN_PURGE" 2 "VCRIGHT_KEEPAWAKE_REASON_EPB_NOT_SECURE" 1 "VCRIGHT_KEEPAWAKE_REASON_EPB_STATE_NOT_SAVED" 0 "VCRIGHT_KEEPAWAKE_REASON_NONE_SNA" ;
VAL_ 1059 VCRIGHT_nmWakeUpReason 15 "VCRIGHT_WAKEUP_REASON_UNKNOWN" 14 "VCRIGHT_WAKEUP_REASON_DEFOG_CMD" 13 "VCRIGHT_WAKEUP_REASON_DEFOG_CAMERA" 12 "VCRIGHT_WAKEUP_REASON_VOC_PURGE" 11 "VCRIGHT_WAKEUP_REASON_POWER_ON_RESET" 10 "VCRIGHT_WAKEUP_REASON_CABIN_HOT" 9 "VCRIGHT_WAKEUP_REASON_TRUNK_LATCH" 8 "VCRIGHT_WAKEUP_REASON_TRUNK_SWITCH" 7 "VCRIGHT_WAKEUP_REASON_LIN_RX" 6 "VCRIGHT_WAKEUP_REASON_EXTERIOR_HANDLE" 5 "VCRIGHT_WAKEUP_REASON_INTERIOR_HANDLE" 4 "VCRIGHT_WAKEUP_REASON_DOOR_LATCH" 3 "VCRIGHT_WAKEUP_REASON_RESET" 2 "VCRIGHT_WAKEUP_REASON_SWITCH_INPUT" 1 "VCRIGHT_WAKEUP_REASON_ECU_SPECIFIC" 0 "VCRIGHT_WAKEUP_REASON_NONE" ;
VAL_ 1059 VCRIGHT_nmDebugWakeUp 2147483648 "WKPU_31" 1073741824 "WKPU_30" 536870912 "WKPU_29" 268435456 "WKPU_28" 134217728 "WKPU_27" 67108864 "WKPU_26" 33554432 "WKPU_25" 16777216 "WKPU_24" 8388608 "WKPU_23" 4194304 "WKPU_22" 2097152 "WKPU_21" 1048576 "WKPU_20" 524288 "WKPU_19" 262144 "WKPU_18" 131072 "WKPU_17" 65536 "WKPU_16" 32768 "WKPU_15" 16384 "WKPU_14" 8192 "WKPU_13" 4096 "WKPU_12" 2048 "WKPU_11" 1024 "WKPU_10" 512 "WKPU_9" 256 "WKPU_8" 128 "WKPU_7" 64 "WKPU_6" 32 "WKPU_5" 16 "WKPU_4" 8 "WKPU_3" 4 "WKPU_2" 2 "WKPU_1" 1 "WKPU_0" 0 "WKPU_NONE" ;
VAL_ 1059 VCRIGHT_nmEthKeepAwakeReason 15 "VCRIGHT_ETH_KEEPAWAKE_REASON_MULTIPLE" 14 "VCRIGHT_ETH_KEEPAWAKE_REASON_OTHER" 6 "VCRIGHT_ETH_KEEPAWAKE_REASON_TEMP_SENSE_COP_VARIANT_ACTIVE" 5 "VCRIGHT_ETH_KEEPAWAKE_REASON_TEMP_SENSE_POLL" 4 "VCRIGHT_ETH_KEEPAWAKE_REASON_TEMP_SENSE_VCSEC_WAKE" 3 "VCRIGHT_ETH_KEEPAWAKE_REASON_TEMP_SENSE_DWELL_TIME_END" 2 "VCRIGHT_ETH_KEEPAWAKE_REASON_TEMP_SENSE_TRANSITION_FROM_OFF" 1 "VCRIGHT_ETH_KEEPAWAKE_REASON_TEMP_SENSE_TRANSITION_FROM_ACC" 0 "VCRIGHT_ETH_KEEPAWAKE_REASON_NONE_SNA" ;
VAL_ 1059 VCRIGHT_nmChKeepAwakeReason 15 "VCRIGHT_CH_KEEPAWAKE_REASON_MULTIPLE" 14 "VCRIGHT_CH_KEEPAWAKE_REASON_OTHER" 2 "VCRIGHT_CH_KEEPAWAKE_REASON_DEFOG_CMD" 1 "VCRIGHT_CH_KEEPAWAKE_REASON_DEFOG_CAMERA" 0 "VCRIGHT_CH_KEEPAWAKE_REASON_NONE_SNA" ;
VAL_ 707 VCRIGHT_windowStatusIndex 1 "Mux1" 0 "Mux0" ;
VAL_ 707 VCRIGHT_windowStateRF 10 "WINDOW_STATE_SHORT_RISE_REVERSE" 9 "WINDOW_STATE_SHORT_RISE" 8 "WINDOW_STATE_BACKDRIVE" 7 "WINDOW_STATE_MOVING_AUTO_DOWN" 6 "WINDOW_STATE_MOVING_AUTO_UP" 5 "WINDOW_STATE_SHORT_DROP_REVERSE" 4 "WINDOW_STATE_SHORT_DROP" 3 "WINDOW_STATE_BACKOFF" 2 "WINDOW_STATE_MOVING_DOWN" 1 "WINDOW_STATE_MOVING_UP" 0 "WINDOW_STATE_STOPPED" ;
VAL_ 707 VCRIGHT_windowTrimClearMoveReque 3 "WINDOW_TRIM_CLEAR_MOVE_REQUEST_BACKDRIVE" 2 "WINDOW_TRIM_CLEAR_MOVE_REQUEST_RESEAL" 1 "WINDOW_TRIM_CLEAR_MOVE_REQUEST_IDLE" 0 "WINDOW_TRIM_CLEAR_MOVE_REQUEST_SNA" ;
VAL_ 707 VCRIGHT_windowTrimClearActiveReq 2 "WINDOW_TRIM_CLEAR_ACTIVE_REQUEST_ACTIVE" 1 "WINDOW_TRIM_CLEAR_ACTIVE_REQUEST_INACTIVE" 0 "WINDOW_TRIM_CLEAR_ACTIVE_REQUEST_SNA" ;
VAL_ 707 VCRIGHT_windowPositionRF 1 "SNA" ;
VAL_ 707 VCRIGHT_windowStateRR 10 "WINDOW_STATE_SHORT_RISE_REVERSE" 9 "WINDOW_STATE_SHORT_RISE" 8 "WINDOW_STATE_BACKDRIVE" 7 "WINDOW_STATE_MOVING_AUTO_DOWN" 6 "WINDOW_STATE_MOVING_AUTO_UP" 5 "WINDOW_STATE_SHORT_DROP_REVERSE" 4 "WINDOW_STATE_SHORT_DROP" 3 "WINDOW_STATE_BACKOFF" 2 "WINDOW_STATE_MOVING_DOWN" 1 "WINDOW_STATE_MOVING_UP" 0 "WINDOW_STATE_STOPPED" ;
VAL_ 707 VCRIGHT_windowThermalModeRF 3 "WINDOW_THERMAL_MODE_CRITICAL" 2 "WINDOW_THERMAL_MODE_ALERT" 1 "WINDOW_THERMAL_MODE_NORMAL" 0 "WINDOW_THERMAL_MODE_SNA" ;
VAL_ 707 VCRIGHT_windowStopReasonRF 6 "WINDOW_STOP_REASON_STATE_TIMEOUT" 5 "WINDOW_STOP_REASON_FULL_OPEN_SOFT_STOP" 4 "WINDOW_STOP_REASON_STOP_REQUEST" 3 "WINDOW_STOP_REASON_TARGET_REACHED" 2 "WINDOW_STOP_REASON_NEW_REQUEST" 1 "WINDOW_STOP_REASON_DOOR_OPEN_TRIM_PROTECT" 0 "WINDOW_STOP_REASON_NONE" ;
VAL_ 707 VCRIGHT_windowStopReqReasonRF 8 "WINDOW_STOP_REQUEST_REASON_EXTERNAL_REQUEST" 7 "WINDOW_STOP_REQUEST_REASON_FULL_OPEN_SOFT_STOP" 6 "WINDOW_STOP_REQUEST_REASON_STATE_TIMEOUT" 5 "WINDOW_STOP_REQUEST_REASON_STALL" 4 "WINDOW_STOP_REQUEST_REASON_THERMAL" 3 "WINDOW_STOP_REQUEST_REASON_REAR_LOCKOUT" 2 "WINDOW_STOP_REQUEST_REASON_SWITCH_RELEASED" 1 "WINDOW_STOP_REQUEST_REASON_SWITCH_CANCEL_AUTO_MOVEMENT" 0 "WINDOW_STOP_REQUEST_REASON_NONE" ;
VAL_ 707 VCRIGHT_windowThermalModeRR 3 "WINDOW_THERMAL_MODE_CRITICAL" 2 "WINDOW_THERMAL_MODE_ALERT" 1 "WINDOW_THERMAL_MODE_NORMAL" 0 "WINDOW_THERMAL_MODE_SNA" ;
VAL_ 707 VCRIGHT_windowStopReasonRR 6 "WINDOW_STOP_REASON_STATE_TIMEOUT" 5 "WINDOW_STOP_REASON_FULL_OPEN_SOFT_STOP" 4 "WINDOW_STOP_REASON_STOP_REQUEST" 3 "WINDOW_STOP_REASON_TARGET_REACHED" 2 "WINDOW_STOP_REASON_NEW_REQUEST" 1 "WINDOW_STOP_REASON_DOOR_OPEN_TRIM_PROTECT" 0 "WINDOW_STOP_REASON_NONE" ;
VAL_ 707 VCRIGHT_windowStopReqReasonRR 8 "WINDOW_STOP_REQUEST_REASON_EXTERNAL_REQUEST" 7 "WINDOW_STOP_REQUEST_REASON_FULL_OPEN_SOFT_STOP" 6 "WINDOW_STOP_REQUEST_REASON_STATE_TIMEOUT" 5 "WINDOW_STOP_REQUEST_REASON_STALL" 4 "WINDOW_STOP_REQUEST_REASON_THERMAL" 3 "WINDOW_STOP_REQUEST_REASON_REAR_LOCKOUT" 2 "WINDOW_STOP_REQUEST_REASON_SWITCH_RELEASED" 1 "WINDOW_STOP_REQUEST_REASON_SWITCH_CANCEL_AUTO_MOVEMENT" 0 "WINDOW_STOP_REQUEST_REASON_NONE" ;
VAL_ 707 VCRIGHT_windowControlStateRF 2 "WINDOW_CONTROL_STATE_GOING_TO_POSITION" 1 "WINDOW_CONTROL_STATE_CLOSING" 0 "WINDOW_CONTROL_STATE_IDLE" ;
VAL_ 707 VCRIGHT_windowCtrlUnavailableRF 7 "WINDOW_CONTROL_UNAVAILABLE_REASON_WINDOW_MOVING" 6 "WINDOW_CONTROL_UNAVAILABLE_REASON_VEHICLE_IN_DRIVE" 5 "WINDOW_CONTROL_UNAVAILABLE_REASON_UNCALIBRATED" 4 "WINDOW_CONTROL_UNAVAILABLE_REASON_THERMAL_LIMIT" 3 "WINDOW_CONTROL_UNAVAILABLE_REASON_PINCH" 2 "WINDOW_CONTROL_UNAVAILABLE_REASON_SWITCH_PRESSED" 1 "WINDOW_CONTROL_UNAVAILABLE_REASON_UNEXPECTED" 0 "WINDOW_CONTROL_UNAVAILABLE_REASON_NONE" ;
VAL_ 707 VCRIGHT_windowControlStateRR 2 "WINDOW_CONTROL_STATE_GOING_TO_POSITION" 1 "WINDOW_CONTROL_STATE_CLOSING" 0 "WINDOW_CONTROL_STATE_IDLE" ;
VAL_ 707 VCRIGHT_windowCtrlUnavailableRR 7 "WINDOW_CONTROL_UNAVAILABLE_REASON_WINDOW_MOVING" 6 "WINDOW_CONTROL_UNAVAILABLE_REASON_VEHICLE_IN_DRIVE" 5 "WINDOW_CONTROL_UNAVAILABLE_REASON_UNCALIBRATED" 4 "WINDOW_CONTROL_UNAVAILABLE_REASON_THERMAL_LIMIT" 3 "WINDOW_CONTROL_UNAVAILABLE_REASON_PINCH" 2 "WINDOW_CONTROL_UNAVAILABLE_REASON_SWITCH_PRESSED" 1 "WINDOW_CONTROL_UNAVAILABLE_REASON_UNEXPECTED" 0 "WINDOW_CONTROL_UNAVAILABLE_REASON_NONE" ;
VAL_ 707 VCRIGHT_windowPositionStateRF 7 "WINDOW_POSITION_CLOSED_TRIM_CLEAR" 6 "WINDOW_POSITION_FULL_OPEN" 5 "WINDOW_POSITION_PARTIAL_OPEN" 4 "WINDOW_POSITION_DAS_LIMITED" 3 "WINDOW_POSITION_VENT" 2 "WINDOW_POSITION_CRACKED" 1 "WINDOW_POSITION_CLOSED" 0 "WINDOW_POSITION_UNKNOWN" ;
VAL_ 707 VCRIGHT_windowPositionStateRR 7 "WINDOW_POSITION_CLOSED_TRIM_CLEAR" 6 "WINDOW_POSITION_FULL_OPEN" 5 "WINDOW_POSITION_PARTIAL_OPEN" 4 "WINDOW_POSITION_DAS_LIMITED" 3 "WINDOW_POSITION_VENT" 2 "WINDOW_POSITION_CRACKED" 1 "WINDOW_POSITION_CLOSED" 0 "WINDOW_POSITION_UNKNOWN" ;
VAL_ 707 VCRIGHT_windowVehGearStateRF 2 "WINDOW_VEHICLE_GEAR_STATE_IN_GEAR" 1 "WINDOW_VEHICLE_GEAR_STATE_PARK" 0 "WINDOW_VEHICLE_GEAR_STATE_UNKNOWN_SNA" ;
VAL_ 707 VCRIGHT_windowVehGearStateRR 2 "WINDOW_VEHICLE_GEAR_STATE_IN_GEAR" 1 "WINDOW_VEHICLE_GEAR_STATE_PARK" 0 "WINDOW_VEHICLE_GEAR_STATE_UNKNOWN_SNA" ;
VAL_ 707 VCRIGHT_windowSpeedTableStatusRF 2 "WINDOW_SPEED_TABLE_STATUS_FULLY_BUILT" 1 "WINDOW_SPEED_TABLE_STATUS_SENSITIVE_BUILT" 0 "WINDOW_SPEED_TABLE_STATUS_EMPTY_SNA" ;
VAL_ 707 VCRIGHT_windowSpeedTableStatusRR 2 "WINDOW_SPEED_TABLE_STATUS_FULLY_BUILT" 1 "WINDOW_SPEED_TABLE_STATUS_SENSITIVE_BUILT" 0 "WINDOW_SPEED_TABLE_STATUS_EMPTY_SNA" ;
VAL_ 969 VCSEC_BLEEndpointInfoIndex 127 "MAX_VALUE_FOR_COEX" 38 "BLELeftRearAppGithash" 37 "BLELeftRearGeneology" 36 "BLELeftRearInfo" 35 "BLENFCCradleAppGithash" 34 "BLENFCCradleGeneology" 33 "BLENFCCradleInfo" 32 "BLERightRearAppGithash" 31 "BLERightRearGeneology" 30 "BLERightRearInfo" 29 "UWBCenterAppGithash" 28 "UWBCenterGeneology" 27 "UWBCenterInfo" 26 "UWBLeftAppGithash" 25 "UWBLeftGeneology" 24 "UWBLeftInfo" 23 "UWBRearAppGithash" 22 "UWBRearGeneology" 21 "UWBRearInfo" 20 "UWBRearLeftAppGithash" 19 "UWBRearLeftGeneology" 18 "UWBRearLeftInfo" 17 "UWBRearRightAppGithash" 16 "UWBRearRightGeneology" 15 "UWBRearRightInfo" 14 "UWBRightAppGithash" 13 "UWBRightGeneology" 12 "UWBRightInfo" 11 "BLERearInfo" 10 "BLERearGeneology" 9 "BLERearAppGithash" 8 "BLERightInfo" 7 "BLERightGeneology" 6 "BLERightAppGithash" 5 "BLELeftInfo" 4 "BLELeftGeneology" 3 "BLELeftAppGithash" 2 "BLECenterInfo" 1 "BLECenterGeneology" 0 "BLECenterAppGithash" ;
VAL_ 969 VCSEC_UWBRightRadioConfigState 13 "DONE_VERIFYING_RADIO_CONFIG" 12 "WAIT_FOR_LOOPBACK_CALIBRATION" 11 "START_LOOPBACK_CALIBRATION" 10 "WAIT_FOR_PROGRAM_FLASH" 9 "PROGRAM_FLASH" 8 "WAIT_FOR_DOWNLOAD_DATA" 7 "DOWNLOAD_DATA" 6 "WAIT_FOR_INIT_CONFIGURATION" 5 "INIT_CONFIGURATION" 4 "PREPARE_UPDATE" 3 "WAIT_TO_GET_CURRENT_CRC" 2 "GET_CURRENT_CRC" 1 "WAIT_AFTER_TRIGGER" 0 "WAIT_FOR_TRIGGER" ;
VAL_ 969 VCSEC_UWBRightUpdateStatus 7 "SNA" 3 "IN_PROGRESS" 2 "FAIL" 1 "UP_TO_DATE" 0 "NOT_STARTED" ;
VAL_ 969 VCSEC_UWBRearRightRadioConfigSta 13 "DONE_VERIFYING_RADIO_CONFIG" 12 "WAIT_FOR_LOOPBACK_CALIBRATION" 11 "START_LOOPBACK_CALIBRATION" 10 "WAIT_FOR_PROGRAM_FLASH" 9 "PROGRAM_FLASH" 8 "WAIT_FOR_DOWNLOAD_DATA" 7 "DOWNLOAD_DATA" 6 "WAIT_FOR_INIT_CONFIGURATION" 5 "INIT_CONFIGURATION" 4 "PREPARE_UPDATE" 3 "WAIT_TO_GET_CURRENT_CRC" 2 "GET_CURRENT_CRC" 1 "WAIT_AFTER_TRIGGER" 0 "WAIT_FOR_TRIGGER" ;
VAL_ 969 VCSEC_UWBRearRightUpdateStatus 7 "SNA" 3 "IN_PROGRESS" 2 "FAIL" 1 "UP_TO_DATE" 0 "NOT_STARTED" ;
VAL_ 969 VCSEC_UWBRearLeftRadioConfigStat 13 "DONE_VERIFYING_RADIO_CONFIG" 12 "WAIT_FOR_LOOPBACK_CALIBRATION" 11 "START_LOOPBACK_CALIBRATION" 10 "WAIT_FOR_PROGRAM_FLASH" 9 "PROGRAM_FLASH" 8 "WAIT_FOR_DOWNLOAD_DATA" 7 "DOWNLOAD_DATA" 6 "WAIT_FOR_INIT_CONFIGURATION" 5 "INIT_CONFIGURATION" 4 "PREPARE_UPDATE" 3 "WAIT_TO_GET_CURRENT_CRC" 2 "GET_CURRENT_CRC" 1 "WAIT_AFTER_TRIGGER" 0 "WAIT_FOR_TRIGGER" ;
VAL_ 969 VCSEC_UWBRearLeftUpdateStatus 7 "SNA" 3 "IN_PROGRESS" 2 "FAIL" 1 "UP_TO_DATE" 0 "NOT_STARTED" ;
VAL_ 969 VCSEC_UWBRearRadioConfigState 13 "DONE_VERIFYING_RADIO_CONFIG" 12 "WAIT_FOR_LOOPBACK_CALIBRATION" 11 "START_LOOPBACK_CALIBRATION" 10 "WAIT_FOR_PROGRAM_FLASH" 9 "PROGRAM_FLASH" 8 "WAIT_FOR_DOWNLOAD_DATA" 7 "DOWNLOAD_DATA" 6 "WAIT_FOR_INIT_CONFIGURATION" 5 "INIT_CONFIGURATION" 4 "PREPARE_UPDATE" 3 "WAIT_TO_GET_CURRENT_CRC" 2 "GET_CURRENT_CRC" 1 "WAIT_AFTER_TRIGGER" 0 "WAIT_FOR_TRIGGER" ;
VAL_ 969 VCSEC_UWBRearUpdateStatus 7 "SNA" 3 "IN_PROGRESS" 2 "FAIL" 1 "UP_TO_DATE" 0 "NOT_STARTED" ;
VAL_ 969 VCSEC_UWBLeftRadioConfigState 13 "DONE_VERIFYING_RADIO_CONFIG" 12 "WAIT_FOR_LOOPBACK_CALIBRATION" 11 "START_LOOPBACK_CALIBRATION" 10 "WAIT_FOR_PROGRAM_FLASH" 9 "PROGRAM_FLASH" 8 "WAIT_FOR_DOWNLOAD_DATA" 7 "DOWNLOAD_DATA" 6 "WAIT_FOR_INIT_CONFIGURATION" 5 "INIT_CONFIGURATION" 4 "PREPARE_UPDATE" 3 "WAIT_TO_GET_CURRENT_CRC" 2 "GET_CURRENT_CRC" 1 "WAIT_AFTER_TRIGGER" 0 "WAIT_FOR_TRIGGER" ;
VAL_ 969 VCSEC_UWBLeftUpdateStatus 7 "SNA" 3 "IN_PROGRESS" 2 "FAIL" 1 "UP_TO_DATE" 0 "NOT_STARTED" ;
VAL_ 969 VCSEC_UWBCenterRadioConfigState 13 "DONE_VERIFYING_RADIO_CONFIG" 12 "WAIT_FOR_LOOPBACK_CALIBRATION" 11 "START_LOOPBACK_CALIBRATION" 10 "WAIT_FOR_PROGRAM_FLASH" 9 "PROGRAM_FLASH" 8 "WAIT_FOR_DOWNLOAD_DATA" 7 "DOWNLOAD_DATA" 6 "WAIT_FOR_INIT_CONFIGURATION" 5 "INIT_CONFIGURATION" 4 "PREPARE_UPDATE" 3 "WAIT_TO_GET_CURRENT_CRC" 2 "GET_CURRENT_CRC" 1 "WAIT_AFTER_TRIGGER" 0 "WAIT_FOR_TRIGGER" ;
VAL_ 969 VCSEC_UWBCenterUpdateStatus 7 "SNA" 3 "IN_PROGRESS" 2 "FAIL" 1 "UP_TO_DATE" 0 "NOT_STARTED" ;
VAL_ 607 VCSEC_childSeat0_connectionState 5 "DISCONNECTING" 4 "CONNECTED" 3 "WAIT_FOR_CONNECTION" 2 "CONNECTION_REQUEST" 1 "WAIT_FOR_ADV" 0 "INVALID" ;
VAL_ 607 VCSEC_childSeat0_taskDisconnecti 3 "CONNECTION_STATE_MISMATCH" 2 "BAD_CONNECTION_DROPPED" 1 "REQUESTED" 0 "NONE" ;
VAL_ 607 VCSEC_childSeat0_state 8 "DEVICE_READY" 7 "DEVICE_READ_STATUS_WAIT_FOR_RESPONSE" 6 "DEVICE_READ_STATUS" 5 "DEVICE_SIGNUP_NOTIFICATION_WAIT_FOR_RESPONSE" 4 "DEVICE_SIGNUP_NOTIFICATION" 3 "DEVICE_INIT_RESPONSE" 2 "DEVICE_INIT_WAIT_FOR_RESPONSE" 1 "DEVICE_INIT_REQUEST" 0 "DEVICE_IDLE" ;
VAL_ 607 VCSEC_childSeat0_taskErrorCode 4 "TIMEOUT" 3 "READ_STATUS_ERROR" 2 "SIGN_UP_NOTIFICATION_ERROR" 1 "INIT_ERROR" 0 "NONE" ;
VAL_ 607 VCSEC_childSeat0_RSSI 127 "SNA" ;
VAL_ 607 VCSEC_childSeat0_ISOFixStatus 2 "INSTALLED" 1 "NOT_INSTALLED" 0 "INVALID" ;
VAL_ 607 VCSEC_childSeat0_buckleStatus 2 "BUCKLED" 1 "NOT_BUCKLED" 0 "INVALID" ;
VAL_ 607 VCSEC_childSeat0_occupancyStatus 2 "OCCUPIED" 1 "NOT_OCCUPIED" 0 "INVALID" ;
VAL_ 607 VCSEC_childSeat1_connectionState 5 "DISCONNECTING" 4 "CONNECTED" 3 "WAIT_FOR_CONNECTION" 2 "CONNECTION_REQUEST" 1 "WAIT_FOR_ADV" 0 "INVALID" ;
VAL_ 607 VCSEC_childSeat1_taskDisconnecti 3 "CONNECTION_STATE_MISMATCH" 2 "BAD_CONNECTION_DROPPED" 1 "REQUESTED" 0 "NONE" ;
VAL_ 607 VCSEC_childSeat1_state 8 "DEVICE_READY" 7 "DEVICE_READ_STATUS_WAIT_FOR_RESPONSE" 6 "DEVICE_READ_STATUS" 5 "DEVICE_SIGNUP_NOTIFICATION_WAIT_FOR_RESPONSE" 4 "DEVICE_SIGNUP_NOTIFICATION" 3 "DEVICE_INIT_RESPONSE" 2 "DEVICE_INIT_WAIT_FOR_RESPONSE" 1 "DEVICE_INIT_REQUEST" 0 "DEVICE_IDLE" ;
VAL_ 607 VCSEC_childSeat1_taskErrorCode 4 "TIMEOUT" 3 "READ_STATUS_ERROR" 2 "SIGN_UP_NOTIFICATION_ERROR" 1 "INIT_ERROR" 0 "NONE" ;
VAL_ 607 VCSEC_childSeat1_RSSI 127 "SNA" ;
VAL_ 607 VCSEC_childSeat1_ISOFixStatus 2 "INSTALLED" 1 "NOT_INSTALLED" 0 "INVALID" ;
VAL_ 607 VCSEC_childSeat1_buckleStatus 2 "BUCKLED" 1 "NOT_BUCKLED" 0 "INVALID" ;
VAL_ 607 VCSEC_childSeat1_occupancyStatus 2 "OCCUPIED" 1 "NOT_OCCUPIED" 0 "INVALID" ;
VAL_ 607 VCSEC_childSeatScanStatus 2 "TIMEOUT" 1 "SCANNING" 0 "IDLE" ;
VAL_ 607 VCSEC_childPresenceDetectionStat 8 "ESCALATED_WARNING" 7 "INTERVENTION" 6 "INITIAL_WARNING" 5 "ARMED" 4 "WAIT_FOR_LOCK" 3 "IDLE" 2 "DEACTIVE" 1 "FAULTED" 0 "NOT_CONFIGURED" ;
VAL_ 607 VCSEC_childPresenceDetectionSupp 2 "EU_REG" 1 "CN_REG" 0 "NONE" ;
